[part 1 of 2: package /ECUCompositionTypes]
AUTOSAR XML (schema 4-0-3)
package /ECUCompositionTypes
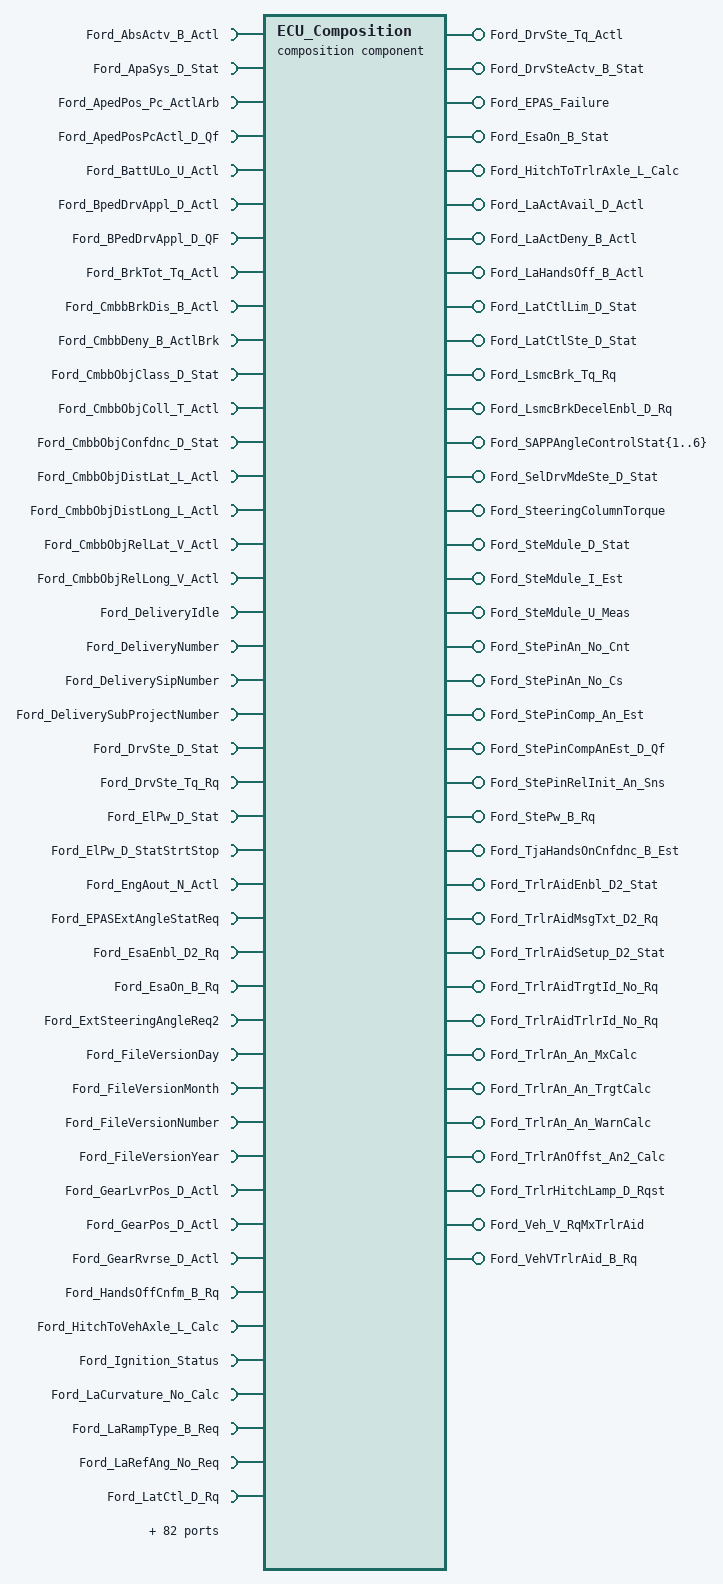
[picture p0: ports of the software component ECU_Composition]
  composition sw component type ECU_Composition
    42 x provide port:
      Ford_DrvSte_Tq_Actl: nonqueued-sender-com-spec{data-element=Ford_DrvSte_Tq_Actl, init-value=128}, provided-interface=Ford_DrvSte_Tq_Actl
      Ford_DrvSteActv_B_Stat: nonqueued-sender-com-spec{data-element=Ford_DrvSteActv_B_Stat, init-value=0}, provided-interface=Ford_DrvSteActv_B_Stat
      Ford_EPAS_Failure: nonqueued-sender-com-spec{data-element=Ford_EPAS_Failure, init-value=0}, provided-interface=Ford_EPAS_Failure
      Ford_EsaOn_B_Stat: provided-interface=Ford_EsaOn_B_Stat
      Ford_HitchToTrlrAxle_L_Calc: nonqueued-sender-com-spec{data-element=Ford_HitchToTrlrAxle_L_Calc, init-value=0}, provided-interface=Ford_HitchToTrlrAxle_L_Calc
      Ford_LaActAvail_D_Actl: nonqueued-sender-com-spec{data-element=Ford_LaActAvail_D_Actl, init-value=0}, provided-interface=Ford_LaActAvail_D_Actl
      Ford_LaActDeny_B_Actl: nonqueued-sender-com-spec{data-element=Ford_LaActDeny_B_Actl, init-value=0}, provided-interface=Ford_LaActDeny_B_Actl
      Ford_LaHandsOff_B_Actl: nonqueued-sender-com-spec{data-element=Ford_LaHandsOff_B_Actl, init-value=1}, provided-interface=Ford_LaHandsOff_B_Actl
      Ford_LatCtlLim_D_Stat: nonqueued-sender-com-spec{data-element=Ford_LatCtlLim_D_Stat, init-value=0}, provided-interface=Ford_LatCtlLim_D_Stat
      Ford_LatCtlSte_D_Stat: nonqueued-sender-com-spec{data-element=Ford_LatCtlSte_D_Stat, init-value=0}, provided-interface=Ford_LatCtlSte_D_Stat
      Ford_LsmcBrk_Tq_Rq: nonqueued-sender-com-spec{data-element=Ford_LsmcBrk_Tq_Rq, init-value=0}, provided-interface=Ford_LsmcBrk_Tq_Rq
      Ford_LsmcBrkDecelEnbl_D_Rq: nonqueued-sender-com-spec{data-element=Ford_LsmcBrkDecelEnbl_D_Rq, init-value=0}, provided-interface=Ford_LsmcBrkDecelEnbl_D_Rq
      Ford_SAPPAngleControlStat{1..6}: nonqueued-sender-com-spec{data-element=Ford_SAPPAngleControlStat{1..6}, init-value=0}, provided-interface=Ford_SAPPAngleControlStat{1..6}
      Ford_SelDrvMdeSte_D_Stat: nonqueued-sender-com-spec{data-element=Ford_SelDrvMdeSte_D_Stat, init-value=0}, provided-interface=Ford_SelDrvMdeSte_D_Stat
      Ford_SteeringColumnTorque: nonqueued-sender-com-spec{data-element=Ford_SteeringColumnTorque, init-value=254}, provided-interface=Ford_SteeringColumnTorque
      Ford_SteMdule_D_Stat: nonqueued-sender-com-spec{data-element=Ford_SteMdule_D_Stat, init-value=0}, provided-interface=Ford_SteMdule_D_Stat
      Ford_SteMdule_I_Est: nonqueued-sender-com-spec{data-element=Ford_SteMdule_I_Est, init-value=4095}, provided-interface=Ford_SteMdule_I_Est
      Ford_SteMdule_U_Meas: nonqueued-sender-com-spec{data-element=Ford_SteMdule_U_Meas, init-value=255}, provided-interface=Ford_SteMdule_U_Meas
      Ford_StePinAn_No_Cnt: nonqueued-sender-com-spec{data-element=Ford_StePinAn_No_Cnt, init-value=0}, provided-interface=Ford_StePinAn_No_Cnt
      Ford_StePinAn_No_Cs: nonqueued-sender-com-spec{data-element=Ford_StePinAn_No_Cs, init-value=0}, provided-interface=Ford_StePinAn_No_Cs
      Ford_StePinComp_An_Est: nonqueued-sender-com-spec{data-element=Ford_StePinComp_An_Est, init-value=16000}, provided-interface=Ford_StePinComp_An_Est
      Ford_StePinCompAnEst_D_Qf: nonqueued-sender-com-spec{data-element=Ford_StePinCompAnEst_D_Qf, init-value=1}, provided-interface=Ford_StePinCompAnEst_D_Qf
      Ford_StePinRelInit_An_Sns: nonqueued-sender-com-spec{data-element=Ford_StePinRelInit_An_Sns, init-value=65535}, provided-interface=Ford_StePinRelInit_An_Sns
      Ford_StePw_B_Rq: nonqueued-sender-com-spec{data-element=Ford_StePw_B_Rq, init-value=0}, provided-interface=Ford_StePw_B_Rq
      Ford_TjaHandsOnCnfdnc_B_Est: nonqueued-sender-com-spec{data-element=Ford_TjaHandsOnCnfdnc_B_Est, init-value=1}, provided-interface=Ford_TjaHandsOnCnfdnc_B_Est
      Ford_TrlrAidEnbl_D2_Stat: nonqueued-sender-com-spec{data-element=Ford_TrlrAidEnbl_D2_Stat, init-value=0}, provided-interface=Ford_TrlrAidEnbl_D2_Stat
      Ford_TrlrAidMsgTxt_D2_Rq: nonqueued-sender-com-spec{data-element=Ford_TrlrAidMsgTxt_D2_Rq, init-value=0}, provided-interface=Ford_TrlrAidMsgTxt_D2_Rq
      Ford_TrlrAidSetup_D2_Stat: nonqueued-sender-com-spec{data-element=Ford_TrlrAidSetup_D2_Stat, init-value=0}, provided-interface=Ford_TrlrAidSetup_D2_Stat
      Ford_TrlrAidTrgtId_No_Rq: nonqueued-sender-com-spec{data-element=Ford_TrlrAidTrgtId_No_Rq, init-value=0}, provided-interface=Ford_TrlrAidTrgtId_No_Rq
      Ford_TrlrAidTrlrId_No_Rq: nonqueued-sender-com-spec{data-element=Ford_TrlrAidTrlrId_No_Rq, init-value=0}, provided-interface=Ford_TrlrAidTrlrId_No_Rq
      Ford_TrlrAn_An_MxCalc: nonqueued-sender-com-spec{data-element=Ford_TrlrAn_An_MxCalc, init-value=0}, provided-interface=Ford_TrlrAn_An_MxCalc
      Ford_TrlrAn_An_TrgtCalc: nonqueued-sender-com-spec{data-element=Ford_TrlrAn_An_TrgtCalc, init-value=128}, provided-interface=Ford_TrlrAn_An_TrgtCalc
      Ford_TrlrAn_An_WarnCalc: nonqueued-sender-com-spec{data-element=Ford_TrlrAn_An_WarnCalc, init-value=0}, provided-interface=Ford_TrlrAn_An_WarnCalc
      Ford_TrlrAnOffst_An2_Calc: nonqueued-sender-com-spec{data-element=Ford_TrlrAnOffst_An2_Calc, init-value=128}, provided-interface=Ford_TrlrAnOffst_An2_Calc
      Ford_TrlrHitchLamp_D_Rqst: nonqueued-sender-com-spec{data-element=Ford_TrlrHitchLamp_D_Rqst, init-value=0}, provided-interface=Ford_TrlrHitchLamp_D_Rqst
      Ford_Veh_V_RqMxTrlrAid: nonqueued-sender-com-spec{data-element=Ford_Veh_V_RqMxTrlrAid, init-value=255}, provided-interface=Ford_Veh_V_RqMxTrlrAid
      Ford_VehVTrlrAid_B_Rq: nonqueued-sender-com-spec{data-element=Ford_VehVTrlrAid_B_Rq, init-value=0}, provided-interface=Ford_VehVTrlrAid_B_Rq
    126 x require port:
      Ford_AbsActv_B_Actl: nonqueued-receiver-com-spec{data-element=Ford_AbsActv_B_Actl, filter=data-filter-type=ALWAYS, init-value=0}, required-interface=Ford_AbsActv_B_Actl
      Ford_ApaSys_D_Stat: nonqueued-receiver-com-spec{data-element=Ford_ApaSys_D_Stat, filter=data-filter-type=ALWAYS, init-value=0}, required-interface=Ford_ApaSys_D_Stat
      Ford_ApedPos_Pc_ActlArb: nonqueued-receiver-com-spec{data-element=Ford_ApedPos_Pc_ActlArb, filter=data-filter-type=ALWAYS, init-value=0}, required-interface=Ford_ApedPos_Pc_ActlArb
      Ford_ApedPosPcActl_D_Qf: nonqueued-receiver-com-spec{data-element=Ford_ApedPosPcActl_D_Qf, filter=data-filter-type=ALWAYS, init-value=1}, required-interface=Ford_ApedPosPcActl_D_Qf
      Ford_BattULo_U_Actl: nonqueued-receiver-com-spec{data-element=Ford_BattULo_U_Actl, filter=data-filter-type=ALWAYS, init-value=255}, required-interface=Ford_BattULo_U_Actl
      Ford_BpedDrvAppl_D_Actl: nonqueued-receiver-com-spec{data-element=Ford_BpedDrvAppl_D_Actl, filter=data-filter-type=ALWAYS, init-value=1}, required-interface=Ford_BpedDrvAppl_D_Actl
      Ford_BPedDrvAppl_D_QF: nonqueued-receiver-com-spec{data-element=Ford_BPedDrvAppl_D_QF, filter=data-filter-type=ALWAYS, init-value=1}, required-interface=Ford_BPedDrvAppl_D_QF
      Ford_BrkTot_Tq_Actl: nonqueued-receiver-com-spec{data-element=Ford_BrkTot_Tq_Actl, filter=data-filter-type=ALWAYS, init-value=0}, required-interface=Ford_BrkTot_Tq_Actl
      Ford_CmbbBrkDis_B_Actl: nonqueued-receiver-com-spec{data-element=Ford_CmbbBrkDis_B_Actl, filter=data-filter-type=ALWAYS, init-value=0}, required-interface=Ford_CmbbBrkDis_B_Actl
      Ford_CmbbDeny_B_ActlBrk: nonqueued-receiver-com-spec{data-element=Ford_CmbbDeny_B_ActlBrk, filter=data-filter-type=ALWAYS, init-value=0}, required-interface=Ford_CmbbDeny_B_ActlBrk
      Ford_CmbbObjClass_D_Stat: nonqueued-receiver-com-spec{data-element=Ford_CmbbObjClass_D_Stat, filter=data-filter-type=ALWAYS, init-value=0}, required-interface=Ford_CmbbObjClass_D_Stat
      Ford_CmbbObjColl_T_Actl: nonqueued-receiver-com-spec{data-element=Ford_CmbbObjColl_T_Actl, filter=data-filter-type=ALWAYS, init-value=126}, required-interface=Ford_CmbbObjColl_T_Actl
      Ford_CmbbObjConfdnc_D_Stat: nonqueued-receiver-com-spec{data-element=Ford_CmbbObjConfdnc_D_Stat, filter=data-filter-type=ALWAYS, init-value=0}, required-interface=Ford_CmbbObjConfdnc_D_Stat
      Ford_CmbbObjDistLat_L_Actl: nonqueued-receiver-com-spec{data-element=Ford_CmbbObjDistLat_L_Actl, filter=data-filter-type=ALWAYS, init-value=510}, required-interface=Ford_CmbbObjDistLat_L_Actl
      Ford_CmbbObjDistLong_L_Actl: nonqueued-receiver-com-spec{data-element=Ford_CmbbObjDistLong_L_Actl, filter=data-filter-type=ALWAYS, init-value=1022}, required-interface=Ford_CmbbObjDistLong_L_Actl
      Ford_CmbbObjRelLat_V_Actl: nonqueued-receiver-com-spec{data-element=Ford_CmbbObjRelLat_V_Actl, filter=data-filter-type=ALWAYS, init-value=510}, required-interface=Ford_CmbbObjRelLat_V_Actl
      Ford_CmbbObjRelLong_V_Actl: nonqueued-receiver-com-spec{data-element=Ford_CmbbObjRelLong_V_Actl, filter=data-filter-type=ALWAYS, init-value=1022}, required-interface=Ford_CmbbObjRelLong_V_Actl
      Ford_DeliveryIdle: nonqueued-receiver-com-spec{data-element=Ford_DeliveryIdle, filter=data-filter-type=ALWAYS, init-value=0}, required-interface=Ford_DeliveryIdle
      Ford_DeliveryNumber: nonqueued-receiver-com-spec{data-element=Ford_DeliveryNumber, filter=data-filter-type=ALWAYS, init-value=0}, required-interface=Ford_DeliveryNumber
      Ford_DeliverySipNumber: nonqueued-receiver-com-spec{data-element=Ford_DeliverySipNumber, filter=data-filter-type=ALWAYS, init-value=1507332}, required-interface=Ford_DeliverySipNumber
      Ford_DeliverySubProjectNumber: nonqueued-receiver-com-spec{data-element=Ford_DeliverySubProjectNumber, filter=data-filter-type=ALWAYS, init-value=23072854}, required-interface=Ford_DeliverySubProjectNumber
      Ford_DrvSte_D_Stat: nonqueued-receiver-com-spec{data-element=Ford_DrvSte_D_Stat, filter=data-filter-type=ALWAYS, init-value=0}, required-interface=Ford_DrvSte_D_Stat
      Ford_DrvSte_Tq_Rq: nonqueued-receiver-com-spec{data-element=Ford_DrvSte_Tq_Rq, filter=data-filter-type=ALWAYS, init-value=128}, required-interface=Ford_DrvSte_Tq_Rq
      Ford_ElPw_D_Stat: nonqueued-receiver-com-spec{data-element=Ford_ElPw_D_Stat, filter=data-filter-type=ALWAYS, init-value=0}, required-interface=Ford_ElPw_D_Stat
      Ford_ElPw_D_StatStrtStop: nonqueued-receiver-com-spec{data-element=Ford_ElPw_D_StatStrtStop, filter=data-filter-type=ALWAYS, init-value=0}, required-interface=Ford_ElPw_D_StatStrtStop
      Ford_EngAout_N_Actl: nonqueued-receiver-com-spec{data-element=Ford_EngAout_N_Actl, filter=data-filter-type=ALWAYS, init-value=0}, required-interface=Ford_EngAout_N_Actl
      Ford_EPASExtAngleStatReq: nonqueued-receiver-com-spec{data-element=Ford_EPASExtAngleStatReq, filter=data-filter-type=ALWAYS, init-value=0}, required-interface=Ford_EPASExtAngleStatReq
      Ford_EsaEnbl_D2_Rq: nonqueued-receiver-com-spec{data-element=Ford_EsaEnbl_D2_Rq, filter=data-filter-type=ALWAYS, init-value=0}, required-interface=Ford_EsaEnbl_D2_Rq
      Ford_EsaOn_B_Rq: nonqueued-receiver-com-spec{data-element=Ford_EsaOn_B_Rq, filter=data-filter-type=ALWAYS, init-value=1}, required-interface=Ford_EsaOn_B_Rq
      Ford_ExtSteeringAngleReq2: nonqueued-receiver-com-spec{data-element=Ford_ExtSteeringAngleReq2, filter=data-filter-type=ALWAYS, init-value=0}, required-interface=Ford_ExtSteeringAngleReq2
      Ford_FileVersionDay: nonqueued-receiver-com-spec{data-element=Ford_FileVersionDay, filter=data-filter-type=ALWAYS, init-value=48}, required-interface=Ford_FileVersionDay
      Ford_FileVersionMonth: nonqueued-receiver-com-spec{data-element=Ford_FileVersionMonth, filter=data-filter-type=ALWAYS, init-value=17}, required-interface=Ford_FileVersionMonth
      Ford_FileVersionNumber: nonqueued-receiver-com-spec{data-element=Ford_FileVersionNumber, filter=data-filter-type=ALWAYS, init-value=5}, required-interface=Ford_FileVersionNumber
      Ford_FileVersionYear: nonqueued-receiver-com-spec{data-element=Ford_FileVersionYear, filter=data-filter-type=ALWAYS, init-value=23}, required-interface=Ford_FileVersionYear
      Ford_GearLvrPos_D_Actl: nonqueued-receiver-com-spec{data-element=Ford_GearLvrPos_D_Actl, filter=data-filter-type=ALWAYS, init-value=14}, required-interface=Ford_GearLvrPos_D_Actl
      Ford_GearPos_D_Actl: nonqueued-receiver-com-spec{data-element=Ford_GearPos_D_Actl, filter=data-filter-type=ALWAYS, init-value=15}, required-interface=Ford_GearPos_D_Actl
      Ford_GearRvrse_D_Actl: nonqueued-receiver-com-spec{data-element=Ford_GearRvrse_D_Actl, filter=data-filter-type=ALWAYS, init-value=7}, required-interface=Ford_GearRvrse_D_Actl
      Ford_HandsOffCnfm_B_Rq: nonqueued-receiver-com-spec{data-element=Ford_HandsOffCnfm_B_Rq, filter=data-filter-type=ALWAYS, init-value=0}, required-interface=Ford_HandsOffCnfm_B_Rq
      Ford_HitchToVehAxle_L_Calc: nonqueued-receiver-com-spec{data-element=Ford_HitchToVehAxle_L_Calc, filter=data-filter-type=ALWAYS, init-value=255}, required-interface=Ford_HitchToVehAxle_L_Calc
      Ford_Ignition_Status: nonqueued-receiver-com-spec{data-element=Ford_Ignition_Status, filter=data-filter-type=ALWAYS, init-value=0}, required-interface=Ford_Ignition_Status
      Ford_LaCurvature_No_Calc: nonqueued-receiver-com-spec{data-element=Ford_LaCurvature_No_Calc, filter=data-filter-type=ALWAYS, init-value=2048}, required-interface=Ford_LaCurvature_No_Calc
      Ford_LaRampType_B_Req: nonqueued-receiver-com-spec{data-element=Ford_LaRampType_B_Req, filter=data-filter-type=ALWAYS, init-value=0}, required-interface=Ford_LaRampType_B_Req
      Ford_LaRefAng_No_Req: nonqueued-receiver-com-spec{data-element=Ford_LaRefAng_No_Req, filter=data-filter-type=ALWAYS, init-value=2048}, required-interface=Ford_LaRefAng_No_Req
      Ford_LatCtl_D_Rq: nonqueued-receiver-com-spec{data-element=Ford_LatCtl_D_Rq, filter=data-filter-type=ALWAYS, init-value=0}, required-interface=Ford_LatCtl_D_Rq
      Ford_LatCtlCurv_No_Actl: nonqueued-receiver-com-spec{data-element=Ford_LatCtlCurv_No_Actl, filter=data-filter-type=ALWAYS, init-value=1000}, required-interface=Ford_LatCtlCurv_No_Actl
      Ford_LatCtlCurv_NoRate_Actl: nonqueued-receiver-com-spec{data-element=Ford_LatCtlCurv_NoRate_Actl, filter=data-filter-type=ALWAYS, init-value=4096}, required-interface=Ford_LatCtlCurv_NoRate_Actl
      Ford_LatCtlPath_An_Actl: nonqueued-receiver-com-spec{data-element=Ford_LatCtlPath_An_Actl, filter=data-filter-type=ALWAYS, init-value=1000}, required-interface=Ford_LatCtlPath_An_Actl
      Ford_LatCtlPathOffst_L_Actl: nonqueued-receiver-com-spec{data-element=Ford_LatCtlPathOffst_L_Actl, filter=data-filter-type=ALWAYS, init-value=512}, required-interface=Ford_LatCtlPathOffst_L_Actl
      Ford_LatCtlPrecision_D_Rq: nonqueued-receiver-com-spec{data-element=Ford_LatCtlPrecision_D_Rq, filter=data-filter-type=ALWAYS, init-value=0}, required-interface=Ford_LatCtlPrecision_D_Rq
      Ford_LatCtlRampType_D_Rq: nonqueued-receiver-com-spec{data-element=Ford_LatCtlRampType_D_Rq, filter=data-filter-type=ALWAYS, init-value=0}, required-interface=Ford_LatCtlRampType_D_Rq
      Ford_LatCtlRng_L_Max: nonqueued-receiver-com-spec{data-element=Ford_LatCtlRng_L_Max, filter=data-filter-type=ALWAYS, init-value=0}, required-interface=Ford_LatCtlRng_L_Max
      Ford_LdwActvIntns_D_Req: nonqueued-receiver-com-spec{data-element=Ford_LdwActvIntns_D_Req, filter=data-filter-type=ALWAYS, init-value=0}, required-interface=Ford_LdwActvIntns_D_Req
      Ford_LdwActvStats_D_Req: nonqueued-receiver-com-spec{data-element=Ford_LdwActvStats_D_Req, filter=data-filter-type=ALWAYS, init-value=0}, required-interface=Ford_LdwActvStats_D_Req
      Ford_LifeCycMde_D_Actl: nonqueued-receiver-com-spec{data-element=Ford_LifeCycMde_D_Actl, filter=data-filter-type=ALWAYS, init-value=0}, required-interface=Ford_LifeCycMde_D_Actl
      Ford_LkaActvStats_D2_Req: nonqueued-receiver-com-spec{data-element=Ford_LkaActvStats_D2_Req, filter=data-filter-type=ALWAYS, init-value=0}, required-interface=Ford_LkaActvStats_D2_Req
      Ford_LkaDrvOvrrd_D_Rq: nonqueued-receiver-com-spec{data-element=Ford_LkaDrvOvrrd_D_Rq, filter=data-filter-type=ALWAYS, init-value=0}, required-interface=Ford_LkaDrvOvrrd_D_Rq
      Ford_LsmcBrkDecel_D_Stat: nonqueued-receiver-com-spec{data-element=Ford_LsmcBrkDecel_D_Stat, filter=data-filter-type=ALWAYS, init-value=0}, required-interface=Ford_LsmcBrkDecel_D_Stat
      Ford_OdometerMasterValue: nonqueued-receiver-com-spec{data-element=Ford_OdometerMasterValue, filter=data-filter-type=ALWAYS, init-value=0}, required-interface=Ford_OdometerMasterValue
      Ford_Outside_Air_Temp_Stat: nonqueued-receiver-com-spec{data-element=Ford_Outside_Air_Temp_Stat, filter=data-filter-type=ALWAYS, init-value=254}, required-interface=Ford_Outside_Air_Temp_Stat
      Ford_PrplWhlTot2_Tq_Actl: nonqueued-receiver-com-spec{data-element=Ford_PrplWhlTot2_Tq_Actl, filter=data-filter-type=ALWAYS, init-value=0}, required-interface=Ford_PrplWhlTot2_Tq_Actl
      Ford_PwPckTq_D_Stat: nonqueued-receiver-com-spec{data-element=Ford_PwPckTq_D_Stat, filter=data-filter-type=ALWAYS, init-value=0}, required-interface=Ford_PwPckTq_D_Stat
      Ford_SelDrvMdeChassis2_D_Rq: nonqueued-receiver-com-spec{data-element=Ford_SelDrvMdeChassis2_D_Rq, filter=data-filter-type=ALWAYS, init-value=0}, required-interface=Ford_SelDrvMdeChassis2_D_Rq
      Ford_StabCtlBrkActv_B_Actl: nonqueued-receiver-com-spec{data-element=Ford_StabCtlBrkActv_B_Actl, filter=data-filter-type=ALWAYS, init-value=0}, required-interface=Ford_StabCtlBrkActv_B_Actl
      Ford_StePinOffst_An_Est: nonqueued-receiver-com-spec{data-element=Ford_StePinOffst_An_Est, filter=data-filter-type=ALWAYS, init-value=65534}, required-interface=Ford_StePinOffst_An_Est
      Ford_StePinOffst_D_Stat: nonqueued-receiver-com-spec{data-element=Ford_StePinOffst_D_Stat, filter=data-filter-type=ALWAYS, init-value=0}, required-interface=Ford_StePinOffst_D_Stat
      Ford_StePinOffst_No_Cnt: nonqueued-receiver-com-spec{data-element=Ford_StePinOffst_No_Cnt, filter=data-filter-type=ALWAYS, init-value=0}, required-interface=Ford_StePinOffst_No_Cnt
      Ford_StePinOffst_No_Cs: nonqueued-receiver-com-spec{data-element=Ford_StePinOffst_No_Cs, filter=data-filter-type=ALWAYS, init-value=0}, required-interface=Ford_StePinOffst_No_Cs
      Ford_SteWhlRelCalib_An_Sns: nonqueued-receiver-com-spec{data-element=Ford_SteWhlRelCalib_An_Sns, filter=data-filter-type=ALWAYS, init-value=0}, required-interface=Ford_SteWhlRelCalib_An_Sns
      Ford_TrlrAid_An3_Actl: nonqueued-receiver-com-spec{data-element=Ford_TrlrAid_An3_Actl, filter=data-filter-type=ALWAYS, init-value=720}, required-interface=Ford_TrlrAid_An3_Actl
      Ford_TrlrAid_AnRate2_Actl: nonqueued-receiver-com-spec{data-element=Ford_TrlrAid_AnRate2_Actl, filter=data-filter-type=ALWAYS, init-value=400}, required-interface=Ford_TrlrAid_AnRate2_Actl
      Ford_TrlrAid_D2_Stat: nonqueued-receiver-com-spec{data-element=Ford_TrlrAid_D2_Stat, filter=data-filter-type=ALWAYS, init-value=0}, required-interface=Ford_TrlrAid_D2_Stat
      Ford_TrlrAidCancl_B_Rq: nonqueued-receiver-com-spec{data-element=Ford_TrlrAidCancl_B_Rq, filter=data-filter-type=ALWAYS, init-value=0}, required-interface=Ford_TrlrAidCancl_B_Rq
      Ford_TrlrAidCtl_U_RqDrv: nonqueued-receiver-com-spec{data-element=Ford_TrlrAidCtl_U_RqDrv, filter=data-filter-type=ALWAYS, init-value=4094}, required-interface=Ford_TrlrAidCtl_U_RqDrv
      Ford_TrlrAidEnbl_D2_Rq: nonqueued-receiver-com-spec{data-element=Ford_TrlrAidEnbl_D2_Rq, filter=data-filter-type=ALWAYS, init-value=0}, required-interface=Ford_TrlrAidEnbl_D2_Rq
      Ford_TrlrAidMde_D_Rq: nonqueued-receiver-com-spec{data-element=Ford_TrlrAidMde_D_Rq, filter=data-filter-type=ALWAYS, init-value=0}, required-interface=Ford_TrlrAidMde_D_Rq
      Ford_TrlrAidSetup_D2_Rq: nonqueued-receiver-com-spec{data-element=Ford_TrlrAidSetup_D2_Rq, filter=data-filter-type=ALWAYS, init-value=0}, required-interface=Ford_TrlrAidSetup_D2_Rq
      Ford_TrlrAidSwtch_D_RqDrv: nonqueued-receiver-com-spec{data-element=Ford_TrlrAidSwtch_D_RqDrv, filter=data-filter-type=ALWAYS, init-value=0}, required-interface=Ford_TrlrAidSwtch_D_RqDrv
      Ford_TrlrAidTrgtId_No_Actl: nonqueued-receiver-com-spec{data-element=Ford_TrlrAidTrgtId_No_Actl, filter=data-filter-type=ALWAYS, init-value=0}, required-interface=Ford_TrlrAidTrgtId_No_Actl
      Ford_TrlrAnOffstDir_D_Mem: nonqueued-receiver-com-spec{data-element=Ford_TrlrAnOffstDir_D_Mem, filter=data-filter-type=ALWAYS, init-value=0}, required-interface=Ford_TrlrAnOffstDir_D_Mem
      Ford_TrlrAxleToBmpr_L_Actl: nonqueued-receiver-com-spec{data-element=Ford_TrlrAxleToBmpr_L_Actl, filter=data-filter-type=ALWAYS, init-value=0}, required-interface=Ford_TrlrAxleToBmpr_L_Actl
      Ford_TrlrBrkActCnnct_B_Actl: nonqueued-receiver-com-spec{data-element=Ford_TrlrBrkActCnnct_B_Actl, filter=data-filter-type=ALWAYS, init-value=0}, required-interface=Ford_TrlrBrkActCnnct_B_Actl
      Ford_TrlrHitchYaw_An_Actl: nonqueued-receiver-com-spec{data-element=Ford_TrlrHitchYaw_An_Actl, filter=data-filter-type=ALWAYS, init-value=4094}, required-interface=Ford_TrlrHitchYaw_An_Actl
      Ford_TrlrHitchYaw_D_Stat: nonqueued-receiver-com-spec{data-element=Ford_TrlrHitchYaw_D_Stat, filter=data-filter-type=ALWAYS, init-value=0}, required-interface=Ford_TrlrHitchYaw_D_Stat
      Ford_TrlrHitYaw_AnRate_Actl: nonqueued-receiver-com-spec{data-element=Ford_TrlrHitYaw_AnRate_Actl, filter=data-filter-type=ALWAYS, init-value=4094}, required-interface=Ford_TrlrHitYaw_AnRate_Actl
      Ford_TrlrId_No_Actl: nonqueued-receiver-com-spec{data-element=Ford_TrlrId_No_Actl, filter=data-filter-type=ALWAYS, init-value=0}, required-interface=Ford_TrlrId_No_Actl
      Ford_TrlrIdType_D_Stat: nonqueued-receiver-com-spec{data-element=Ford_TrlrIdType_D_Stat, filter=data-filter-type=ALWAYS, init-value=0}, required-interface=Ford_TrlrIdType_D_Stat
      Ford_TrlrLampCnnct_B_Actl: nonqueued-receiver-com-spec{data-element=Ford_TrlrLampCnnct_B_Actl, filter=data-filter-type=ALWAYS, init-value=0}, required-interface=Ford_TrlrLampCnnct_B_Actl
      Ford_TrlrRvrse_D_Stat: nonqueued-receiver-com-spec{data-element=Ford_TrlrRvrse_D_Stat, filter=data-filter-type=ALWAYS, init-value=0}, required-interface=Ford_TrlrRvrse_D_Stat
      Ford_TrlrRvrseCancl_B_Rq: nonqueued-receiver-com-spec{data-element=Ford_TrlrRvrseCancl_B_Rq, filter=data-filter-type=ALWAYS, init-value=0}, required-interface=Ford_TrlrRvrseCancl_B_Rq
      Ford_TrlrRvrseEnbl_D2_Stat: nonqueued-receiver-com-spec{data-element=Ford_TrlrRvrseEnbl_D2_Stat, filter=data-filter-type=ALWAYS, init-value=0}, required-interface=Ford_TrlrRvrseEnbl_D2_Stat
      Ford_TrlrRvrseMsgTxt_D2_Rq: nonqueued-receiver-com-spec{data-element=Ford_TrlrRvrseMsgTxt_D2_Rq, filter=data-filter-type=ALWAYS, init-value=0}, required-interface=Ford_TrlrRvrseMsgTxt_D2_Rq
      Ford_TrlrSnsId_No_Actl: nonqueued-receiver-com-spec{data-element=Ford_TrlrSnsId_No_Actl, filter=data-filter-type=ALWAYS}, required-interface=Ford_TrlrSnsId_No_Actl
      Ford_TrlrTrgtAcquire_D_Stat: nonqueued-receiver-com-spec{data-element=Ford_TrlrTrgtAcquire_D_Stat, filter=data-filter-type=ALWAYS, init-value=0}, required-interface=Ford_TrlrTrgtAcquire_D_Stat
      Ford_TrlrYaw_W_Actl: nonqueued-receiver-com-spec{data-element=Ford_TrlrYaw_W_Actl, filter=data-filter-type=ALWAYS, init-value=65534}, required-interface=Ford_TrlrYaw_W_Actl
      Ford_TrlrYawWActl_D_Qf: nonqueued-receiver-com-spec{data-element=Ford_TrlrYawWActl_D_Qf, filter=data-filter-type=ALWAYS, init-value=1}, required-interface=Ford_TrlrYawWActl_D_Qf
      Ford_TrnRng_D_Rq: nonqueued-receiver-com-spec{data-element=Ford_TrnRng_D_Rq, filter=data-filter-type=ALWAYS, init-value=14}, required-interface=Ford_TrnRng_D_Rq
      Ford_TurnLghtSwtch_D_Stat: nonqueued-receiver-com-spec{data-element=Ford_TurnLghtSwtch_D_Stat, filter=data-filter-type=ALWAYS, init-value=0}, required-interface=Ford_TurnLghtSwtch_D_Stat
      Ford_Veh_V_ActlBrk: nonqueued-receiver-com-spec{data-element=Ford_Veh_V_ActlBrk, filter=data-filter-type=ALWAYS, init-value=0}, required-interface=Ford_Veh_V_ActlBrk
      Ford_Veh_V_ActlEng: nonqueued-receiver-com-spec{data-element=Ford_Veh_V_ActlEng, filter=data-filter-type=ALWAYS, init-value=0}, required-interface=Ford_Veh_V_ActlEng
      Ford_VehicleGGCCData: nonqueued-receiver-com-spec{data-element=Ford_VehicleGGCCData, filter=data-filter-type=ALWAYS}, required-interface=Ford_VehicleGGCCData
      Ford_VehLatComp_A_Actl: nonqueued-receiver-com-spec{data-element=Ford_VehLatComp_A_Actl, filter=data-filter-type=ALWAYS, init-value=1022}, required-interface=Ford_VehLatComp_A_Actl
      Ford_VehLongComp_A_Actl: nonqueued-receiver-com-spec{data-element=Ford_VehLongComp_A_Actl, filter=data-filter-type=ALWAYS, init-value=1022}, required-interface=Ford_VehLongComp_A_Actl
      Ford_VehOverGnd_V_Est: nonqueued-receiver-com-spec{data-element=Ford_VehOverGnd_V_Est, filter=data-filter-type=ALWAYS, init-value=0}, required-interface=Ford_VehOverGnd_V_Est
      Ford_VehVActlBrk_D_Qf: nonqueued-receiver-com-spec{data-element=Ford_VehVActlBrk_D_Qf, filter=data-filter-type=ALWAYS, init-value=0}, required-interface=Ford_VehVActlBrk_D_Qf
      Ford_VehVActlBrk_No_Cnt: nonqueued-receiver-com-spec{data-element=Ford_VehVActlBrk_No_Cnt, filter=data-filter-type=ALWAYS, init-value=0}, required-interface=Ford_VehVActlBrk_No_Cnt
      Ford_VehVActlBrk_No_Cs: nonqueued-receiver-com-spec{data-element=Ford_VehVActlBrk_No_Cs, filter=data-filter-type=ALWAYS, init-value=0}, required-interface=Ford_VehVActlBrk_No_Cs
      Ford_VehVActlEng_D_Qf: nonqueued-receiver-com-spec{data-element=Ford_VehVActlEng_D_Qf, filter=data-filter-type=ALWAYS, init-value=0}, required-interface=Ford_VehVActlEng_D_Qf
      Ford_VehVActlEng_No_Cnt: nonqueued-receiver-com-spec{data-element=Ford_VehVActlEng_No_Cnt, filter=data-filter-type=ALWAYS, init-value=0}, required-interface=Ford_VehVActlEng_No_Cnt
      Ford_VehVActlEng_No_Cs: nonqueued-receiver-com-spec{data-element=Ford_VehVActlEng_No_Cs, filter=data-filter-type=ALWAYS, init-value=0}, required-interface=Ford_VehVActlEng_No_Cs
      Ford_VehVertComp_A_Actl: nonqueued-receiver-com-spec{data-element=Ford_VehVertComp_A_Actl, filter=data-filter-type=ALWAYS, init-value=1022}, required-interface=Ford_VehVertComp_A_Actl
      Ford_VehVTrlrAid_B_Avail: nonqueued-receiver-com-spec{data-element=Ford_VehVTrlrAid_B_Avail, filter=data-filter-type=ALWAYS, init-value=0}, required-interface=Ford_VehVTrlrAid_B_Avail
      Ford_VehYaw_W_Actl: required-interface=Ford_VehYaw_W_Actl
      Ford_VehYawComp_W_Actl: nonqueued-receiver-com-spec{data-element=Ford_VehYawComp_W_Actl, filter=data-filter-type=ALWAYS, init-value=4094}, required-interface=Ford_VehYawComp_W_Actl
      Ford_WhlDirFl_D_Actl: nonqueued-receiver-com-spec{data-element=Ford_WhlDirFl_D_Actl, filter=data-filter-type=ALWAYS, init-value=0}, required-interface=Ford_WhlDirFl_D_Actl
      Ford_WhlDirFr_D_Actl: nonqueued-receiver-com-spec{data-element=Ford_WhlDirFr_D_Actl, filter=data-filter-type=ALWAYS, init-value=0}, required-interface=Ford_WhlDirFr_D_Actl
      Ford_WhlDirRl_D_Actl: nonqueued-receiver-com-spec{data-element=Ford_WhlDirRl_D_Actl, filter=data-filter-type=ALWAYS, init-value=0}, required-interface=Ford_WhlDirRl_D_Actl
      Ford_WhlDirRr_D_Actl: nonqueued-receiver-com-spec{data-element=Ford_WhlDirRr_D_Actl, filter=data-filter-type=ALWAYS, init-value=0}, required-interface=Ford_WhlDirRr_D_Actl
      Ford_WhlFl_W_Meas: nonqueued-receiver-com-spec{data-element=Ford_WhlFl_W_Meas, filter=data-filter-type=ALWAYS, init-value=0}, required-interface=Ford_WhlFl_W_Meas
      Ford_WhlFr_W_Meas: nonqueued-receiver-com-spec{data-element=Ford_WhlFr_W_Meas, filter=data-filter-type=ALWAYS, init-value=0}, required-interface=Ford_WhlFr_W_Meas
      Ford_WhlRl_W_Meas: nonqueued-receiver-com-spec{data-element=Ford_WhlRl_W_Meas, filter=data-filter-type=ALWAYS, init-value=0}, required-interface=Ford_WhlRl_W_Meas
      Ford_WhlRotatFl_No_Cnt: nonqueued-receiver-com-spec{data-element=Ford_WhlRotatFl_No_Cnt, filter=data-filter-type=ALWAYS, init-value=0}, required-interface=Ford_WhlRotatFl_No_Cnt
      Ford_WhlRotatFr_No_Cnt: nonqueued-receiver-com-spec{data-element=Ford_WhlRotatFr_No_Cnt, filter=data-filter-type=ALWAYS, init-value=0}, required-interface=Ford_WhlRotatFr_No_Cnt
      Ford_WhlRotatRl_No_Cnt: nonqueued-receiver-com-spec{data-element=Ford_WhlRotatRl_No_Cnt, filter=data-filter-type=ALWAYS, init-value=0}, required-interface=Ford_WhlRotatRl_No_Cnt
      Ford_WhlRotatRr_No_Cnt: nonqueued-receiver-com-spec{data-element=Ford_WhlRotatRr_No_Cnt, filter=data-filter-type=ALWAYS, init-value=0}, required-interface=Ford_WhlRotatRr_No_Cnt
      Ford_WhlRr_W_Meas: nonqueued-receiver-com-spec{data-element=Ford_WhlRr_W_Meas, filter=data-filter-type=ALWAYS, init-value=0}, required-interface=Ford_WhlRr_W_Meas
      Ford_YawStabilityIndex: nonqueued-receiver-com-spec{data-element=Ford_YawStabilityIndex, filter=data-filter-type=ALWAYS, init-value=256}, required-interface=Ford_YawStabilityIndex
    209 x component:
      AAACalRegn01Rt{00..05}_Dummy: type=AAACalRegn01Rt01_Dummy
      AAACalRegn02Rt00GroupA_Dummy: type=AAACalRegn02Rt01GroupA_Dummy
      AAACalRegn02Rt00GroupB_Dummy: type=AAACalRegn02Rt01GroupB_Dummy
      AAACalRegn02Rt01GroupA_Dummy: type=AAACalRegn02Rt01GroupA_Dummy
      AAACalRegn02Rt01GroupB_Dummy: type=AAACalRegn02Rt01GroupB_Dummy
      AAACalRegn02Rt02GroupA_Dummy: type=AAACalRegn02Rt01GroupA_Dummy
      AAACalRegn02Rt02GroupB_Dummy: type=AAACalRegn02Rt01GroupB_Dummy
      AAACalRegn02Rt03GroupA_Dummy: type=AAACalRegn02Rt01GroupA_Dummy
      AAACalRegn02Rt03GroupB_Dummy: type=AAACalRegn02Rt01GroupB_Dummy
      AAACalRegn02Rt04GroupA_Dummy: type=AAACalRegn02Rt01GroupA_Dummy
      AAACalRegn02Rt04GroupB_Dummy: type=AAACalRegn02Rt01GroupB_Dummy
      AAACalRegn02Rt05GroupA_Dummy: type=AAACalRegn02Rt01GroupA_Dummy
      AAACalRegn02Rt05GroupB_Dummy: type=AAACalRegn02Rt01GroupB_Dummy
      Adcf1CfgAndUse: type=Adcf1CfgAndUse
      Assi: type=Assi
      AssiHiFrq: type=AssiHiFrq
      AssiPahSum: type=AssiPahSum
      AssiSumLim: type=AssiSumLim
      BattVltg: type=BattVltg
      BattVltgCorrln: type=BattVltgCorrln
      CalRegn01Cmn: type=CalRegn01Cmn
      CalRegn01CmnGroupA: type=CalRegn01CmnGroupA
      CalRegn01Inin00: type=CalRegn01Inin00
      CalRegn01Inin00GroupA: type=CalRegn01Inin00GroupA
      CalRegn01Inin00GroupB: type=CalRegn01Inin00GroupB
      CalRegn01Inin00GroupD: type=CalRegn01Inin00GroupD
      CalRegn01Rt{00..05}: type=CalRegn01Rt{00..05}
      CalRegn02Cmn: type=CalRegn02Cmn
      CalRegn02CmnGroupA: type=CalRegn02CmnGroupA
      CalRegn02CmnGroupB: type=CalRegn02CmnGroupB
      CalRegn02Inin00: type=CalRegn02Inin00
      CalRegn02Inin00GroupA: type=CalRegn02Inin00GroupA
      CalRegn02Inin00GroupB: type=CalRegn02Inin00GroupB
      CalRegn02Rt00GroupA: type=CalRegn02Rt00GroupA
      CalRegn02Rt00GroupB: type=CalRegn02Rt00GroupB
      CalRegn02Rt01GroupA: type=CalRegn02Rt01GroupA
      CalRegn02Rt01GroupB: type=CalRegn02Rt01GroupB
      CalRegn02Rt02GroupA: type=CalRegn02Rt02GroupA
      CalRegn02Rt02GroupB: type=CalRegn02Rt02GroupB
      CalRegn02Rt03GroupA: type=CalRegn02Rt03GroupA
      CalRegn02Rt03GroupB: type=CalRegn02Rt03GroupB
      CalRegn02Rt04GroupA: type=CalRegn02Rt04GroupA
      CalRegn02Rt04GroupB: type=CalRegn02Rt04GroupB
      CalRegn02Rt05GroupA: type=CalRegn02Rt05GroupA
      CalRegn02Rt05GroupB: type=CalRegn02Rt05GroupB
      CDD_Adcf0CfgAndUse: type=CDD_Adcf0CfgAndUse
      CDD_ChkPtAppl10: type=CDD_ChkPtAppl10
      CDD_ClkCfgAndMon: type=CDD_ClkCfgAndMon
      CDD_CoreVltgMonr: type=CDD_CoreVltgMonr
      CDD_CurrMeas: type=CDD_CurrMeas
      CDD_CurrMeasArbn: type=CDD_CurrMeasArbn
      CDD_DmaCfgAndUse: type=CDD_DmaCfgAndUse
      CDD_EcmOutpAndDiagc: type=CDD_EcmOutpAndDiagc
      CDD_ExcpnHndlg: type=CDD_ExcpnHndlg
      CDD_FlsMem: type=CDD_FlsMem
      CDD_FordBlaBoxIfCmn: type=CDD_FordBlaBoxIfCmn
      CDD_FordBlaBoxIfCmp1: type=CDD_FordBlaBoxIfCmp1
      CDD_FordBlaBoxIfCmp2: type=CDD_FordBlaBoxIfCmp2
      CDD_FordT3T6McuCfg: type=CDD_FordT3T6McuCfg
      CDD_GtmCfgAndUse: type=CDD_GtmCfgAndUse
      CDD_GuardCfgAndDiagc: type=CDD_GuardCfgAndDiagc
      CDD_HwTq1Meas: type=CDD_HwTq1Meas
      CDD_HwTq8Meas: type=CDD_HwTq8Meas
      CDD_McuCoreCfgAndDiagc: type=CDD_McuCoreCfgAndDiagc
      CDD_McuDiagc: type=CDD_McuDiagc
      CDD_MotAg5Meas: type=CDD_MotAg5Meas
      CDD_MotAg6Meas: type=CDD_MotAg6Meas
      CDD_MotAgArbn: type=CDD_MotAgArbn
      CDD_MotAgCmp: type=CDD_MotAgCmp
      CDD_MotAgSwCal: type=CDD_MotAgSwCal
      CDD_MotCtrlMgr: type=CDD_MotCtrlMgr
      CDD_MotCurrRegVltgLimr: type=CDD_MotCurrRegVltgLimr
      CDD_MotRplCoggCmd: type=CDD_MotRplCoggCmd
      CDD_MotVel: type=CDD_MotVel
      CDD_NvMProxy: type=CDD_NvMProxy
      CDD_NxtrTi: type=CDD_NxtrTi
      CDD_RamMem: type=CDD_RamMem
      CDD_SinVltgGenn: type=CDD_SinVltgGenn
      CDD_SyncCrc: type=CDD_SyncCrc
      CDD_Uart0CfgAndUse: type=CDD_Uart0CfgAndUse
      CDD_Uart1CfgAndUse: type=CDD_Uart1CfgAndUse
      CDD_VrfyCritReg: type=CDD_VrfyCritReg
      CDD_XcpIf: type=CDD_XcpIf
      CmnMfgSrv: type=CmnMfgSrv
      CmplncErr: type=CmplncErr
      CurrMeasCorrln: type=CurrMeasCorrln
      CustDiag: type=CustDiag
      Dampg: type=Dampg
      DampgPahSum: type=DampgPahSum
      DiagcMgr: type=DiagcMgr
      DiagcMgrProxyAppl10: type=DiagcMgrProxyAppl10
      DiagcMgrStub: type=DiagcMgrStub
      DiagSrv: type=DiagSrv
      DrvrTqEstimn: type=DrvrTqEstimn
      DualCtrlrOutpMgr: type=DualCtrlrOutpMgr
      DualEcuIdn: type=DualEcuIdn
      DutyCycThermProtn: type=DutyCycThermProtn
      EcuTMeas: type=EcuTMeas
      ElecPwrCns: type=ElecPwrCns
      EotLrng: type=EotLrng
      EotProtn: type=EotProtn
      EotProtnFwl: type=EotProtnFwl
      FltInj: type=FltInj
      FordCanDtcInhb: type=FordCanDtcInhb
      FordCmdArbn: type=FordCmdArbn
      FordDualEcuFltDiagcCom: type=FordDualEcuFltDiagcCom
      FordHwAgArbn: type=FordHwAgArbn
      FordHwTqCdng: type=FordHwTqCdng
      FordHwTqCmdOvrlLimr: type=FordHwTqCmdOvrlLimr
      FordMotTqCmdOvrlLimr: type=FordMotTqCmdOvrlLimr
      FordMsg077BusHiSpd: type=FordMsg077BusHiSpd
      FordMsg07DBusHiSpd: type=FordMsg07DBusHiSpd
      FordMsg07EBusHiSpd: type=FordMsg07EBusHiSpd
      FordMsg082BusHiSpd: type=FordMsg082BusHiSpd
      FordMsg083BusHiSpd: type=FordMsg083BusHiSpd
      FordMsg091BusHiSpd: type=FordMsg091BusHiSpd
      FordMsg167BusHiSpd: type=FordMsg167BusHiSpd
      FordMsg202BusHiSpd: type=FordMsg202BusHiSpd
      FordMsg213BusHiSpd: type=FordMsg213BusHiSpd
      FordMsg{215..217}BusHiSpd: type=FordMsg{215..217}BusHiSpd
      FordMsg230BusHiSpd: type=FordMsg230BusHiSpd
      FordMsg2FDBusHiSpd: type=FordMsg2FDBusHiSpd
      FordMsg3B3BusHiSpd: type=FordMsg3B3BusHiSpd
      FordMsg3CABusHiSpd: type=FordMsg3CABusHiSpd
      FordMsg3CCBusHiSpd: type=FordMsg3CCBusHiSpd
      FordMsg3D3BusHiSpd: type=FordMsg3D3BusHiSpd
      FordMsg3D7BusHiSpd: type=FordMsg3D7BusHiSpd
      FordMsg40ABusHiSpd: type=FordMsg40ABusHiSpd
      FordMsg414BusHiSpd: type=FordMsg414BusHiSpd
      FordMsg415BusHiSpd: type=FordMsg415BusHiSpd
      FordMsg417BusHiSpd: type=FordMsg417BusHiSpd
      FordMsg41ABusHiSpd: type=FordMsg41ABusHiSpd
      FordMsg41EBusHiSpd: type=FordMsg41EBusHiSpd
      FordMsg430BusHiSpd: type=FordMsg430BusHiSpd
      FordMsg443BusHiSpd: type=FordMsg443BusHiSpd
      FordMsg459BusHiSpd: type=FordMsg459BusHiSpd
      FordMsg47ABusHiSpd: type=FordMsg47ABusHiSpd
      FordMsg4B0BusHiSpd: type=FordMsg4B0BusHiSpd
      FordMsg5B5BusHiSpd: type=FordMsg5B5BusHiSpd
      FordSysSt: type=FordSysSt
      FordVehSpdArbn: type=FordVehSpdArbn
      FordVltgIf: type=FordVltgIf
      GateDrv0Ctrl: type=GateDrv0Ctrl
      HiLoadStallLimr: type=HiLoadStallLimr
      HwAg1Meas: type=HwAg1Meas
      HwAgArbn: type=HwAgArbn
      HwAgCorrln: type=HwAgCorrln
      HwAgSnsrls: type=HwAgSnsrls
      HwAgSysArbn: type=HwAgSysArbn
      HwTq10Meas: type=HwTq10Meas
      HwTq9Meas: type=HwTq9Meas
      HwTqArbn: type=HwTqArbn
      HwTqCorrln: type=HwTqCorrln
      HysCmp: type=HysCmp
      ImcArbn: type=ImcArbn
      ImcSigArbn: type=ImcSigArbn
      InertiaCmpVel: type=InertiaCmpVel
      IoHwAb: type=IoHwAb
      LimrCdng: type=LimrCdng
      LoaMgr: type=LoaMgr
      MotAg2Meas: type=MotAg2Meas
      MotAgCorrln: type=MotAgCorrln
      MotCtrlPrmEstimn: type=MotCtrlPrmEstimn
      MotCurrPeakEstimn: type=MotCurrPeakEstimn
      MotCurrRegCfg: type=MotCurrRegCfg
      MotQuadDetn: type=MotQuadDetn
      MotRefMdl: type=MotRefMdl
      MotRplCoggCfg: type=MotRplCoggCfg
      MotTqCmdSca: type=MotTqCmdSca
      MotTqTranlDampg: type=MotTqTranlDampg
      MotVelCtrl: type=MotVelCtrl
      NxtrCalIds: type=NxtrCalIds
      NxtrMath: type=NxtrMath
      NxtrSwIds: type=NxtrSwIds
      PolarityCfg: type=PolarityCfg
      PosnTrakgServo: type=PosnTrakgServo
      PwrDiscnct: type=PwrDiscnct
      PwrLimr: type=PwrLimr
      PwrSply: type=PwrSply
      PwrUpSeq: type=PwrUpSeq
      Rtn: type=Rtn
      RtnPahFwl: type=RtnPahFwl
      ShtdwnMech: type=ShtdwnMech
      StabyCmp: type=StabyCmp
      StackMeas: type=StackMeas
      StOutpCtrl: type=StOutpCtrl
      Swp: type=Swp
      SysFricLrng: type=SysFricLrng
      SysPrfmncSts: type=SysPrfmncSts
      SysStMod: type=SysStMod
      TEstimn: type=TEstimn
      TmplMonr: type=TmplMonr
      TqLoa: type=TqLoa
      TunSelnAuthy: type=TunSelnAuthy
      TunSelnMngt: type=TunSelnMngt
      VehSigCdng: type=VehSigCdng
      VehSpdLimr: type=VehSpdLimr
    connect Adcf1CfgAndUse.Adcf1EnaCnvn -> CDD_DmaCfgAndUse.Adc1CfgAndUseAdc1EnaCnvn
    connect Assi.AssiCmdBas -> AssiPahSum.AssiCmdBas
    connect Assi.AssiCmdBas -> Dampg.AssiCmdBas
    connect Assi.AssiCmdBas -> FordHwTqCdng.AssiCmdBas
    connect Assi.AssiCmdBas -> HysCmp.AssiCmdBas
    connect Assi.AssiCmdBas -> InertiaCmpVel.AssiCmdBas
    connect AssiHiFrq.AssiHiFrqCmd -> AssiPahSum.AssiHiFrqCmd
    connect AssiPahSum.AssiCmdSum -> StabyCmp.AssiCmdSum
    connect AssiSumLim.SetManTqCmd -> CmnMfgSrv.SetManTqCmd
    connect AssiSumLim.MotTqCmdLimdPreStall -> HiLoadStallLimr.MotTqCmdLimdPreStall
    connect AssiSumLim.SetManTqCmd -> MotVelCtrl.SetManTqCmd
    connect AssiSumLim.MotTqCmd -> Swp.MotTqCmd
    connect BattVltg.BrdgVltg -> CDD_CurrMeas.BrdgVltg
    connect BattVltg.BrdgVltg -> CDD_MotCtrlMgr.BrdgVltg
    connect BattVltg.BrdgVltg -> CmnMfgSrv.BrdgVltg
    connect BattVltg.BrdgVltg -> DiagcMgr.BrdgVltg
    connect BattVltg.BrdgVltg -> ElecPwrCns.BrdgVltg
    connect BattVltg.BrdgVltg -> FordCanDtcInhb.FordBattVltgEstimn
    connect BattVltg.BrdgVltg -> FordVltgIf.BattVltg
    connect BattVltg.BrdgVltg -> ImcArbn.BattVltg
    connect BattVltg.BrdgVltg -> MotRefMdl.BrdgVltg
    connect BattVltg.BrdgVltg -> PwrLimr.BrdgVltg
    connect BattVltgCorrln.BattSwdVltgCorrlnSts -> BattVltg.BattSwdVltgCorrlnSts
    connect CalRegn01Cmn.AssiSumLimCmdSumFilActv -> AssiSumLim.AssiSumLimCmdSumFilActv
    connect CalRegn01Cmn.AssiSumLimNtc0x0C4FailStep -> AssiSumLim.AssiSumLimNtc0x0C4FailStep
    connect CalRegn01Cmn.AssiSumLimNtc0x0C4PassStep -> AssiSumLim.AssiSumLimNtc0x0C4PassStep
    connect CalRegn01Cmn.AssiSumLimPullCmpLim -> AssiSumLim.AssiSumLimPullCmpLim
    connect CalRegn01Cmn.BattVltgSwdMax -> BattVltg.BattVltgSwdMax
    connect CalRegn01Cmn.BattVltgCorrlnAllwdVltgDif -> BattVltgCorrln.BattVltgCorrlnAllwdVltgDif
    connect CalRegn01Cmn.BattVltgCorrlnBattLoVltg -> BattVltgCorrln.BattVltgCorrlnBattLoVltg
    connect CalRegn01Cmn.BattVltgCorrlnBattOverVltg -> BattVltgCorrln.BattVltgCorrlnBattOverVltg
    connect CalRegn01Cmn.BattVltgCorrlnBattUnderVltg -> BattVltgCorrln.BattVltgCorrlnBattUnderVltg
    connect CalRegn01Cmn.BattVltgCorrlnNtc0x03C0x044FailStep -> BattVltgCorrln.BattVltgCorrlnNtc0x03C0x044FailStep
    connect CalRegn01Cmn.BattVltgCorrlnNtc0x03C0x044PassStep -> BattVltgCorrln.BattVltgCorrlnNtc0x03C0x044PassStep
    connect CalRegn01Cmn.BattVltgCorrlnNtc0x0B0FailStep -> BattVltgCorrln.BattVltgCorrlnNtc0x0B0FailStep
    connect CalRegn01Cmn.BattVltgCorrlnNtc0x0B0PassStep -> BattVltgCorrln.BattVltgCorrlnNtc0x0B0PassStep
    connect CalRegn01Cmn.BattVltgCorrlnNtc0x0B1FailStep -> BattVltgCorrln.BattVltgCorrlnNtc0x0B1FailStep
    connect CalRegn01Cmn.BattVltgCorrlnNtc0x0B1PassStep -> BattVltgCorrln.BattVltgCorrlnNtc0x0B1PassStep
    connect CalRegn01Cmn.BattVltgCorrlnNtc0x0B5FailStep -> BattVltgCorrln.BattVltgCorrlnNtc0x0B5FailStep
    connect CalRegn01Cmn.BattVltgCorrlnNtc0x0B5PassStep -> BattVltgCorrln.BattVltgCorrlnNtc0x0B5PassStep
    connect CalRegn01Cmn.BattVltgCorrlnRcvrlBattLoVltg -> BattVltgCorrln.BattVltgCorrlnRcvrlBattLoVltg
    connect CalRegn01Cmn.BattVltgCorrlnRcvrlBattOverVltg -> BattVltgCorrln.BattVltgCorrlnRcvrlBattOverVltg
    connect CalRegn01Cmn.BattVltgCorrlnRcvrlBattUnderVltg -> BattVltgCorrln.BattVltgCorrlnRcvrlBattUnderVltg
    connect CalRegn01Cmn.BattVltgCorrlnSwdMax -> BattVltgCorrln.BattVltgCorrlnSwdMax
    connect CalRegn01Cmn.BattVltgCorrlnSysMinVltg -> BattVltgCorrln.BattVltgCorrlnSysMinVltg
    connect CalRegn01Cmn.CurrMeasEolFixdPwmPerd -> CDD_CurrMeas.CurrMeasEolFixdPwmPerd
    connect CalRegn01Cmn.CurrMeasEolGainMax -> CDD_CurrMeas.CurrMeasEolGainMax
    connect CalRegn01Cmn.CurrMeasEolGainMin -> CDD_CurrMeas.CurrMeasEolGainMin
    connect CalRegn01Cmn.CurrMeasEolGainNom -> CDD_CurrMeas.CurrMeasEolGainNom
    connect CalRegn01Cmn.CurrMeasEolGainNrOfSample -> CDD_CurrMeas.CurrMeasEolGainNrOfSample
    connect CalRegn01Cmn.CurrMeasEolGainNumer -> CDD_CurrMeas.CurrMeasEolGainNumer
    connect CalRegn01Cmn.CurrMeasEolMaxMotVel -> CDD_CurrMeas.CurrMeasEolMaxMotVel
    connect CalRegn01Cmn.CurrMeasEolOffsHiBrdgVltgMin -> CDD_CurrMeas.CurrMeasEolOffsHiBrdgVltgMin
    connect CalRegn01Cmn.CurrMeasEolOffsHiCmuOffs -> CDD_CurrMeas.CurrMeasEolOffsHiCmuOffs
    connect CalRegn01Cmn.CurrMeasEolOffsLoCmuOffs -> CDD_CurrMeas.CurrMeasEolOffsLoCmuOffs
    connect CalRegn01Cmn.CurrMeasEolOffsMax -> CDD_CurrMeas.CurrMeasEolOffsMax
    connect CalRegn01Cmn.CurrMeasEolOffsMin -> CDD_CurrMeas.CurrMeasEolOffsMin
    connect CalRegn01Cmn.CurrMeasEolOffsNom -> CDD_CurrMeas.CurrMeasEolOffsNom
    connect CalRegn01Cmn.CurrMeasEolOffsNrOfSample -> CDD_CurrMeas.CurrMeasEolOffsNrOfSample
    connect CalRegn01Cmn.CurrMeasEolTranCntrThd -> CDD_CurrMeas.CurrMeasEolTranCntrThd
    connect CalRegn01Cmn.CurrMeasMinRqrdPhaOnTi -> CDD_CurrMeas.CurrMeasMinRqrdPhaOnTi
    connect CalRegn01Cmn.CurrMeasMotAgCompuDly -> CDD_CurrMeas.CurrMeasMotAgCompuDly
    connect CalRegn01Cmn.CurrMeasMotCurrAdcVlyWrmIninMax -> CDD_CurrMeas.CurrMeasMotCurrAdcVlyWrmIninMax
    connect CalRegn01Cmn.CurrMeasMotCurrAdcVlyWrmIninMin -> CDD_CurrMeas.CurrMeasMotCurrAdcVlyWrmIninMin
    connect CalRegn01Cmn.CurrMeasNtc0x05DFailStep -> CDD_CurrMeas.CurrMeasNtc0x05DFailStep
    connect CalRegn01Cmn.CurrMeasNtc0x05DPassStep -> CDD_CurrMeas.CurrMeasNtc0x05DPassStep
    connect CalRegn01Cmn.CurrMeasArbnMaxStallCntr -> CDD_CurrMeasArbn.CurrMeasArbnMaxStallCntr
    connect CalRegn01Cmn.CurrMeasEolFixdPwmPerd -> CDD_GtmCfgAndUse.CurrMeasEolFixdPwmPerd
    connect CalRegn01Cmn.CurrMeasEolOffsHiCmuOffs -> CDD_GtmCfgAndUse.CurrMeasEolOffsHiCmuOffs
    connect CalRegn01Cmn.CurrMeasEolOffsLoCmuOffs -> CDD_GtmCfgAndUse.CurrMeasEolOffsLoCmuOffs
    connect CalRegn01Cmn.GtmCfgAndUseAdcStrtOfCnvn2Offs -> CDD_GtmCfgAndUse.GtmCfgAndUseAdcStrtOfCnvn2Offs
    connect CalRegn01Cmn.GtmCfgAndUseAdcStrtOfCnvnPeakOffs -> CDD_GtmCfgAndUse.GtmCfgAndUseAdcStrtOfCnvnPeakOffs
    connect CalRegn01Cmn.GtmCfgAndUseDma2MilliSecToMotCtrlTrig -> CDD_GtmCfgAndUse.GtmCfgAndUseDma2MilliSecToMotCtrlTrig
    connect CalRegn01Cmn.GtmCfgAndUseDmaMotAgATrig -> CDD_GtmCfgAndUse.GtmCfgAndUseDmaMotAgATrig
    connect CalRegn01Cmn.GtmCfgAndUseDmaMotCtrlTo2MilliSecTrig -> CDD_GtmCfgAndUse.GtmCfgAndUseDmaMotCtrlTo2MilliSecTrig
    connect CalRegn01Cmn.GtmCfgAndUsePwmDbnd -> CDD_GtmCfgAndUse.GtmCfgAndUsePwmDbnd
    connect CalRegn01Cmn.MotAg5MeasAmpSqdMaxThd -> CDD_MotAg5Meas.MotAg5MeasAmpSqdMaxThd
    connect CalRegn01Cmn.MotAg5MeasAmpSqdMinThd -> CDD_MotAg5Meas.MotAg5MeasAmpSqdMinThd
    connect CalRegn01Cmn.MotAg5MeasLpFilFrq -> CDD_MotAg5Meas.MotAg5MeasLpFilFrq
    connect CalRegn01Cmn.MotAg5MeasOffs -> CDD_MotAg5Meas.MotAg5MeasOffs
    connect CalRegn01Cmn.MotAg5MeasRtAmpRecprLim -> CDD_MotAg5Meas.MotAg5MeasRtAmpRecprLim
    connect CalRegn01Cmn.MotAg5MeasRtFilEnaThd -> CDD_MotAg5Meas.MotAg5MeasRtFilEnaThd
    connect CalRegn01Cmn.MotAg5MeasRtMotVelFilEnaThd -> CDD_MotAg5Meas.MotAg5MeasRtMotVelFilEnaThd
    connect CalRegn01Cmn.MotAg5MeasRtOffsLim -> CDD_MotAg5Meas.MotAg5MeasRtOffsLim
    connect CalRegn01Cmn.MotAg5MeasRtToNomRatLim -> CDD_MotAg5Meas.MotAg5MeasRtToNomRatLim
    connect CalRegn01Cmn.MotAg6MeasAmpSqdMaxThd -> CDD_MotAg6Meas.MotAg6MeasAmpSqdMaxThd
    connect CalRegn01Cmn.MotAg6MeasAmpSqdMinThd -> CDD_MotAg6Meas.MotAg6MeasAmpSqdMinThd
    connect CalRegn01Cmn.MotAg6MeasLpFilFrq -> CDD_MotAg6Meas.MotAg6MeasLpFilFrq
    connect CalRegn01Cmn.MotAg6MeasOffs -> CDD_MotAg6Meas.MotAg6MeasOffs
    connect CalRegn01Cmn.MotAg6MeasRtAmpRecprLim -> CDD_MotAg6Meas.MotAg6MeasRtAmpRecprLim
    connect CalRegn01Cmn.MotAg6MeasRtFilEnaThd -> CDD_MotAg6Meas.MotAg6MeasRtFilEnaThd
    connect CalRegn01Cmn.MotAg6MeasRtMotVelFilEnaThd -> CDD_MotAg6Meas.MotAg6MeasRtMotVelFilEnaThd
    connect CalRegn01Cmn.MotAg6MeasRtOffsLim -> CDD_MotAg6Meas.MotAg6MeasRtOffsLim
    connect CalRegn01Cmn.MotAg6MeasRtToNomRatLim -> CDD_MotAg6Meas.MotAg6MeasRtToNomRatLim
    connect CalRegn01Cmn.MotAgSwCalVehSpdThd -> CDD_MotAgSwCal.MotAgSwCalVehSpdThd
    connect CalRegn01Cmn.MotCurrRegCfgCurrLoopSecOrderTrfFctEna -> CDD_MotCurrRegVltgLimr.MotCurrRegCfgCurrLoopSecOrderTrfFctEna
    connect CalRegn01Cmn.MotCurrRegCfgMotRVirtDax -> CDD_MotCurrRegVltgLimr.MotCurrRegCfgMotRVirtDax
    connect CalRegn01Cmn.MotCurrRegCfgMotRVirtQax -> CDD_MotCurrRegVltgLimr.MotCurrRegCfgMotRVirtQax
    connect CalRegn01Cmn.MotCurrRegVltgLimrCurrLoaScarSlewRate -> CDD_MotCurrRegVltgLimr.MotCurrRegVltgLimrCurrLoaScarSlewRate
    connect CalRegn01Cmn.MotCurrRegVltgLimrDaxAntiWdupCoeff -> CDD_MotCurrRegVltgLimr.MotCurrRegVltgLimrDaxAntiWdupCoeff
    connect CalRegn01Cmn.MotCurrRegVltgLimrDualEcuLoaScarSlewRate -> CDD_MotCurrRegVltgLimr.MotCurrRegVltgLimrDualEcuLoaScarSlewRate
    connect CalRegn01Cmn.MotCurrRegVltgLimrFETLoaScarSlewRate -> CDD_MotCurrRegVltgLimr.MotCurrRegVltgLimrFETLoaScarSlewRate
    connect CalRegn01Cmn.MotCurrRegVltgLimrIvtrLoaScarSlewRate -> CDD_MotCurrRegVltgLimr.MotCurrRegVltgLimrIvtrLoaScarSlewRate
    connect CalRegn01Cmn.MotCurrRegVltgLimrMotCurrPredEna -> CDD_MotCurrRegVltgLimr.MotCurrRegVltgLimrMotCurrPredEna
    connect CalRegn01Cmn.MotCurrRegVltgLimrMotCurrPredTi -> CDD_MotCurrRegVltgLimr.MotCurrRegVltgLimrMotCurrPredTi
    connect CalRegn01Cmn.MotCurrRegVltgLimrMotCurrQaxRefMdfnRplEna -> CDD_MotCurrRegVltgLimr.MotCurrRegVltgLimrMotCurrQaxRefMdfnRplEna
    connect CalRegn01Cmn.MotCurrRegVltgLimrMotVltgBrdgFilEna -> CDD_MotCurrRegVltgLimr.MotCurrRegVltgLimrMotVltgBrdgFilEna
    connect CalRegn01Cmn.MotCurrRegVltgLimrMotVltgBrdgLpFilFrq -> CDD_MotCurrRegVltgLimr.MotCurrRegVltgLimrMotVltgBrdgLpFilFrq
    connect CalRegn01Cmn.MotCurrRegVltgLimrMotVltgDaxIntglHiLim -> CDD_MotCurrRegVltgLimr.MotCurrRegVltgLimrMotVltgDaxIntglHiLim
    connect CalRegn01Cmn.MotCurrRegVltgLimrMotVltgDaxIntglLoLim -> CDD_MotCurrRegVltgLimr.MotCurrRegVltgLimrMotVltgDaxIntglLoLim
    connect CalRegn01Cmn.MotCurrRegVltgLimrMotVltgQaxFfFilEna -> CDD_MotCurrRegVltgLimr.MotCurrRegVltgLimrMotVltgQaxFfFilEna
    connect CalRegn01Cmn.MotCurrRegVltgLimrMotVltgQaxFfLpFilFrq -> CDD_MotCurrRegVltgLimr.MotCurrRegVltgLimrMotVltgQaxFfLpFilFrq
    connect CalRegn01Cmn.MotCurrRegVltgLimrMotVltgQaxIntglHiLim -> CDD_MotCurrRegVltgLimr.MotCurrRegVltgLimrMotVltgQaxIntglHiLim
    connect CalRegn01Cmn.MotCurrRegVltgLimrMotVltgQaxIntglLoLim -> CDD_MotCurrRegVltgLimr.MotCurrRegVltgLimrMotVltgQaxIntglLoLim
    connect CalRegn01Cmn.MotCurrRegVltgLimrQaxAntiWdupCoeff -> CDD_MotCurrRegVltgLimr.MotCurrRegVltgLimrQaxAntiWdupCoeff
    connect CalRegn01Cmn.MotCurrRegVltgLimrQaxAntiWdupScagDi -> CDD_MotCurrRegVltgLimr.MotCurrRegVltgLimrQaxAntiWdupScagDi
    connect CalRegn01Cmn.MotRefMdlFbCtrlDi -> CDD_MotCurrRegVltgLimr.MotRefMdlFbCtrlDi
    connect CalRegn01Cmn.MotRefMdlIvtrDeadTiBrdgVltgSca -> CDD_MotCurrRegVltgLimr.MotRefMdlIvtrDeadTiBrdgVltgSca
    connect CalRegn01Cmn.MotAgSwCalVehSpdThd -> CDD_SinVltgGenn.MotAgSwCalVehSpdThd
    connect CalRegn01Cmn.SinVltgGennDthrEna -> CDD_SinVltgGenn.SinVltgGennDthrEna
    connect CalRegn01Cmn.SinVltgGennDthrLpFilCoeff -> CDD_SinVltgGenn.SinVltgGennDthrLpFilCoeff
    connect CalRegn01Cmn.CmnMfgSrvSecuAcsAtmptTiOut -> CmnMfgSrv.CmnMfgSrvSecuAcsAtmptTiOut
    connect CalRegn01Cmn.CmnMfgSrvSecuAcsMaxNrAtmpt -> CmnMfgSrv.CmnMfgSrvSecuAcsMaxNrAtmpt
    connect CalRegn01Cmn.CurrMeasCorrlnMaxErrCurr -> CurrMeasCorrln.CurrMeasCorrlnMaxErrCurr
    connect CalRegn01Cmn.CurrMeasCorrlnMaxStallCntr -> CurrMeasCorrln.CurrMeasCorrlnMaxStallCntr
    connect CalRegn01Cmn.CurrMeasCorrlnNtc0x04DFailStep -> CurrMeasCorrln.CurrMeasCorrlnNtc0x04DFailStep
    connect CalRegn01Cmn.CurrMeasCorrlnNtc0x04DPassStep -> CurrMeasCorrln.CurrMeasCorrlnNtc0x04DPassStep
    connect CalRegn01Cmn.NxtrCalIdsCal0DevlpDesc -> CustDiag.NxtrCalIdsCal0DevlpDesc
    connect CalRegn01Cmn.DiagcMgrFltResp -> DiagcMgr.DiagcMgrFltResp
    connect CalRegn01Cmn.DiagcMgrFltResp -> DiagcMgrProxyAppl10.DiagcMgrFltResp
    connect CalRegn01Cmn.DrvrTqEstimnMtrxA -> DrvrTqEstimn.DrvrTqEstimnMtrxA
    connect CalRegn01Cmn.DrvrTqEstimnMtrxB -> DrvrTqEstimn.DrvrTqEstimnMtrxB
    connect CalRegn01Cmn.DrvrTqEstimnMtrxC -> DrvrTqEstimn.DrvrTqEstimnMtrxC
    connect CalRegn01Cmn.DrvrTqEstimnMtrxD -> DrvrTqEstimn.DrvrTqEstimnMtrxD
    connect CalRegn01Cmn.DutyCycThermProtnAbsltCtrlTFetMtgtnTblX -> DutyCycThermProtn.DutyCycThermProtnAbsltCtrlTFetMtgtnTblX
    connect CalRegn01Cmn.DutyCycThermProtnAbsltCtrlTTblX -> DutyCycThermProtn.DutyCycThermProtnAbsltCtrlTTblX
    connect CalRegn01Cmn.DutyCycThermProtnAbsltCtrlTTqFetMtgtnTblY -> DutyCycThermProtn.DutyCycThermProtnAbsltCtrlTTqFetMtgtnTblY
    connect CalRegn01Cmn.DutyCycThermProtnAbsltCtrlTTqTblY -> DutyCycThermProtn.DutyCycThermProtnAbsltCtrlTTqTblY
    connect CalRegn01Cmn.DutyCycThermProtnAbsltCuTFetMtgtnTblX -> DutyCycThermProtn.DutyCycThermProtnAbsltCuTFetMtgtnTblX
    connect CalRegn01Cmn.DutyCycThermProtnAbsltCuTTblX -> DutyCycThermProtn.DutyCycThermProtnAbsltCuTTblX
    connect CalRegn01Cmn.DutyCycThermProtnAbsltCuTTqFetMtgtnTblY -> DutyCycThermProtn.DutyCycThermProtnAbsltCuTTqFetMtgtnTblY
    connect CalRegn01Cmn.DutyCycThermProtnAbsltCuTTqTblY -> DutyCycThermProtn.DutyCycThermProtnAbsltCuTTqTblY
    connect CalRegn01Cmn.DutyCycThermProtnAbsltMotVelBreakPt -> DutyCycThermProtn.DutyCycThermProtnAbsltMotVelBreakPt
    connect CalRegn01Cmn.DutyCycThermProtnAbsltTTqSlewHiLim -> DutyCycThermProtn.DutyCycThermProtnAbsltTTqSlewHiLim
    connect CalRegn01Cmn.DutyCycThermProtnAbsltTTqSlewLoLim -> DutyCycThermProtn.DutyCycThermProtnAbsltTTqSlewLoLim
    connect CalRegn01Cmn.DutyCycThermProtnCtrlT -> DutyCycThermProtn.DutyCycThermProtnCtrlT
    connect CalRegn01Cmn.DutyCycThermProtnCtrlTSeln -> DutyCycThermProtn.DutyCycThermProtnCtrlTSeln
    connect CalRegn01Cmn.DutyCycThermProtnDutyCycFildThd -> DutyCycThermProtn.DutyCycThermProtnDutyCycFildThd
    connect CalRegn01Cmn.DutyCycThermProtnIgnOffCtrlEna -> DutyCycThermProtn.DutyCycThermProtnIgnOffCtrlEna
    connect CalRegn01Cmn.DutyCycThermProtnIgnOffMsgWaitTi -> DutyCycThermProtn.DutyCycThermProtnIgnOffMsgWaitTi
    connect CalRegn01Cmn.DutyCycThermProtnLstTblValNonStall -> DutyCycThermProtn.DutyCycThermProtnLstTblValNonStall
    connect CalRegn01Cmn.DutyCycThermProtnLstTblValStall -> DutyCycThermProtn.DutyCycThermProtnLstTblValStall
    connect CalRegn01Cmn.DutyCycThermProtnMotPrTSeln -> DutyCycThermProtn.DutyCycThermProtnMotPrTSeln
    connect CalRegn01Cmn.DutyCycThermProtnMplr1FetMtgtnNonStallTblY -> DutyCycThermProtn.DutyCycThermProtnMplr1FetMtgtnNonStallTblY
    connect CalRegn01Cmn.DutyCycThermProtnMplr1FetMtgtnStallTblY -> DutyCycThermProtn.DutyCycThermProtnMplr1FetMtgtnStallTblY
    connect CalRegn01Cmn.DutyCycThermProtnMplr1NonStallTblY -> DutyCycThermProtn.DutyCycThermProtnMplr1NonStallTblY
    connect CalRegn01Cmn.DutyCycThermProtnMplr1StallTblY -> DutyCycThermProtn.DutyCycThermProtnMplr1StallTblY
    connect CalRegn01Cmn.DutyCycThermProtnMplr2FetMtgtnNonStallTblY -> DutyCycThermProtn.DutyCycThermProtnMplr2FetMtgtnNonStallTblY
    connect CalRegn01Cmn.DutyCycThermProtnMplr2FetMtgtnStallTblY -> DutyCycThermProtn.DutyCycThermProtnMplr2FetMtgtnStallTblY
    connect CalRegn01Cmn.DutyCycThermProtnMplr2NonStallTblY -> DutyCycThermProtn.DutyCycThermProtnMplr2NonStallTblY
    connect CalRegn01Cmn.DutyCycThermProtnMplr2StallTblY -> DutyCycThermProtn.DutyCycThermProtnMplr2StallTblY
    connect CalRegn01Cmn.DutyCycThermProtnMplr3FetMtgtnNonStallTblY -> DutyCycThermProtn.DutyCycThermProtnMplr3FetMtgtnNonStallTblY
    connect CalRegn01Cmn.DutyCycThermProtnMplr3FetMtgtnStallTblY -> DutyCycThermProtn.DutyCycThermProtnMplr3FetMtgtnStallTblY
    connect CalRegn01Cmn.DutyCycThermProtnMplr3NonStallTblY -> DutyCycThermProtn.DutyCycThermProtnMplr3NonStallTblY
    connect CalRegn01Cmn.DutyCycThermProtnMplr3StallTblY -> DutyCycThermProtn.DutyCycThermProtnMplr3StallTblY
    connect CalRegn01Cmn.DutyCycThermProtnMplr4FetMtgtnNonStallTblY -> DutyCycThermProtn.DutyCycThermProtnMplr4FetMtgtnNonStallTblY
    connect CalRegn01Cmn.DutyCycThermProtnMplr4FetMtgtnStallTblY -> DutyCycThermProtn.DutyCycThermProtnMplr4FetMtgtnStallTblY
    connect CalRegn01Cmn.DutyCycThermProtnMplr4NonStallTblY -> DutyCycThermProtn.DutyCycThermProtnMplr4NonStallTblY
    connect CalRegn01Cmn.DutyCycThermProtnMplr4StallTblY -> DutyCycThermProtn.DutyCycThermProtnMplr4StallTblY
    connect CalRegn01Cmn.DutyCycThermProtnMplr5FetMtgtnNonStallTblY -> DutyCycThermProtn.DutyCycThermProtnMplr5FetMtgtnNonStallTblY
    connect CalRegn01Cmn.DutyCycThermProtnMplr5FetMtgtnStallTblY -> DutyCycThermProtn.DutyCycThermProtnMplr5FetMtgtnStallTblY
    connect CalRegn01Cmn.DutyCycThermProtnMplr5NonStallTblY -> DutyCycThermProtn.DutyCycThermProtnMplr5NonStallTblY
    connect CalRegn01Cmn.DutyCycThermProtnMplr5StallTblY -> DutyCycThermProtn.DutyCycThermProtnMplr5StallTblY
    connect CalRegn01Cmn.DutyCycThermProtnMplr6FetMtgtnNonStallTblY -> DutyCycThermProtn.DutyCycThermProtnMplr6FetMtgtnNonStallTblY
    connect CalRegn01Cmn.DutyCycThermProtnMplr6FetMtgtnStallTblY -> DutyCycThermProtn.DutyCycThermProtnMplr6FetMtgtnStallTblY
    connect CalRegn01Cmn.DutyCycThermProtnMplr6NonStallTblY -> DutyCycThermProtn.DutyCycThermProtnMplr6NonStallTblY
    connect CalRegn01Cmn.DutyCycThermProtnMplr6StallTblY -> DutyCycThermProtn.DutyCycThermProtnMplr6StallTblY
    connect CalRegn01Cmn.DutyCycThermProtnMplrFetMtgtnTblX -> DutyCycThermProtn.DutyCycThermProtnMplrFetMtgtnTblX
    connect CalRegn01Cmn.DutyCycThermProtnMplrTblX -> DutyCycThermProtn.DutyCycThermProtnMplrTblX
    connect CalRegn01Cmn.DutyCycThermProtnMplrTSeln -> DutyCycThermProtn.DutyCycThermProtnMplrTSeln
    connect CalRegn01Cmn.DutyCycThermProtnSlowFilTSeln -> DutyCycThermProtn.DutyCycThermProtnSlowFilTSeln
    connect CalRegn01Cmn.DutyCycThermProtnThermLimScaFac -> DutyCycThermProtn.DutyCycThermProtnThermLimScaFac
    connect CalRegn01Cmn.DutyCycThermProtnThermLoadLimTblX -> DutyCycThermProtn.DutyCycThermProtnThermLoadLimTblX
    connect CalRegn01Cmn.DutyCycThermProtnThermLoadLimTblY -> DutyCycThermProtn.DutyCycThermProtnThermLoadLimTblY
    connect CalRegn01Cmn.DutyCycThermProtnTqCmdSlewDwn -> DutyCycThermProtn.DutyCycThermProtnTqCmdSlewDwn
    connect CalRegn01Cmn.DutyCycThermProtnTqCmdSlewUp -> DutyCycThermProtn.DutyCycThermProtnTqCmdSlewUp
    connect CalRegn01Cmn.ElecPwrCnsCtrlrInpR -> ElecPwrCns.ElecPwrCnsCtrlrInpR
    connect CalRegn01Cmn.PwrLimrStdOperMotEnvlpY -> FordHwTqCdng.PwrLimrStdOperMotEnvlpY
    connect CalRegn01Cmn.FordMsg077BusHiSpdCanDtcInhbThd -> FordMsg077BusHiSpd.FordMsg077BusHiSpdCanDtcInhbThd
    connect CalRegn01Cmn.FordMsg077BusHiSpdLatACmpdInvldSigFaildThd -> FordMsg077BusHiSpd.FordMsg077BusHiSpdLatACmpdInvldSigFaildThd
    connect CalRegn01Cmn.FordMsg077BusHiSpdLatACmpdInvldSigPassdThd -> FordMsg077BusHiSpd.FordMsg077BusHiSpdLatACmpdInvldSigPassdThd
    connect CalRegn01Cmn.FordMsg077BusHiSpdLatACmpdVldMissThd -> FordMsg077BusHiSpd.FordMsg077BusHiSpdLatACmpdVldMissThd
    connect CalRegn01Cmn.FordMsg077BusHiSpdLgtACmpdInvldSigFaildThd -> FordMsg077BusHiSpd.FordMsg077BusHiSpdLgtACmpdInvldSigFaildThd
    connect CalRegn01Cmn.FordMsg077BusHiSpdLgtACmpdInvldSigPassdThd -> FordMsg077BusHiSpd.FordMsg077BusHiSpdLgtACmpdInvldSigPassdThd
    connect CalRegn01Cmn.FordMsg077BusHiSpdLgtACmpdVldMissThd -> FordMsg077BusHiSpd.FordMsg077BusHiSpdLgtACmpdVldMissThd
    connect CalRegn01Cmn.FordMsg077BusHiSpdMissMsgFaildThd -> FordMsg077BusHiSpd.FordMsg077BusHiSpdMissMsgFaildThd
    connect CalRegn01Cmn.FordMsg077BusHiSpdMissMsgPassdThd -> FordMsg077BusHiSpd.FordMsg077BusHiSpdMissMsgPassdThd
    connect CalRegn01Cmn.FordMsg077BusHiSpdOverGndInvldSigFaildThd -> FordMsg077BusHiSpd.FordMsg077BusHiSpdOverGndInvldSigFaildThd
    connect CalRegn01Cmn.FordMsg077BusHiSpdOverGndInvldSigPassdThd -> FordMsg077BusHiSpd.FordMsg077BusHiSpdOverGndInvldSigPassdThd
    connect CalRegn01Cmn.FordMsg077BusHiSpdVehLatACmpdVldFaildThd -> FordMsg077BusHiSpd.FordMsg077BusHiSpdVehLatACmpdVldFaildThd
    connect CalRegn01Cmn.FordMsg077BusHiSpdVehLatACmpdVldPassdThd -> FordMsg077BusHiSpd.FordMsg077BusHiSpdVehLatACmpdVldPassdThd
    connect CalRegn01Cmn.FordMsg077BusHiSpdVehLgtACmpdVldFaildThd -> FordMsg077BusHiSpd.FordMsg077BusHiSpdVehLgtACmpdVldFaildThd
    connect CalRegn01Cmn.FordMsg077BusHiSpdVehLgtACmpdVldPassdThd -> FordMsg077BusHiSpd.FordMsg077BusHiSpdVehLgtACmpdVldPassdThd
    connect CalRegn01Cmn.FordMsg077BusHiSpdVehSpdOverGndVldFaildThd -> FordMsg077BusHiSpd.FordMsg077BusHiSpdVehSpdOverGndVldFaildThd
    connect CalRegn01Cmn.FordMsg077BusHiSpdVehSpdOverGndVldMissThd -> FordMsg077BusHiSpd.FordMsg077BusHiSpdVehSpdOverGndVldMissThd
    connect CalRegn01Cmn.FordMsg077BusHiSpdVehSpdOverGndVldPassdThd -> FordMsg077BusHiSpd.FordMsg077BusHiSpdVehSpdOverGndVldPassdThd
    connect CalRegn01Cmn.FordMsg077BusHiSpdVehYawRateCmpdVldFaildThd -> FordMsg077BusHiSpd.FordMsg077BusHiSpdVehYawRateCmpdVldFaildThd
    connect CalRegn01Cmn.FordMsg077BusHiSpdVehYawRateCmpdVldPassdThd -> FordMsg077BusHiSpd.FordMsg077BusHiSpdVehYawRateCmpdVldPassdThd
    connect CalRegn01Cmn.FordMsg077BusHiSpdYawRateCmpdInvldSigFaildThd -> FordMsg077BusHiSpd.FordMsg077BusHiSpdYawRateCmpdInvldSigFaildThd
    connect CalRegn01Cmn.FordMsg077BusHiSpdYawRateCmpdInvldSigPassdThd -> FordMsg077BusHiSpd.FordMsg077BusHiSpdYawRateCmpdInvldSigPassdThd
    connect CalRegn01Cmn.FordMsg077BusHiSpdYawRateCmpdVldMissThd -> FordMsg077BusHiSpd.FordMsg077BusHiSpdYawRateCmpdVldMissThd
    connect CalRegn01Cmn.FordMsg07DBusHiSpdActBrkTqSigInvldPassdThd -> FordMsg07DBusHiSpd.FordMsg07DBusHiSpdActBrkTqSigInvldPassdThd
    connect CalRegn01Cmn.FordMsg07DBusHiSpdFordVehActBrkTqInvldThd -> FordMsg07DBusHiSpd.FordMsg07DBusHiSpdFordVehActBrkTqInvldThd
    connect CalRegn01Cmn.FordMsg07DBusHiSpdFordVehActBrkTqVldThd -> FordMsg07DBusHiSpd.FordMsg07DBusHiSpdFordVehActBrkTqVldThd
    connect CalRegn01Cmn.FordMsg07DBusHiSpdFordVehBrkTqVldMissMsgThd -> FordMsg07DBusHiSpd.FordMsg07DBusHiSpdFordVehBrkTqVldMissMsgThd
    connect CalRegn01Cmn.FordMsg07DBusHiSpdFordVehVertACmpdSigInvldThd -> FordMsg07DBusHiSpd.FordMsg07DBusHiSpdFordVehVertACmpdSigInvldThd
    connect CalRegn01Cmn.FordMsg07DBusHiSpdFordVehVertACmpdSigVldThd -> FordMsg07DBusHiSpd.FordMsg07DBusHiSpdFordVehVertACmpdSigVldThd
    connect CalRegn01Cmn.FordMsg07DBusHiSpdFordVehVertAVldMissMsgThd -> FordMsg07DBusHiSpd.FordMsg07DBusHiSpdFordVehVertAVldMissMsgThd
    connect CalRegn01Cmn.FordMsg07DBusHiSpdMissMsgFaildThd -> FordMsg07DBusHiSpd.FordMsg07DBusHiSpdMissMsgFaildThd
    connect CalRegn01Cmn.FordMsg07DBusHiSpdMissMsgPassdThd -> FordMsg07DBusHiSpd.FordMsg07DBusHiSpdMissMsgPassdThd
    connect CalRegn01Cmn.FordMsg07DBusHiSpdVehActTqBrkInvldFaildThd -> FordMsg07DBusHiSpd.FordMsg07DBusHiSpdVehActTqBrkInvldFaildThd
    connect CalRegn01Cmn.FordMsg07DBusHiSpdVertACmpdSigInvldFaildThd -> FordMsg07DBusHiSpd.FordMsg07DBusHiSpdVertACmpdSigInvldFaildThd
    connect CalRegn01Cmn.FordMsg07DBusHiSpdVertACmpdSigInvldPassdThd -> FordMsg07DBusHiSpd.FordMsg07DBusHiSpdVertACmpdSigInvldPassdThd
    connect CalRegn01Cmn.FordMsg083BusHiSpdFordVehTurnSigVldThd -> FordMsg083BusHiSpd.FordMsg083BusHiSpdFordVehTurnSigVldThd
    connect CalRegn01Cmn.FordMsg083BusHiSpdMissMsgFaildThd -> FordMsg083BusHiSpd.FordMsg083BusHiSpdMissMsgFaildThd
    connect CalRegn01Cmn.FordMsg083BusHiSpdMissMsgPassdThd -> FordMsg083BusHiSpd.FordMsg083BusHiSpdMissMsgPassdThd
    connect CalRegn01Cmn.FordMsg083BusHiSpdVehTurnSigVldMissMsgThd -> FordMsg083BusHiSpd.FordMsg083BusHiSpdVehTurnSigVldMissMsgThd
    connect CalRegn01Cmn.FordMsg091BusHiSpdInvldMsgFaildThd -> FordMsg091BusHiSpd.FordMsg091BusHiSpdInvldMsgFaildThd
    connect CalRegn01Cmn.FordMsg091BusHiSpdInvldMsgPassdThd -> FordMsg091BusHiSpd.FordMsg091BusHiSpdInvldMsgPassdThd
    connect CalRegn01Cmn.FordMsg091BusHiSpdMissMsgFaildThd -> FordMsg091BusHiSpd.FordMsg091BusHiSpdMissMsgFaildThd
    connect CalRegn01Cmn.FordMsg091BusHiSpdMissMsgPassdThd -> FordMsg091BusHiSpd.FordMsg091BusHiSpdMissMsgPassdThd
    connect CalRegn01Cmn.FordMsg091BusHiSpdYawRateRawVldMissFaildThd -> FordMsg091BusHiSpd.FordMsg091BusHiSpdYawRateRawVldMissFaildThd
    connect CalRegn01Cmn.FordMsg091BusHiSpdYawRateRawVldSigFaildThd -> FordMsg091BusHiSpd.FordMsg091BusHiSpdYawRateRawVldSigFaildThd
    connect CalRegn01Cmn.FordMsg091BusHiSpdYawRateRawVldSigPassdThd -> FordMsg091BusHiSpd.FordMsg091BusHiSpdYawRateRawVldSigPassdThd
    connect CalRegn01Cmn.FordMsg167BusHiSpdMissMsgFaildTiThd -> FordMsg167BusHiSpd.FordMsg167BusHiSpdMissMsgFaildTiThd
    connect CalRegn01Cmn.FordMsg167BusHiSpdMissMsgPassdTiThd -> FordMsg167BusHiSpd.FordMsg167BusHiSpdMissMsgPassdTiThd
    connect CalRegn01Cmn.FordMsg167BusHiSpdPrpnWhlTqFaildTiThd -> FordMsg167BusHiSpd.FordMsg167BusHiSpdPrpnWhlTqFaildTiThd
    connect CalRegn01Cmn.FordMsg167BusHiSpdPrpnWhlTqMissTiThd -> FordMsg167BusHiSpd.FordMsg167BusHiSpdPrpnWhlTqMissTiThd
    connect CalRegn01Cmn.FordMsg167BusHiSpdPrpnWhlTqPassdTiThd -> FordMsg167BusHiSpd.FordMsg167BusHiSpdPrpnWhlTqPassdTiThd
    connect CalRegn01Cmn.FordMsg167BusHiSpdPrpnWhlTqSigInvldFaildTiThd -> FordMsg167BusHiSpd.FordMsg167BusHiSpdPrpnWhlTqSigInvldFaildTiThd
    connect CalRegn01Cmn.FordMsg167BusHiSpdPrpnWhlTqSigInvldPassdTiThd -> FordMsg167BusHiSpd.FordMsg167BusHiSpdPrpnWhlTqSigInvldPassdTiThd
    connect CalRegn01Cmn.FordMsg202BusHiSpdEngModLoQlyVldFaildThd -> FordMsg202BusHiSpd.FordMsg202BusHiSpdEngModLoQlyVldFaildThd
    connect CalRegn01Cmn.FordMsg202BusHiSpdEngModLoQlyVldMissThd -> FordMsg202BusHiSpd.FordMsg202BusHiSpdEngModLoQlyVldMissThd
    connect CalRegn01Cmn.FordMsg202BusHiSpdEngModLoQlyVldPassdThd -> FordMsg202BusHiSpd.FordMsg202BusHiSpdEngModLoQlyVldPassdThd
    connect CalRegn01Cmn.FordMsg202BusHiSpdEngModlVldFaildThd -> FordMsg202BusHiSpd.FordMsg202BusHiSpdEngModlVldFaildThd
    connect CalRegn01Cmn.FordMsg202BusHiSpdEngModlVldMissThd -> FordMsg202BusHiSpd.FordMsg202BusHiSpdEngModlVldMissThd
    connect CalRegn01Cmn.FordMsg202BusHiSpdGearRvsStsInvldFaildThd -> FordMsg202BusHiSpd.FordMsg202BusHiSpdGearRvsStsInvldFaildThd
    connect CalRegn01Cmn.FordMsg202BusHiSpdGearRvsStsInvldPassdThd -> FordMsg202BusHiSpd.FordMsg202BusHiSpdGearRvsStsInvldPassdThd
    connect CalRegn01Cmn.FordMsg202BusHiSpdGearRvsStsVldFaildThd -> FordMsg202BusHiSpd.FordMsg202BusHiSpdGearRvsStsVldFaildThd
    connect CalRegn01Cmn.FordMsg202BusHiSpdGearRvsStsVldMissThd -> FordMsg202BusHiSpd.FordMsg202BusHiSpdGearRvsStsVldMissThd
    connect CalRegn01Cmn.FordMsg202BusHiSpdGearRvsStsVldPassdThd -> FordMsg202BusHiSpd.FordMsg202BusHiSpdGearRvsStsVldPassdThd
    connect CalRegn01Cmn.FordMsg202BusHiSpdMissMsgFaildAbsPrsntDisadThd -> FordMsg202BusHiSpd.FordMsg202BusHiSpdMissMsgFaildAbsPrsntDisadThd
    connect CalRegn01Cmn.FordMsg202BusHiSpdMissMsgFaildAbsPrsntEnadThd -> FordMsg202BusHiSpd.FordMsg202BusHiSpdMissMsgFaildAbsPrsntEnadThd
    connect CalRegn01Cmn.FordMsg202BusHiSpdMissMsgPassdThd -> FordMsg202BusHiSpd.FordMsg202BusHiSpdMissMsgPassdThd
    connect CalRegn01Cmn.FordMsg202BusHiSpdQlyFacEngModInvldFaildThd -> FordMsg202BusHiSpd.FordMsg202BusHiSpdQlyFacEngModInvldFaildThd
    connect CalRegn01Cmn.FordMsg202BusHiSpdQlyFacEngModInvldPassdThd -> FordMsg202BusHiSpd.FordMsg202BusHiSpdQlyFacEngModInvldPassdThd
    connect CalRegn01Cmn.FordMsg202BusHiSpdTrlrBackupAssiAvlVldMissThd -> FordMsg202BusHiSpd.FordMsg202BusHiSpdTrlrBackupAssiAvlVldMissThd
    connect CalRegn01Cmn.FordMsg202BusHiSpdTrlrBackupAssiAvlVldPassdThd -> FordMsg202BusHiSpd.FordMsg202BusHiSpdTrlrBackupAssiAvlVldPassdThd
    connect CalRegn01Cmn.FordMsg213BusHiSpdAbsActvVldFaildThd -> FordMsg213BusHiSpd.FordMsg213BusHiSpdAbsActvVldFaildThd
    connect CalRegn01Cmn.FordMsg213BusHiSpdAbsActvVldPassdThd -> FordMsg213BusHiSpd.FordMsg213BusHiSpdAbsActvVldPassdThd
    connect CalRegn01Cmn.FordMsg213BusHiSpdEvasSteerAssiEnadThd -> FordMsg213BusHiSpd.FordMsg213BusHiSpdEvasSteerAssiEnadThd
    connect CalRegn01Cmn.FordMsg213BusHiSpdMissMsgFaildThd -> FordMsg213BusHiSpd.FordMsg213BusHiSpdMissMsgFaildThd
    connect CalRegn01Cmn.FordMsg213BusHiSpdMissMsgPassdThd -> FordMsg213BusHiSpd.FordMsg213BusHiSpdMissMsgPassdThd
    connect CalRegn01Cmn.FordMsg215BusHiSpdFordVehTrlrAidModReqVldNotRxdTiThd -> FordMsg215BusHiSpd.FordMsg215BusHiSpdFordVehTrlrAidModReqVldNotRxdTiThd
    connect CalRegn01Cmn.FordMsg215BusHiSpdFordVehTrlrAidModReqVldRxdTiThd -> FordMsg215BusHiSpd.FordMsg215BusHiSpdFordVehTrlrAidModReqVldRxdTiThd
    connect CalRegn01Cmn.FordMsg215BusHiSpdMissMsgFaildTiThd -> FordMsg215BusHiSpd.FordMsg215BusHiSpdMissMsgFaildTiThd
    connect CalRegn01Cmn.FordMsg215BusHiSpdMissMsgPassdTiThd -> FordMsg215BusHiSpd.FordMsg215BusHiSpdMissMsgPassdTiThd
    connect CalRegn01Cmn.FordMsg216BusHiSpdFrntLeWhlCntrDirFaildTiThd -> FordMsg216BusHiSpd.FordMsg216BusHiSpdFrntLeWhlCntrDirFaildTiThd
    connect CalRegn01Cmn.FordMsg216BusHiSpdFrntLeWhlCntrDirPassdTiThd -> FordMsg216BusHiSpd.FordMsg216BusHiSpdFrntLeWhlCntrDirPassdTiThd
    connect CalRegn01Cmn.FordMsg216BusHiSpdFrntLeWhlVldMissMsgThd -> FordMsg216BusHiSpd.FordMsg216BusHiSpdFrntLeWhlVldMissMsgThd
    connect CalRegn01Cmn.FordMsg216BusHiSpdFrntRiWhlCntrDirFaildTiThd -> FordMsg216BusHiSpd.FordMsg216BusHiSpdFrntRiWhlCntrDirFaildTiThd
    connect CalRegn01Cmn.FordMsg216BusHiSpdFrntRiWhlCntrDirPassdTiThd -> FordMsg216BusHiSpd.FordMsg216BusHiSpdFrntRiWhlCntrDirPassdTiThd
    connect CalRegn01Cmn.FordMsg216BusHiSpdFrntRiWhlVldMissMsgThd -> FordMsg216BusHiSpd.FordMsg216BusHiSpdFrntRiWhlVldMissMsgThd
    connect CalRegn01Cmn.FordMsg216BusHiSpdMissMsgFaildTiThd -> FordMsg216BusHiSpd.FordMsg216BusHiSpdMissMsgFaildTiThd
    connect CalRegn01Cmn.FordMsg216BusHiSpdMissMsgPassdTiThd -> FordMsg216BusHiSpd.FordMsg216BusHiSpdMissMsgPassdTiThd
    connect CalRegn01Cmn.FordMsg216BusHiSpdReLeWhlCntrDirFaildTiThd -> FordMsg216BusHiSpd.FordMsg216BusHiSpdReLeWhlCntrDirFaildTiThd
    connect CalRegn01Cmn.FordMsg216BusHiSpdReLeWhlCntrDirPassdTiThd -> FordMsg216BusHiSpd.FordMsg216BusHiSpdReLeWhlCntrDirPassdTiThd
    connect CalRegn01Cmn.FordMsg216BusHiSpdReLeWhlVldMissMsgThd -> FordMsg216BusHiSpd.FordMsg216BusHiSpdReLeWhlVldMissMsgThd
    connect CalRegn01Cmn.FordMsg216BusHiSpdReRiWhlCntrDirFaildTiThd -> FordMsg216BusHiSpd.FordMsg216BusHiSpdReRiWhlCntrDirFaildTiThd
    connect CalRegn01Cmn.FordMsg216BusHiSpdReRiWhlCntrDirPassdTiThd -> FordMsg216BusHiSpd.FordMsg216BusHiSpdReRiWhlCntrDirPassdTiThd
    connect CalRegn01Cmn.FordMsg216BusHiSpdReRiWhlVldMissMsgThd -> FordMsg216BusHiSpd.FordMsg216BusHiSpdReRiWhlVldMissMsgThd
    connect CalRegn01Cmn.FordMsg217BusHiSpdFrntLeWhlSpdInvldFaildThd -> FordMsg217BusHiSpd.FordMsg217BusHiSpdFrntLeWhlSpdInvldFaildThd
    connect CalRegn01Cmn.FordMsg217BusHiSpdFrntLeWhlSpdInvldPassdThd -> FordMsg217BusHiSpd.FordMsg217BusHiSpdFrntLeWhlSpdInvldPassdThd
    connect CalRegn01Cmn.FordMsg217BusHiSpdFrntLeWhlVldFaildThd -> FordMsg217BusHiSpd.FordMsg217BusHiSpdFrntLeWhlVldFaildThd
    connect CalRegn01Cmn.FordMsg217BusHiSpdFrntLeWhlVldMissThd -> FordMsg217BusHiSpd.FordMsg217BusHiSpdFrntLeWhlVldMissThd
    connect CalRegn01Cmn.FordMsg217BusHiSpdFrntLeWhlVldPassdThd -> FordMsg217BusHiSpd.FordMsg217BusHiSpdFrntLeWhlVldPassdThd
    connect CalRegn01Cmn.FordMsg217BusHiSpdFrntRiWhlSpdInvldFaildThd -> FordMsg217BusHiSpd.FordMsg217BusHiSpdFrntRiWhlSpdInvldFaildThd
    connect CalRegn01Cmn.FordMsg217BusHiSpdFrntRiWhlSpdInvldPassdThd -> FordMsg217BusHiSpd.FordMsg217BusHiSpdFrntRiWhlSpdInvldPassdThd
    connect CalRegn01Cmn.FordMsg217BusHiSpdFrntRiWhlVldFaildThd -> FordMsg217BusHiSpd.FordMsg217BusHiSpdFrntRiWhlVldFaildThd
    connect CalRegn01Cmn.FordMsg217BusHiSpdFrntRiWhlVldMissThd -> FordMsg217BusHiSpd.FordMsg217BusHiSpdFrntRiWhlVldMissThd
    connect CalRegn01Cmn.FordMsg217BusHiSpdFrntRiWhlVldPassdThd -> FordMsg217BusHiSpd.FordMsg217BusHiSpdFrntRiWhlVldPassdThd
    connect CalRegn01Cmn.FordMsg217BusHiSpdMissMsgFaildThd -> FordMsg217BusHiSpd.FordMsg217BusHiSpdMissMsgFaildThd
    connect CalRegn01Cmn.FordMsg217BusHiSpdMissMsgPassdThd -> FordMsg217BusHiSpd.FordMsg217BusHiSpdMissMsgPassdThd
    connect CalRegn01Cmn.FordMsg217BusHiSpdReLeWhlSpdInvldFaildThd -> FordMsg217BusHiSpd.FordMsg217BusHiSpdReLeWhlSpdInvldFaildThd
    connect CalRegn01Cmn.FordMsg217BusHiSpdReLeWhlSpdInvldPassdThd -> FordMsg217BusHiSpd.FordMsg217BusHiSpdReLeWhlSpdInvldPassdThd
    connect CalRegn01Cmn.FordMsg217BusHiSpdReLeWhlVldFaildThd -> FordMsg217BusHiSpd.FordMsg217BusHiSpdReLeWhlVldFaildThd
    connect CalRegn01Cmn.FordMsg217BusHiSpdReLeWhlVldMissThd -> FordMsg217BusHiSpd.FordMsg217BusHiSpdReLeWhlVldMissThd
    connect CalRegn01Cmn.FordMsg217BusHiSpdReLeWhlVldPassdThd -> FordMsg217BusHiSpd.FordMsg217BusHiSpdReLeWhlVldPassdThd
    connect CalRegn01Cmn.FordMsg217BusHiSpdReRiWhlSpdInvldFaildThd -> FordMsg217BusHiSpd.FordMsg217BusHiSpdReRiWhlSpdInvldFaildThd
    connect CalRegn01Cmn.FordMsg217BusHiSpdReRiWhlSpdInvldPassdThd -> FordMsg217BusHiSpd.FordMsg217BusHiSpdReRiWhlSpdInvldPassdThd
    connect CalRegn01Cmn.FordMsg217BusHiSpdReRiWhlVldFaildThd -> FordMsg217BusHiSpd.FordMsg217BusHiSpdReRiWhlVldFaildThd
    connect CalRegn01Cmn.FordMsg217BusHiSpdReRiWhlVldMissThd -> FordMsg217BusHiSpd.FordMsg217BusHiSpdReRiWhlVldMissThd
    connect CalRegn01Cmn.FordMsg217BusHiSpdReRiWhlVldPassdThd -> FordMsg217BusHiSpd.FordMsg217BusHiSpdReRiWhlVldPassdThd
    connect CalRegn01Cmn.FordMsg230BusHiSpdFordVehGearLvrPosnFaildTiThd -> FordMsg230BusHiSpd.FordMsg230BusHiSpdFordVehGearLvrPosnFaildTiThd
    connect CalRegn01Cmn.FordMsg230BusHiSpdFordVehGearLvrPosnPassdTiThd -> FordMsg230BusHiSpd.FordMsg230BusHiSpdFordVehGearLvrPosnPassdTiThd
    connect CalRegn01Cmn.FordMsg230BusHiSpdGearLvrPosnMissTiThd -> FordMsg230BusHiSpd.FordMsg230BusHiSpdGearLvrPosnMissTiThd
    connect CalRegn01Cmn.FordMsg230BusHiSpdInvldSigFaildThd -> FordMsg230BusHiSpd.FordMsg230BusHiSpdInvldSigFaildThd
    connect CalRegn01Cmn.FordMsg230BusHiSpdInvldSigPassdThd -> FordMsg230BusHiSpd.FordMsg230BusHiSpdInvldSigPassdThd
    connect CalRegn01Cmn.FordMsg230BusHiSpdMissMsgFaildThd -> FordMsg230BusHiSpd.FordMsg230BusHiSpdMissMsgFaildThd
    connect CalRegn01Cmn.FordMsg230BusHiSpdMissMsgPassdThd -> FordMsg230BusHiSpd.FordMsg230BusHiSpdMissMsgPassdThd
    connect CalRegn01Cmn.FordMsg2FDBusHiSpdFordVehEvasSteerAssiReqVldNotRxdTiThd -> FordMsg2FDBusHiSpd.FordMsg2FDBusHiSpdFordVehEvasSteerAssiReqVldNotRxdTiThd
    connect CalRegn01Cmn.FordMsg2FDBusHiSpdFordVehEvasSteerAssiReqVldRxdTiThd -> FordMsg2FDBusHiSpd.FordMsg2FDBusHiSpdFordVehEvasSteerAssiReqVldRxdTiThd
    connect CalRegn01Cmn.FordMsg2FDBusHiSpdMissMsgFaildTiThd -> FordMsg2FDBusHiSpd.FordMsg2FDBusHiSpdMissMsgFaildTiThd
    connect CalRegn01Cmn.FordMsg2FDBusHiSpdMissMsgPassdTiThd -> FordMsg2FDBusHiSpd.FordMsg2FDBusHiSpdMissMsgPassdTiThd
    connect CalRegn01Cmn.FordMsg3B3BusHiSpdIgnStsVldFaildThd -> FordMsg3B3BusHiSpd.FordMsg3B3BusHiSpdIgnStsVldFaildThd
    connect CalRegn01Cmn.FordMsg3B3BusHiSpdIgnStsVldMissThd -> FordMsg3B3BusHiSpd.FordMsg3B3BusHiSpdIgnStsVldMissThd
    connect CalRegn01Cmn.FordMsg3B3BusHiSpdIgnStsVldPassdThd -> FordMsg3B3BusHiSpd.FordMsg3B3BusHiSpdIgnStsVldPassdThd
    connect CalRegn01Cmn.FordMsg3B3BusHiSpdInvldSigFaildThd -> FordMsg3B3BusHiSpd.FordMsg3B3BusHiSpdInvldSigFaildThd
    connect CalRegn01Cmn.FordMsg3B3BusHiSpdInvldSigPassdThd -> FordMsg3B3BusHiSpd.FordMsg3B3BusHiSpdInvldSigPassdThd
    connect CalRegn01Cmn.FordMsg3B3BusHiSpdMissMsgFaildThd -> FordMsg3B3BusHiSpd.FordMsg3B3BusHiSpdMissMsgFaildThd
    connect CalRegn01Cmn.FordMsg3B3BusHiSpdMissMsgPassdThd -> FordMsg3B3BusHiSpd.FordMsg3B3BusHiSpdMissMsgPassdThd
    connect CalRegn01Cmn.FordMsg3CABusHiSpdLaneAssiImgProcgModlAFaildCrvtTiThd -> FordMsg3CABusHiSpd.FordMsg3CABusHiSpdLaneAssiImgProcgModlAFaildCrvtTiThd
    connect CalRegn01Cmn.FordMsg3CABusHiSpdLaneAssiImgProcgModlAFaildReqdAgTiThd -> FordMsg3CABusHiSpd.FordMsg3CABusHiSpdLaneAssiImgProcgModlAFaildReqdAgTiThd
    connect CalRegn01Cmn.FordMsg3CABusHiSpdLaneAssiImgProcgModlAPassdTiThd -> FordMsg3CABusHiSpd.FordMsg3CABusHiSpdLaneAssiImgProcgModlAPassdTiThd
    connect CalRegn01Cmn.FordMsg3CABusHiSpdLaneAssiImgProcgModlAVldMissTiThd -> FordMsg3CABusHiSpd.FordMsg3CABusHiSpdLaneAssiImgProcgModlAVldMissTiThd
    connect CalRegn01Cmn.FordMsg3CABusHiSpdLaneKeepSysCrvtInvldFaildTiThd -> FordMsg3CABusHiSpd.FordMsg3CABusHiSpdLaneKeepSysCrvtInvldFaildTiThd
    connect CalRegn01Cmn.FordMsg3CABusHiSpdLaneKeepSysCrvtInvldPassdTiThd -> FordMsg3CABusHiSpd.FordMsg3CABusHiSpdLaneKeepSysCrvtInvldPassdTiThd
    connect CalRegn01Cmn.FordMsg3CABusHiSpdLaneKeepSysReqdAgInvldFaildTiThd -> FordMsg3CABusHiSpd.FordMsg3CABusHiSpdLaneKeepSysReqdAgInvldFaildTiThd
    connect CalRegn01Cmn.FordMsg3CABusHiSpdLaneKeepSysReqdAgInvldPassdTiThd -> FordMsg3CABusHiSpd.FordMsg3CABusHiSpdLaneKeepSysReqdAgInvldPassdTiThd
    connect CalRegn01Cmn.FordMsg3CABusHiSpdMissMsgFaildTiThd -> FordMsg3CABusHiSpd.FordMsg3CABusHiSpdMissMsgFaildTiThd
    connect CalRegn01Cmn.FordMsg3CABusHiSpdMissMsgPassdTiThd -> FordMsg3CABusHiSpd.FordMsg3CABusHiSpdMissMsgPassdTiThd
    connect CalRegn01Cmn.FordMsg3D3BusHiSpdImgProcrModlAVldFaildThd -> FordMsg3D3BusHiSpd.FordMsg3D3BusHiSpdImgProcrModlAVldFaildThd
    connect CalRegn01Cmn.FordMsg3D3BusHiSpdImgProcrModlAVldPassdThd -> FordMsg3D3BusHiSpd.FordMsg3D3BusHiSpdImgProcrModlAVldPassdThd
    connect CalRegn01Cmn.FordMsg3D3BusHiSpdMissMsgFaildThd -> FordMsg3D3BusHiSpd.FordMsg3D3BusHiSpdMissMsgFaildThd
    connect CalRegn01Cmn.FordMsg3D3BusHiSpdMissMsgPassdThd -> FordMsg3D3BusHiSpd.FordMsg3D3BusHiSpdMissMsgPassdThd
    connect CalRegn01Cmn.FordMsg3D7BusHiSpdImgProcrModlAVldMissThd -> FordMsg3D7BusHiSpd.FordMsg3D7BusHiSpdImgProcrModlAVldMissThd
    connect CalRegn01Cmn.FordMsg3D7BusHiSpdImgProcrModlAVldPassdThd -> FordMsg3D7BusHiSpd.FordMsg3D7BusHiSpdImgProcrModlAVldPassdThd
    connect CalRegn01Cmn.FordMsg3D7BusHiSpdLatDstInvldFaildThd -> FordMsg3D7BusHiSpd.FordMsg3D7BusHiSpdLatDstInvldFaildThd
    connect CalRegn01Cmn.FordMsg3D7BusHiSpdLatDstInvldPassdThd -> FordMsg3D7BusHiSpd.FordMsg3D7BusHiSpdLatDstInvldPassdThd
    connect CalRegn01Cmn.FordMsg3D7BusHiSpdLatDstRawVldFaildThd -> FordMsg3D7BusHiSpd.FordMsg3D7BusHiSpdLatDstRawVldFaildThd
    connect CalRegn01Cmn.FordMsg3D7BusHiSpdLgtDstInvldFaildThd -> FordMsg3D7BusHiSpd.FordMsg3D7BusHiSpdLgtDstInvldFaildThd
    connect CalRegn01Cmn.FordMsg3D7BusHiSpdLgtDstInvldPassdThd -> FordMsg3D7BusHiSpd.FordMsg3D7BusHiSpdLgtDstInvldPassdThd
    connect CalRegn01Cmn.FordMsg3D7BusHiSpdLgtDstRawVldFaildThd -> FordMsg3D7BusHiSpd.FordMsg3D7BusHiSpdLgtDstRawVldFaildThd
    connect CalRegn01Cmn.FordMsg3D7BusHiSpdMissMsgFaildThd -> FordMsg3D7BusHiSpd.FordMsg3D7BusHiSpdMissMsgFaildThd
    connect CalRegn01Cmn.FordMsg3D7BusHiSpdMissMsgPassdThd -> FordMsg3D7BusHiSpd.FordMsg3D7BusHiSpdMissMsgPassdThd
    connect CalRegn01Cmn.FordMsg3D7BusHiSpdRelLatVelInvldFaildThd -> FordMsg3D7BusHiSpd.FordMsg3D7BusHiSpdRelLatVelInvldFaildThd
    connect CalRegn01Cmn.FordMsg3D7BusHiSpdRelLatVelInvldPassdThd -> FordMsg3D7BusHiSpd.FordMsg3D7BusHiSpdRelLatVelInvldPassdThd
    connect CalRegn01Cmn.FordMsg3D7BusHiSpdRelLatVelRawVldFaildThd -> FordMsg3D7BusHiSpd.FordMsg3D7BusHiSpdRelLatVelRawVldFaildThd
    connect CalRegn01Cmn.FordMsg3D7BusHiSpdRelLgtVelInvldFaildThd -> FordMsg3D7BusHiSpd.FordMsg3D7BusHiSpdRelLgtVelInvldFaildThd
    connect CalRegn01Cmn.FordMsg3D7BusHiSpdRelLgtVelInvldPassdThd -> FordMsg3D7BusHiSpd.FordMsg3D7BusHiSpdRelLgtVelInvldPassdThd
    connect CalRegn01Cmn.FordMsg3D7BusHiSpdRelLgtVelRawVldFaildThd -> FordMsg3D7BusHiSpd.FordMsg3D7BusHiSpdRelLgtVelRawVldFaildThd
    connect CalRegn01Cmn.FordMsg3D7BusHiSpdTiToCllsnInvldFaildThd -> FordMsg3D7BusHiSpd.FordMsg3D7BusHiSpdTiToCllsnInvldFaildThd
    connect CalRegn01Cmn.FordMsg3D7BusHiSpdTiToCllsnInvldPassdThd -> FordMsg3D7BusHiSpd.FordMsg3D7BusHiSpdTiToCllsnInvldPassdThd
    connect CalRegn01Cmn.FordMsg3D7BusHiSpdTiToCllsnRawVldFaildThd -> FordMsg3D7BusHiSpd.FordMsg3D7BusHiSpdTiToCllsnRawVldFaildThd
    connect CalRegn01Cmn.FordMsg40ABusHiSpdMissMsgFaildThd -> FordMsg40ABusHiSpd.FordMsg40ABusHiSpdMissMsgFaildThd
    connect CalRegn01Cmn.FordMsg40ABusHiSpdMissMsgPassdThd -> FordMsg40ABusHiSpd.FordMsg40ABusHiSpdMissMsgPassdThd
    connect CalRegn01Cmn.FordMsg414BusHiSpdAgOffsVldFaildThd -> FordMsg414BusHiSpd.FordMsg414BusHiSpdAgOffsVldFaildThd
    connect CalRegn01Cmn.FordMsg414BusHiSpdAgOffsVldMissThd -> FordMsg414BusHiSpd.FordMsg414BusHiSpdAgOffsVldMissThd
    connect CalRegn01Cmn.FordMsg414BusHiSpdAgOffsVldPassdThd -> FordMsg414BusHiSpd.FordMsg414BusHiSpdAgOffsVldPassdThd
    connect CalRegn01Cmn.FordMsg414BusHiSpdChksVldFaildThd -> FordMsg414BusHiSpd.FordMsg414BusHiSpdChksVldFaildThd
    connect CalRegn01Cmn.FordMsg414BusHiSpdChksVldMissThd -> FordMsg414BusHiSpd.FordMsg414BusHiSpdChksVldMissThd
    connect CalRegn01Cmn.FordMsg414BusHiSpdCntrVldMissThd -> FordMsg414BusHiSpd.FordMsg414BusHiSpdCntrVldMissThd
    connect CalRegn01Cmn.FordMsg415BusHiSpdBrkModlLoQlyVldFaildThd -> FordMsg415BusHiSpd.FordMsg415BusHiSpdBrkModlLoQlyVldFaildThd
    connect CalRegn01Cmn.FordMsg415BusHiSpdBrkModlLoQlyVldMissThd -> FordMsg415BusHiSpd.FordMsg415BusHiSpdBrkModlLoQlyVldMissThd
    connect CalRegn01Cmn.FordMsg415BusHiSpdBrkModlLoQlyVldPassdThd -> FordMsg415BusHiSpd.FordMsg415BusHiSpdBrkModlLoQlyVldPassdThd
    connect CalRegn01Cmn.FordMsg415BusHiSpdBrkModlVldFaildThd -> FordMsg415BusHiSpd.FordMsg415BusHiSpdBrkModlVldFaildThd
    connect CalRegn01Cmn.FordMsg415BusHiSpdBrkModlVldMissThd -> FordMsg415BusHiSpd.FordMsg415BusHiSpdBrkModlVldMissThd
    connect CalRegn01Cmn.FordMsg415BusHiSpdBrkModlVldPassdThd -> FordMsg415BusHiSpd.FordMsg415BusHiSpdBrkModlVldPassdThd
    connect CalRegn01Cmn.FordMsg415BusHiSpdBrkSprtVldMissThd -> FordMsg415BusHiSpd.FordMsg415BusHiSpdBrkSprtVldMissThd
    connect CalRegn01Cmn.FordMsg415BusHiSpdBrkSprtVldPassdThd -> FordMsg415BusHiSpd.FordMsg415BusHiSpdBrkSprtVldPassdThd
    connect CalRegn01Cmn.FordMsg415BusHiSpdChksBrkModlInvldFaildThd -> FordMsg415BusHiSpd.FordMsg415BusHiSpdChksBrkModlInvldFaildThd
    connect CalRegn01Cmn.FordMsg415BusHiSpdChksBrkModlInvldPassdThd -> FordMsg415BusHiSpd.FordMsg415BusHiSpdChksBrkModlInvldPassdThd
    connect CalRegn01Cmn.FordMsg415BusHiSpdCntrBrkModlInvldFaildThd -> FordMsg415BusHiSpd.FordMsg415BusHiSpdCntrBrkModlInvldFaildThd
    connect CalRegn01Cmn.FordMsg415BusHiSpdCntrBrkModlInvldPassdThd -> FordMsg415BusHiSpd.FordMsg415BusHiSpdCntrBrkModlInvldPassdThd
    connect CalRegn01Cmn.FordMsg415BusHiSpdMissMsgFaildThd -> FordMsg415BusHiSpd.FordMsg415BusHiSpdMissMsgFaildThd
    connect CalRegn01Cmn.FordMsg415BusHiSpdMissMsgPassdThd -> FordMsg415BusHiSpd.FordMsg415BusHiSpdMissMsgPassdThd
    connect CalRegn01Cmn.FordMsg415BusHiSpdQlyFacBrkModlInvldFaildThd -> FordMsg415BusHiSpd.FordMsg415BusHiSpdQlyFacBrkModlInvldFaildThd
    connect CalRegn01Cmn.FordMsg415BusHiSpdQlyFacBrkModlInvldSigPassdThd -> FordMsg415BusHiSpd.FordMsg415BusHiSpdQlyFacBrkModlInvldSigPassdThd
    connect CalRegn01Cmn.FordMsg41ABusHiSpdMissMsgFaildThd -> FordMsg41ABusHiSpd.FordMsg41ABusHiSpdMissMsgFaildThd
    connect CalRegn01Cmn.FordMsg41ABusHiSpdMissMsgPassdThd -> FordMsg41ABusHiSpd.FordMsg41ABusHiSpdMissMsgPassdThd
    connect CalRegn01Cmn.FordMsg41EBusHiSpdChassisVldMissFaildThd -> FordMsg41EBusHiSpd.FordMsg41EBusHiSpdChassisVldMissFaildThd
    connect CalRegn01Cmn.FordMsg41EBusHiSpdChassisVldSigFaildThd -> FordMsg41EBusHiSpd.FordMsg41EBusHiSpdChassisVldSigFaildThd
    connect CalRegn01Cmn.FordMsg41EBusHiSpdChassisVldSigPassdThd -> FordMsg41EBusHiSpd.FordMsg41EBusHiSpdChassisVldSigPassdThd
    connect CalRegn01Cmn.FordMsg41EBusHiSpdInvldMsgFaildThd -> FordMsg41EBusHiSpd.FordMsg41EBusHiSpdInvldMsgFaildThd
    connect CalRegn01Cmn.FordMsg41EBusHiSpdInvldMsgPassdThd -> FordMsg41EBusHiSpd.FordMsg41EBusHiSpdInvldMsgPassdThd
    connect CalRegn01Cmn.FordMsg41EBusHiSpdMissMsgFaildThd -> FordMsg41EBusHiSpd.FordMsg41EBusHiSpdMissMsgFaildThd
    connect CalRegn01Cmn.FordMsg41EBusHiSpdMissMsgPassdThd -> FordMsg41EBusHiSpd.FordMsg41EBusHiSpdMissMsgPassdThd
    connect CalRegn01Cmn.FordMsg430BusHiSpdMissMsgFaildThd -> FordMsg430BusHiSpd.FordMsg430BusHiSpdMissMsgFaildThd
    connect CalRegn01Cmn.FordMsg430BusHiSpdMissMsgPassdThd -> FordMsg430BusHiSpd.FordMsg430BusHiSpdMissMsgPassdThd
    connect CalRegn01Cmn.FordMsg443BusHiSpdMissMsgFaildThd -> FordMsg443BusHiSpd.FordMsg443BusHiSpdMissMsgFaildThd
    connect CalRegn01Cmn.FordMsg443BusHiSpdMissMsgPassdThd -> FordMsg443BusHiSpd.FordMsg443BusHiSpdMissMsgPassdThd
    connect CalRegn01Cmn.FordMsg459BusHiSpdDiagMsgMissTmrThd -> FordMsg459BusHiSpd.FordMsg459BusHiSpdDiagMsgMissTmrThd
    connect CalRegn01Cmn.FordMsg459BusHiSpdHitchAgInvldFaildThd -> FordMsg459BusHiSpd.FordMsg459BusHiSpdHitchAgInvldFaildThd
    connect CalRegn01Cmn.FordMsg459BusHiSpdHitchAgInvldPassdThd -> FordMsg459BusHiSpd.FordMsg459BusHiSpdHitchAgInvldPassdThd
    connect CalRegn01Cmn.FordMsg459BusHiSpdHitchAgRateInvldFaildThd -> FordMsg459BusHiSpd.FordMsg459BusHiSpdHitchAgRateInvldFaildThd
    connect CalRegn01Cmn.FordMsg459BusHiSpdHitchAgRateInvldPassdThd -> FordMsg459BusHiSpd.FordMsg459BusHiSpdHitchAgRateInvldPassdThd
    connect CalRegn01Cmn.FordMsg459BusHiSpdPrsntFlgMsgMissTmrThd -> FordMsg459BusHiSpd.FordMsg459BusHiSpdPrsntFlgMsgMissTmrThd
    connect CalRegn01Cmn.FordMsg459BusHiSpdRcvrDiagMsgMissTmrThd -> FordMsg459BusHiSpd.FordMsg459BusHiSpdRcvrDiagMsgMissTmrThd
    connect CalRegn01Cmn.FordMsg459BusHiSpdRcvrPrsntFlgTmrThd -> FordMsg459BusHiSpd.FordMsg459BusHiSpdRcvrPrsntFlgTmrThd
    connect CalRegn01Cmn.FordMsg459BusHiSpdTrackStInvldFaildThd -> FordMsg459BusHiSpd.FordMsg459BusHiSpdTrackStInvldFaildThd
    connect CalRegn01Cmn.FordMsg459BusHiSpdTrackStInvldPassdThd -> FordMsg459BusHiSpd.FordMsg459BusHiSpdTrackStInvldPassdThd
    connect CalRegn01Cmn.FordMsg459BusHiSpdTrlrHitchAgVldInvldMsgThd -> FordMsg459BusHiSpd.FordMsg459BusHiSpdTrlrHitchAgVldInvldMsgThd
    connect CalRegn01Cmn.FordMsg459BusHiSpdTrlrHitchAgVldMissMsgThd -> FordMsg459BusHiSpd.FordMsg459BusHiSpdTrlrHitchAgVldMissMsgThd
    connect CalRegn01Cmn.FordMsg459BusHiSpdTrlrHitchRateVldInvldMsgThd -> FordMsg459BusHiSpd.FordMsg459BusHiSpdTrlrHitchRateVldInvldMsgThd
    connect CalRegn01Cmn.FordMsg459BusHiSpdTrlrHitchRateVldMissMsgThd -> FordMsg459BusHiSpd.FordMsg459BusHiSpdTrlrHitchRateVldMissMsgThd
    connect CalRegn01Cmn.FordMsg459BusHiSpdTrlrRcvrHitchAgVldThd -> FordMsg459BusHiSpd.FordMsg459BusHiSpdTrlrRcvrHitchAgVldThd
    connect CalRegn01Cmn.FordMsg459BusHiSpdTrlrRcvrHitchRateVldThd -> FordMsg459BusHiSpd.FordMsg459BusHiSpdTrlrRcvrHitchRateVldThd
    connect CalRegn01Cmn.FordMsg459BusHiSpdTrlrRcvrTarVldThd -> FordMsg459BusHiSpd.FordMsg459BusHiSpdTrlrRcvrTarVldThd
    connect CalRegn01Cmn.FordMsg459BusHiSpdTrlrRcvrTrackStVldThd -> FordMsg459BusHiSpd.FordMsg459BusHiSpdTrlrRcvrTrackStVldThd
    connect CalRegn01Cmn.FordMsg459BusHiSpdTrlrTarVldMissMsgThd -> FordMsg459BusHiSpd.FordMsg459BusHiSpdTrlrTarVldMissMsgThd
    connect CalRegn01Cmn.FordMsg459BusHiSpdTrlrTrackStVldInvldMsgThd -> FordMsg459BusHiSpd.FordMsg459BusHiSpdTrlrTrackStVldInvldMsgThd
    connect CalRegn01Cmn.FordMsg459BusHiSpdTrlrTrackStVldMissMsgThd -> FordMsg459BusHiSpd.FordMsg459BusHiSpdTrlrTrackStVldMissMsgThd
    connect CalRegn01Cmn.FordMsg47ABusHiSpdMissMsgFaildTiThd -> FordMsg47ABusHiSpd.FordMsg47ABusHiSpdMissMsgFaildTiThd
    connect CalRegn01Cmn.FordMsg47ABusHiSpdMissMsgPassdTiThd -> FordMsg47ABusHiSpd.FordMsg47ABusHiSpdMissMsgPassdTiThd
    connect CalRegn01Cmn.FordMsg47ABusHiSpdTrlrAidKnobBtnFaildTiThd -> FordMsg47ABusHiSpd.FordMsg47ABusHiSpdTrlrAidKnobBtnFaildTiThd
    connect CalRegn01Cmn.FordMsg47ABusHiSpdTrlrAidKnobBtnInvldPassdTiThd -> FordMsg47ABusHiSpd.FordMsg47ABusHiSpdTrlrAidKnobBtnInvldPassdTiThd
    connect CalRegn01Cmn.FordMsg47ABusHiSpdTrlrAidKnobBtnMissTiThd -> FordMsg47ABusHiSpd.FordMsg47ABusHiSpdTrlrAidKnobBtnMissTiThd
    connect CalRegn01Cmn.FordMsg47ABusHiSpdTrlrAidKnobBtnPassdTiThd -> FordMsg47ABusHiSpd.FordMsg47ABusHiSpdTrlrAidKnobBtnPassdTiThd
    connect CalRegn01Cmn.FordMsg47ABusHiSpdTrlrAidKnobPosFaildTiThd -> FordMsg47ABusHiSpd.FordMsg47ABusHiSpdTrlrAidKnobPosFaildTiThd
    connect CalRegn01Cmn.FordMsg47ABusHiSpdTrlrAidKnobPosInvldPassdTiThd -> FordMsg47ABusHiSpd.FordMsg47ABusHiSpdTrlrAidKnobPosInvldPassdTiThd
    connect CalRegn01Cmn.FordMsg47ABusHiSpdTrlrAidKnobPosMissTiThd -> FordMsg47ABusHiSpd.FordMsg47ABusHiSpdTrlrAidKnobPosMissTiThd
    connect CalRegn01Cmn.FordMsg47ABusHiSpdTrlrAidKnobPosPassdTiThd -> FordMsg47ABusHiSpd.FordMsg47ABusHiSpdTrlrAidKnobPosPassdTiThd
    connect CalRegn01Cmn.FordMsg4B0BusHiSpdCanDtcInhbTiThd -> FordMsg4B0BusHiSpd.FordMsg4B0BusHiSpdCanDtcInhbTiThd
    connect CalRegn01Cmn.FordMsg4B0BusHiSpdMsgFltNtcDiagcTiThd -> FordMsg4B0BusHiSpd.FordMsg4B0BusHiSpdMsgFltNtcDiagcTiThd
    connect CalRegn01Cmn.FordMsg4B0BusHiSpdMsgFltTiThd -> FordMsg4B0BusHiSpd.FordMsg4B0BusHiSpdMsgFltTiThd
    connect CalRegn01Cmn.FordMsg4B0BusHiSpdMsgMissNtcDiagcTiThd -> FordMsg4B0BusHiSpd.FordMsg4B0BusHiSpdMsgMissNtcDiagcTiThd
    connect CalRegn01Cmn.FordMsg4B0BusHiSpdMsgMissTiThd -> FordMsg4B0BusHiSpd.FordMsg4B0BusHiSpdMsgMissTiThd
    connect CalRegn01Cmn.FordMsg4B0BusHiSpdMsgRxdNtcDiagcTiThd -> FordMsg4B0BusHiSpd.FordMsg4B0BusHiSpdMsgRxdNtcDiagcTiThd
    connect CalRegn01Cmn.FordMsg4B0BusHiSpdMsgVldNtcDiagcTiThd -> FordMsg4B0BusHiSpd.FordMsg4B0BusHiSpdMsgVldNtcDiagcTiThd
    connect CalRegn01Cmn.FordMsg4B0BusHiSpdMsgVldTiThd -> FordMsg4B0BusHiSpd.FordMsg4B0BusHiSpdMsgVldTiThd
    connect CalRegn01Cmn.GateDrv0CtrlErrFilFrq -> GateDrv0Ctrl.GateDrv0CtrlErrFilFrq
    connect CalRegn01Cmn.GateDrv0CtrlErrOffs -> GateDrv0Ctrl.GateDrv0CtrlErrOffs
    connect CalRegn01Cmn.GateDrv0CtrlErrThd -> GateDrv0Ctrl.GateDrv0CtrlErrThd
    connect CalRegn01Cmn.GateDrv0CtrlNtcNr0x050FailStep -> GateDrv0Ctrl.GateDrv0CtrlNtcNr0x050FailStep
    connect CalRegn01Cmn.GateDrv0CtrlNtcNr0x050PassStep -> GateDrv0Ctrl.GateDrv0CtrlNtcNr0x050PassStep
    connect CalRegn01Cmn.GateDrv0CtrlNtcNr0x051FailStep -> GateDrv0Ctrl.GateDrv0CtrlNtcNr0x051FailStep
    connect CalRegn01Cmn.GateDrv0CtrlNtcNr0x051PassStep -> GateDrv0Ctrl.GateDrv0CtrlNtcNr0x051PassStep
    connect CalRegn01Cmn.GateDrv0CtrlNtcNr0x055FailStep -> GateDrv0Ctrl.GateDrv0CtrlNtcNr0x055FailStep
    connect CalRegn01Cmn.GateDrv0CtrlNtcNr0x055PassStep -> GateDrv0Ctrl.GateDrv0CtrlNtcNr0x055PassStep
    connect CalRegn01Cmn.GateDrv0CtrlUnit0Cfg{2..4}WrVal -> GateDrv0Ctrl.GateDrv0CtrlUnit0Cfg{2..4}WrVal
    connect CalRegn01Cmn.GateDrv0CtrlUnit0Cfg7WrVal -> GateDrv0Ctrl.GateDrv0CtrlUnit0Cfg7WrVal
    connect CalRegn01Cmn.HwAgSnsrlsCorrdPinionAgConfThd -> HwAgSnsrls.HwAgSnsrlsCorrdPinionAgConfThd
    connect CalRegn01Cmn.HwAgSnsrlsCorrdPinionAgHwConf -> HwAgSnsrls.HwAgSnsrlsCorrdPinionAgHwConf
    connect CalRegn01Cmn.HwAgSnsrlsFCentrHwConf -> HwAgSnsrls.HwAgSnsrlsFCentrHwConf
    connect CalRegn01Cmn.HwAgSnsrlsMotAgIdptSigThd -> HwAgSnsrls.HwAgSnsrlsMotAgIdptSigThd
    connect CalRegn01Cmn.HwAgSnsrlsPinionTqFilFrq -> HwAgSnsrls.HwAgSnsrlsPinionTqFilFrq
    connect CalRegn01Cmn.HwAgSnsrlsRelHwAgFil1Frq -> HwAgSnsrls.HwAgSnsrlsRelHwAgFil1Frq
    connect CalRegn01Cmn.HwAgSnsrlsRelHwAgFil2Frq -> HwAgSnsrls.HwAgSnsrlsRelHwAgFil2Frq
    connect CalRegn01Cmn.HwAgSnsrlsSmotngCoeff -> HwAgSnsrls.HwAgSnsrlsSmotngCoeff
    connect CalRegn01Cmn.HwAgSnsrlsSmotngStepThd -> HwAgSnsrls.HwAgSnsrlsSmotngStepThd
    connect CalRegn01Cmn.HwAgSnsrlsStordPinionConf -> HwAgSnsrls.HwAgSnsrlsStordPinionConf
    connect CalRegn01Cmn.HwAgSnsrlsStordPinionConfThd -> HwAgSnsrls.HwAgSnsrlsStordPinionConfThd
    connect CalRegn01Cmn.HwAgSnsrlsVehDynDifThd -> HwAgSnsrls.HwAgSnsrlsVehDynDifThd
    connect CalRegn01Cmn.HwAgSnsrlsVehDynHwConf -> HwAgSnsrls.HwAgSnsrlsVehDynHwConf
    connect CalRegn01Cmn.HwAgSnsrlsVehDynMotVelThd -> HwAgSnsrls.HwAgSnsrlsVehDynMotVelThd
    connect CalRegn01Cmn.HwAgSnsrlsVehDynPinionTqThd -> HwAgSnsrls.HwAgSnsrlsVehDynPinionTqThd
    connect CalRegn01Cmn.HwAgSnsrlsVehDynTmr1Thd -> HwAgSnsrls.HwAgSnsrlsVehDynTmr1Thd
    connect CalRegn01Cmn.HwAgSnsrlsVehDynTmr2Thd -> HwAgSnsrls.HwAgSnsrlsVehDynTmr2Thd
    connect CalRegn01Cmn.HwAgSnsrlsWhlFrqThd -> HwAgSnsrls.HwAgSnsrlsWhlFrqThd
    connect CalRegn01Cmn.HwAgSnsrlsWhlSpdHwAgCoeff1 -> HwAgSnsrls.HwAgSnsrlsWhlSpdHwAgCoeff1
    connect CalRegn01Cmn.HwAgSnsrlsWhlSpdHwAgCoeff2 -> HwAgSnsrls.HwAgSnsrlsWhlSpdHwAgCoeff2
    connect CalRegn01Cmn.HwAgSnsrlsWhlSpdHwAgThd -> HwAgSnsrls.HwAgSnsrlsWhlSpdHwAgThd
    connect CalRegn01Cmn.HwAgSnsrlsWhlSpdHwConf -> HwAgSnsrls.HwAgSnsrlsWhlSpdHwConf
    connect CalRegn01Cmn.HwAgSnsrlsWhlSpdRatThd -> HwAgSnsrls.HwAgSnsrlsWhlSpdRatThd
    connect CalRegn01Cmn.HwAgSnsrlsWhlSpdTmrThd -> HwAgSnsrls.HwAgSnsrlsWhlSpdTmrThd
    connect CalRegn01Cmn.HwAgSnsrlsWhlSpdVehSpdThd -> HwAgSnsrls.HwAgSnsrlsWhlSpdVehSpdThd
    connect CalRegn01Cmn.HwAgSysArbnHwAgConf1Snsr -> HwAgSysArbn.HwAgSysArbnHwAgConf1Snsr
    connect CalRegn01Cmn.HwAgSysArbnHwAgConf1SnsrHwAgTrimNotPrfmd -> HwAgSysArbn.HwAgSysArbnHwAgConf1SnsrHwAgTrimNotPrfmd
    connect CalRegn01Cmn.HwAgSysArbnHwAgConf2Snsr -> HwAgSysArbn.HwAgSysArbnHwAgConf2Snsr
    connect CalRegn01Cmn.HwAgSysArbnHwAgConf2SnsrHwAgTrimNotPrfmd -> HwAgSysArbn.HwAgSysArbnHwAgConf2SnsrHwAgTrimNotPrfmd
    connect CalRegn01Cmn.HwAgSysArbnHwAgConfNoSnsr -> HwAgSysArbn.HwAgSysArbnHwAgConfNoSnsr
    connect CalRegn01Cmn.HwAgSysArbnHwAgConfTiThd -> HwAgSysArbn.HwAgSysArbnHwAgConfTiThd
    connect CalRegn01Cmn.HwAgSysArbnHwAgCorrdCorrlnThd -> HwAgSysArbn.HwAgSysArbnHwAgCorrdCorrlnThd
    connect CalRegn01Cmn.HwAgSysArbnHwAgCorrlnFailDebStep -> HwAgSysArbn.HwAgSysArbnHwAgCorrlnFailDebStep
    connect CalRegn01Cmn.HwAgSysArbnHwAgCorrlnPassDebStep -> HwAgSysArbn.HwAgSysArbnHwAgCorrlnPassDebStep
    connect CalRegn01Cmn.HwAgSysArbnHwAgCorrlnRng -> HwAgSysArbn.HwAgSysArbnHwAgCorrlnRng
    connect CalRegn01Cmn.HwAgSysArbnHwAgIdptSigLim -> HwAgSysArbn.HwAgSysArbnHwAgIdptSigLim
    connect CalRegn01Cmn.HwAgSysArbnHwAgSlewRate -> HwAgSysArbn.HwAgSysArbnHwAgSlewRate
    connect CalRegn01Cmn.HwAgSysArbnHwAgSnsrlsCorrlnThd -> HwAgSysArbn.HwAgSysArbnHwAgSnsrlsCorrlnThd
    connect CalRegn01Cmn.HwAgSysArbnHwAgSnsrlsKineThd -> HwAgSysArbn.HwAgSysArbnHwAgSnsrlsKineThd
    connect CalRegn01Cmn.HwAgSysArbnImcHwAgCorrlnRng -> HwAgSysArbn.HwAgSysArbnImcHwAgCorrlnRng
    connect CalRegn01Cmn.HwAgSysArbnPinionAgConfThd -> HwAgSysArbn.HwAgSysArbnPinionAgConfThd
    connect CalRegn01Cmn.HwAgSysArbnSerlComHwAgCorrdConf -> HwAgSysArbn.HwAgSysArbnSerlComHwAgCorrdConf
    connect CalRegn01Cmn.HwAgSysArbnSerlComHwAgSnsrlsConf -> HwAgSysArbn.HwAgSysArbnSerlComHwAgSnsrlsConf
    connect CalRegn01Cmn.HwAgSysArbnSlewRateTmr -> HwAgSysArbn.HwAgSysArbnSlewRateTmr
    connect CalRegn01Cmn.HwTqArbnHwTqMaxStallCnt -> HwTqArbn.HwTqArbnHwTqMaxStallCnt
    connect CalRegn01Cmn.HwTqArbnHwTqMaxStallCnt -> HwTqCorrln.HwTqArbnHwTqMaxStallCnt
    connect CalRegn01Cmn.HwTqCorrlnImdtCorrlnChkFailThd -> HwTqCorrln.HwTqCorrlnImdtCorrlnChkFailThd
    connect CalRegn01Cmn.HwTqCorrlnNtcFailStep -> HwTqCorrln.HwTqCorrlnNtcFailStep
    connect CalRegn01Cmn.HwTqCorrlnNtcPassStep -> HwTqCorrln.HwTqCorrlnNtcPassStep
    connect CalRegn01Cmn.ImcArbnEcuIninTiOutThd -> ImcArbn.ImcArbnEcuIninTiOutThd
    connect CalRegn01Cmn.ImcArbnFrmFltThd -> ImcArbn.ImcArbnFrmFltThd
    connect CalRegn01Cmn.LoaMgrCurrIvtrMtgtnScaZeroEna -> LoaMgr.LoaMgrCurrIvtrMtgtnScaZeroEna
    connect CalRegn01Cmn.LoaMgrCurrMeasIdptSig{0..2}Resp -> LoaMgr.LoaMgrCurrMeasIdptSig{0..2}Resp
    connect CalRegn01Cmn.LoaMgrCurrMeasIdptSigFltThd -> LoaMgr.LoaMgrCurrMeasIdptSigFltThd
    connect CalRegn01Cmn.LoaMgrCurrMeasMtgtnScaZeroEna -> LoaMgr.LoaMgrCurrMeasMtgtnScaZeroEna
    connect CalRegn01Cmn.LoaMgrFadeOutStRate -> LoaMgr.LoaMgrFadeOutStRate
    connect CalRegn01Cmn.LoaMgrHwTqIdptSig0NoTqLoaResp -> LoaMgr.LoaMgrHwTqIdptSig0NoTqLoaResp
    connect CalRegn01Cmn.LoaMgrHwTqIdptSig1NoTqLoaResp -> LoaMgr.LoaMgrHwTqIdptSig1NoTqLoaResp
    connect CalRegn01Cmn.LoaMgrHwTqIdptSig{2..4}Resp -> LoaMgr.LoaMgrHwTqIdptSig{2..4}Resp
    connect CalRegn01Cmn.LoaMgrHwTqIdptSigFltThd -> LoaMgr.LoaMgrHwTqIdptSigFltThd
    connect CalRegn01Cmn.LoaMgrHwTqLoaAvlResp -> LoaMgr.LoaMgrHwTqLoaAvlResp
    connect CalRegn01Cmn.LoaMgrIvtrIdptSig{0..2}Resp -> LoaMgr.LoaMgrIvtrIdptSig{0..2}Resp
    connect CalRegn01Cmn.LoaMgrIvtrIdptSigFltThd -> LoaMgr.LoaMgrIvtrIdptSigFltThd
    connect CalRegn01Cmn.LoaMgrIvtrMtgtnScaZeroEna -> LoaMgr.LoaMgrIvtrMtgtnScaZeroEna
    connect CalRegn01Cmn.LoaMgrMotAgAvlSnsrlsResp -> LoaMgr.LoaMgrMotAgAvlSnsrlsResp
    connect CalRegn01Cmn.LoaMgrMotAgIdptSig0NoSnsrlsResp -> LoaMgr.LoaMgrMotAgIdptSig0NoSnsrlsResp
    connect CalRegn01Cmn.LoaMgrMotAgIdptSig1NoSnsrlsResp -> LoaMgr.LoaMgrMotAgIdptSig1NoSnsrlsResp
    connect CalRegn01Cmn.LoaMgrMotAgIdptSig2Resp -> LoaMgr.LoaMgrMotAgIdptSig2Resp
    connect CalRegn01Cmn.LoaMgrMotAgIdptSig3Resp -> LoaMgr.LoaMgrMotAgIdptSig3Resp
    connect CalRegn01Cmn.LoaMgrMotAgIdptSigFltThd -> LoaMgr.LoaMgrMotAgIdptSigFltThd
    connect CalRegn01Cmn.LoaMgrMotAgMtgtnScaZeroEna -> LoaMgr.LoaMgrMotAgMtgtnScaZeroEna
    connect CalRegn01Cmn.MotAg2MeasOffs -> MotAg2Meas.MotAg2MeasOffs
    connect CalRegn01Cmn.MotCtrlPrmEstimnFetRNom -> MotCtrlPrmEstimn.MotCtrlPrmEstimnFetRNom
    connect CalRegn01Cmn.MotCtrlPrmEstimnFetThermCoeff -> MotCtrlPrmEstimn.MotCtrlPrmEstimnFetThermCoeff
    connect CalRegn01Cmn.MotCtrlPrmEstimnMagThermCoeff -> MotCtrlPrmEstimn.MotCtrlPrmEstimnMagThermCoeff
    connect CalRegn01Cmn.MotCtrlPrmEstimnMotBackEmfConHiLim -> MotCtrlPrmEstimn.MotCtrlPrmEstimnMotBackEmfConHiLim
    connect CalRegn01Cmn.MotCtrlPrmEstimnMotBackEmfConLoLim -> MotCtrlPrmEstimn.MotCtrlPrmEstimnMotBackEmfConLoLim
    connect CalRegn01Cmn.MotCtrlPrmEstimnMotBackEmfConNom -> MotCtrlPrmEstimn.MotCtrlPrmEstimnMotBackEmfConNom
    connect CalRegn01Cmn.MotCtrlPrmEstimnMotBackEmfConSatnScaIvtrLoaMtgtn -> MotCtrlPrmEstimn.MotCtrlPrmEstimnMotBackEmfConSatnScaIvtrLoaMtgtn
    connect CalRegn01Cmn.MotCtrlPrmEstimnMotBackEmfConSatnX -> MotCtrlPrmEstimn.MotCtrlPrmEstimnMotBackEmfConSatnX
    connect CalRegn01Cmn.MotCtrlPrmEstimnMotBackEmfConSatnY -> MotCtrlPrmEstimn.MotCtrlPrmEstimnMotBackEmfConSatnY
    connect CalRegn01Cmn.MotCtrlPrmEstimnMotCurrDaxInduSatnBilnrSeln -> MotCtrlPrmEstimn.MotCtrlPrmEstimnMotCurrDaxInduSatnBilnrSeln
    connect CalRegn01Cmn.MotCtrlPrmEstimnMotCurrQaxInduSatnX -> MotCtrlPrmEstimn.MotCtrlPrmEstimnMotCurrQaxInduSatnX
    connect CalRegn01Cmn.MotCtrlPrmEstimnMotInduDaxHiLim -> MotCtrlPrmEstimn.MotCtrlPrmEstimnMotInduDaxHiLim
    connect CalRegn01Cmn.MotCtrlPrmEstimnMotInduDaxIvtrLoaMtgtn -> MotCtrlPrmEstimn.MotCtrlPrmEstimnMotInduDaxIvtrLoaMtgtn
    connect CalRegn01Cmn.MotCtrlPrmEstimnMotInduDaxLoLim -> MotCtrlPrmEstimn.MotCtrlPrmEstimnMotInduDaxLoLim
    connect CalRegn01Cmn.MotCtrlPrmEstimnMotInduDaxNom -> MotCtrlPrmEstimn.MotCtrlPrmEstimnMotInduDaxNom
    connect CalRegn01Cmn.MotCtrlPrmEstimnMotInduDaxSatnScaY -> MotCtrlPrmEstimn.MotCtrlPrmEstimnMotInduDaxSatnScaY
    connect CalRegn01Cmn.MotCtrlPrmEstimnMotInduQaxHiLim -> MotCtrlPrmEstimn.MotCtrlPrmEstimnMotInduQaxHiLim
    connect CalRegn01Cmn.MotCtrlPrmEstimnMotInduQaxIvtrLoaMtgtn -> MotCtrlPrmEstimn.MotCtrlPrmEstimnMotInduQaxIvtrLoaMtgtn
    connect CalRegn01Cmn.MotCtrlPrmEstimnMotInduQaxLoLim -> MotCtrlPrmEstimn.MotCtrlPrmEstimnMotInduQaxLoLim
    connect CalRegn01Cmn.MotCtrlPrmEstimnMotInduQaxNom -> MotCtrlPrmEstimn.MotCtrlPrmEstimnMotInduQaxNom
    connect CalRegn01Cmn.MotCtrlPrmEstimnMotInduQaxSatnScaY -> MotCtrlPrmEstimn.MotCtrlPrmEstimnMotInduQaxSatnScaY
    connect CalRegn01Cmn.MotCtrlPrmEstimnMotRHiLim -> MotCtrlPrmEstimn.MotCtrlPrmEstimnMotRHiLim
    connect CalRegn01Cmn.MotCtrlPrmEstimnMotRLoLim -> MotCtrlPrmEstimn.MotCtrlPrmEstimnMotRLoLim
    connect CalRegn01Cmn.MotCtrlPrmEstimnMotRNom -> MotCtrlPrmEstimn.MotCtrlPrmEstimnMotRNom
    connect CalRegn01Cmn.MotCtrlPrmEstimnMotWidgThermCoeff -> MotCtrlPrmEstimn.MotCtrlPrmEstimnMotWidgThermCoeff
    connect CalRegn01Cmn.MotCtrlPrmEstimnTNom -> MotCtrlPrmEstimn.MotCtrlPrmEstimnTNom
    connect CalRegn01Cmn.MotCurrPeakEstimnCurrFilFrq -> MotCurrPeakEstimn.MotCurrPeakEstimnCurrFilFrq
    connect CalRegn01Cmn.MotCurrPeakEstimnCurrPeakEstimdFilFrq -> MotCurrPeakEstimn.MotCurrPeakEstimnCurrPeakEstimdFilFrq
    connect CalRegn01Cmn.MotCurrRegCfgCtrlrDynGainVehSpdCutOff -> MotCurrRegCfg.MotCurrRegCfgCtrlrDynGainVehSpdCutOff
    connect CalRegn01Cmn.MotCurrRegCfgCurrLoopSecOrderTrfFctEna -> MotCurrRegCfg.MotCurrRegCfgCurrLoopSecOrderTrfFctEna
    connect CalRegn01Cmn.MotCurrRegCfgIntglGainSampleTi -> MotCurrRegCfg.MotCurrRegCfgIntglGainSampleTi
    connect CalRegn01Cmn.MotCurrRegCfgMotAgCompuDly -> MotCurrRegCfg.MotCurrRegCfgMotAgCompuDly
    connect CalRegn01Cmn.MotCurrRegCfgMotClsdLoopBwDaxY -> MotCurrRegCfg.MotCurrRegCfgMotClsdLoopBwDaxY
    connect CalRegn01Cmn.MotCurrRegCfgMotClsdLoopBwQaxY -> MotCurrRegCfg.MotCurrRegCfgMotClsdLoopBwQaxY
    connect CalRegn01Cmn.MotCurrRegCfgMotCtrlPrmSelnX -> MotCurrRegCfg.MotCurrRegCfgMotCtrlPrmSelnX
    connect CalRegn01Cmn.MotCurrRegCfgMotDampgRatDax -> MotCurrRegCfg.MotCurrRegCfgMotDampgRatDax
    connect CalRegn01Cmn.MotCurrRegCfgMotDampgRatQax -> MotCurrRegCfg.MotCurrRegCfgMotDampgRatQax
    connect CalRegn01Cmn.MotCurrRegCfgMotNatFrqDaxY -> MotCurrRegCfg.MotCurrRegCfgMotNatFrqDaxY
    connect CalRegn01Cmn.MotCurrRegCfgMotNatFrqQaxY -> MotCurrRegCfg.MotCurrRegCfgMotNatFrqQaxY
    connect CalRegn01Cmn.MotCurrRegCfgMotRVirtDax -> MotCurrRegCfg.MotCurrRegCfgMotRVirtDax
    connect CalRegn01Cmn.MotCurrRegCfgMotRVirtQax -> MotCurrRegCfg.MotCurrRegCfgMotRVirtQax
    connect CalRegn01Cmn.MotCurrRegCfgMotVelFilFrq -> MotCurrRegCfg.MotCurrRegCfgMotVelFilFrq
    connect CalRegn01Cmn.MotRefMdlFbCtrlDi -> MotCurrRegCfg.MotRefMdlFbCtrlDi
    connect CalRegn01Cmn.MotQuadDetnMotDirHysInsts -> MotQuadDetn.MotQuadDetnMotDirHysInsts
    connect CalRegn01Cmn.MotRefMdlCurrDaxBoostGain -> MotRefMdl.MotRefMdlCurrDaxBoostGain
    connect CalRegn01Cmn.MotRefMdlCurrDaxBoostTqScaX -> MotRefMdl.MotRefMdlCurrDaxBoostTqScaX
    connect CalRegn01Cmn.MotRefMdlCurrDaxBoostTqScaY -> MotRefMdl.MotRefMdlCurrDaxBoostTqScaY
    connect CalRegn01Cmn.MotRefMdlCurrDaxQaxRefDelta -> MotRefMdl.MotRefMdlCurrDaxQaxRefDelta
    connect CalRegn01Cmn.MotRefMdlCurrItrnTolr -> MotRefMdl.MotRefMdlCurrItrnTolr
    connect CalRegn01Cmn.MotRefMdlFbCtrlDi -> MotRefMdl.MotRefMdlFbCtrlDi
    connect CalRegn01Cmn.MotRefMdlIvtrDeadTiBrdgVltgSca -> MotRefMdl.MotRefMdlIvtrDeadTiBrdgVltgSca
    connect CalRegn01Cmn.MotRefMdlMinCurrItrnLim -> MotRefMdl.MotRefMdlMinCurrItrnLim
    connect CalRegn01Cmn.MotRefMdlMotCurrDaxMaxSca -> MotRefMdl.MotRefMdlMotCurrDaxMaxSca
    connect CalRegn01Cmn.MotRefMdlMotVelLpFilFrq -> MotRefMdl.MotRefMdlMotVelLpFilFrq
    connect CalRegn01Cmn.MotRefMdlMotVltgDerivtvTiCon -> MotRefMdl.MotRefMdlMotVltgDerivtvTiCon
    connect CalRegn01Cmn.MotRefMdlQuad13VltgSdlX -> MotRefMdl.MotRefMdlQuad13VltgSdlX
    connect CalRegn01Cmn.MotRefMdlQuad13VltgSdlY -> MotRefMdl.MotRefMdlQuad13VltgSdlY
    connect CalRegn01Cmn.MotRefMdlQuad24VltgSdlX -> MotRefMdl.MotRefMdlQuad24VltgSdlX
    connect CalRegn01Cmn.MotRefMdlQuad24VltgSdlY -> MotRefMdl.MotRefMdlQuad24VltgSdlY
    connect CalRegn01Cmn.MotRefMdlRefLocnItrnLim -> MotRefMdl.MotRefMdlRefLocnItrnLim
    connect CalRegn01Cmn.MotRefMdlTqItrnLim -> MotRefMdl.MotRefMdlTqItrnLim
    connect CalRegn01Cmn.MotRefMdlTqItrnTolr -> MotRefMdl.MotRefMdlTqItrnTolr
    connect CalRegn01Cmn.MotRefMdlVltgModDynCmpEna -> MotRefMdl.MotRefMdlVltgModDynCmpEna
    connect CalRegn01Cmn.MotRefMdlVltgOverRThdSca -> MotRefMdl.MotRefMdlVltgOverRThdSca
    connect CalRegn01Cmn.MotCtrlPrmEstimnMotBackEmfConNom -> MotRplCoggCfg.MotCtrlPrmEstimnMotBackEmfConNom
    connect CalRegn01Cmn.MotTqTranlDampgVehSpdBlndY -> MotTqTranlDampg.MotTqTranlDampgVehSpdBlndY
    connect CalRegn01Cmn.NxtrCalIdsCal0DevlpAuthor -> NxtrCalIds.NxtrCalIdsCal0DevlpAuthor
    connect CalRegn01Cmn.NxtrCalIdsCal0DevlpDesc -> NxtrCalIds.NxtrCalIdsCal0DevlpDescr
    connect CalRegn01Cmn.NxtrCalIdsCal0DevlpRelNr -> NxtrCalIds.NxtrCalIdsCal0DevlpRelNr
    connect CalRegn01Cmn.NxtrCalIdsCal0DevlpRelSt -> NxtrCalIds.NxtrCalIdsCal0DevlpRelSt
    connect CalRegn01Cmn.NxtrCalIdsCal0DevlpTiStamp -> NxtrCalIds.NxtrCalIdsCal0DevlpTiStamp
    connect CalRegn01Cmn.NxtrCalIdsCal0DevlpVers -> NxtrCalIds.NxtrCalIdsCal0DevlpVers
    connect CalRegn01Cmn.NxtrCalIdsCal2DevlpAuthor -> NxtrCalIds.NxtrCalIdsCal2DevlpAuthor
    connect CalRegn01Cmn.NxtrCalIdsCal2DevlpDesc -> NxtrCalIds.NxtrCalIdsCal2DevlpDescr
    connect CalRegn01Cmn.NxtrCalIdsCal2DevlpRelNr -> NxtrCalIds.NxtrCalIdsCal2DevlpRelNr
    connect CalRegn01Cmn.NxtrCalIdsCal2DevlpRelSt -> NxtrCalIds.NxtrCalIdsCal2DevlpRelSt
    connect CalRegn01Cmn.NxtrCalIdsCal2DevlpTiStamp -> NxtrCalIds.NxtrCalIdsCal2DevlpTiStamp
    connect CalRegn01Cmn.NxtrCalIdsCal2DevlpVers -> NxtrCalIds.NxtrCalIdsCal2DevlpVers
    connect CalRegn01Cmn.BattVltgSwdMax -> PwrDiscnct.BattVltgSwdMax
    connect CalRegn01Cmn.PwrLimrAssiRednLpFilFrq -> PwrLimr.PwrLimrAssiRednLpFilFrq
    connect CalRegn01Cmn.PwrLimrBackEmfConStdT -> PwrLimr.PwrLimrBackEmfConStdT
    connect CalRegn01Cmn.PwrLimrBrdgVltgAdjSlew -> PwrLimr.PwrLimrBrdgVltgAdjSlew
    connect CalRegn01Cmn.PwrLimrBrdgVltgAltFltAdj -> PwrLimr.PwrLimrBrdgVltgAltFltAdj
    connect CalRegn01Cmn.PwrLimrFilAssiRednThd -> PwrLimr.PwrLimrFilAssiRednThd
    connect CalRegn01Cmn.PwrLimrLoVoltAssiRcvrThd -> PwrLimr.PwrLimrLoVoltAssiRcvrThd
    connect CalRegn01Cmn.PwrLimrLoVoltAssiRcvrTi -> PwrLimr.PwrLimrLoVoltAssiRcvrTi
    connect CalRegn01Cmn.PwrLimrMotEnvlpX -> PwrLimr.PwrLimrMotEnvlpX
    connect CalRegn01Cmn.PwrLimrMotEnvlpY -> PwrLimr.PwrLimrMotEnvlpY
    connect CalRegn01Cmn.PwrLimrMotVelLpFilFrq -> PwrLimr.PwrLimrMotVelLpFilFrq
    connect CalRegn01Cmn.PwrLimrSpdAdjSlewDec -> PwrLimr.PwrLimrSpdAdjSlewDec
    connect CalRegn01Cmn.PwrLimrSpdAdjSlewEna -> PwrLimr.PwrLimrSpdAdjSlewEna
    connect CalRegn01Cmn.PwrLimrSpdAdjSlewInc -> PwrLimr.PwrLimrSpdAdjSlewInc
    connect CalRegn01Cmn.PwrLimrStdOperMotEnvlpX -> PwrLimr.PwrLimrStdOperMotEnvlpX
    connect CalRegn01Cmn.PwrLimrStdOperMotEnvlpY -> PwrLimr.PwrLimrStdOperMotEnvlpY
    connect CalRegn01Cmn.PwrLimrVltgDptMotVelOffsX -> PwrLimr.PwrLimrVltgDptMotVelOffsX
    connect CalRegn01Cmn.PwrLimrVltgDptMotVelOffsY -> PwrLimr.PwrLimrVltgDptMotVelOffsY
    connect CalRegn01Cmn.PwrSplyNtc0x07BFailStep -> PwrSply.PwrSplyNtc0x07BFailStep
    connect CalRegn01Cmn.PwrSplyNtc0x07BPassStep -> PwrSply.PwrSplyNtc0x07BPassStep
    connect CalRegn01Cmn.PwrSplyNtc0x07CFailStep -> PwrSply.PwrSplyNtc0x07CFailStep
    connect CalRegn01Cmn.PwrSplyNtc0x07CPassStep -> PwrSply.PwrSplyNtc0x07CPassStep
    connect CalRegn01Cmn.PwrSplyNtc0x07DFailStep -> PwrSply.PwrSplyNtc0x07DFailStep
    connect CalRegn01Cmn.PwrSplyNtc0x07DPassStep -> PwrSply.PwrSplyNtc0x07DPassStep
    connect CalRegn01Cmn.SysPrfmncStsAbsltCtrlTFltThd -> SysPrfmncSts.SysPrfmncStsAbsltCtrlTFltThd
    connect CalRegn01Cmn.SysPrfmncStsAssiStallLimDecThd -> SysPrfmncSts.SysPrfmncStsAssiStallLimDecThd
    connect CalRegn01Cmn.SysPrfmncStsBattDiagcHiCrit -> SysPrfmncSts.SysPrfmncStsBattDiagcHiCrit
    connect CalRegn01Cmn.SysPrfmncStsBattDiagcHiWarn -> SysPrfmncSts.SysPrfmncStsBattDiagcHiWarn
    connect CalRegn01Cmn.SysPrfmncStsBattDiagcLoCrit -> SysPrfmncSts.SysPrfmncStsBattDiagcLoCrit
    connect CalRegn01Cmn.SysPrfmncStsBattDiagcLoWarn -> SysPrfmncSts.SysPrfmncStsBattDiagcLoWarn
    connect CalRegn01Cmn.SysPrfmncStsBattVltgFilFrq -> SysPrfmncSts.SysPrfmncStsBattVltgFilFrq
    connect CalRegn01Cmn.SysPrfmncStsDutyCycLvlFltThd -> SysPrfmncSts.SysPrfmncStsDutyCycLvlFltThd
    connect CalRegn01Cmn.SysPrfmncStsLoadDptLimDecThd -> SysPrfmncSts.SysPrfmncStsLoadDptLimDecThd
    connect CalRegn01Cmn.SysPrfmncStsTDptLimThd -> SysPrfmncSts.SysPrfmncStsTDptLimThd
    connect CalRegn01Cmn.TEstimnIgnOffCtrlEna -> TEstimn.TEstimnIgnOffCtrlEna
    connect CalRegn01Cmn.TEstimnIgnOffMsgWaitTi -> TEstimn.TEstimnIgnOffMsgWaitTi
    connect CalRegn01Cmn.TqLoaDrvrTqNom -> TqLoa.TqLoaDrvrTqNom
    connect CalRegn01Cmn.TqLoaMotTqCmdLim -> TqLoa.TqLoaMotTqCmdLim
    connect CalRegn01Cmn.TqLoaMotVelAndTqBasdScaFacFallRate -> TqLoa.TqLoaMotVelAndTqBasdScaFacFallRate
    connect CalRegn01Cmn.TqLoaMotVelAndTqBasdScaFacMax -> TqLoa.TqLoaMotVelAndTqBasdScaFacMax
    connect CalRegn01Cmn.TqLoaMotVelAndTqBasdScaFacMin -> TqLoa.TqLoaMotVelAndTqBasdScaFacMin
    connect CalRegn01Cmn.TqLoaMotVelAndTqBasdScaFacRiseRate -> TqLoa.TqLoaMotVelAndTqBasdScaFacRiseRate
    connect CalRegn01Cmn.TqLoaMotVelMgnThd -> TqLoa.TqLoaMotVelMgnThd
    connect CalRegn01Cmn.TqLoaTqCmdLimY -> TqLoa.TqLoaTqCmdLimY
    connect CalRegn01Cmn.TqLoaTqCmdMgnThd -> TqLoa.TqLoaTqCmdMgnThd
    connect CalRegn01Cmn.TqLoaVehLatADifScaFacFallRate -> TqLoa.TqLoaVehLatADifScaFacFallRate
    connect CalRegn01Cmn.TqLoaVehLatADifScaFacRiseRate -> TqLoa.TqLoaVehLatADifScaFacRiseRate
    connect CalRegn01Cmn.TqLoaVehLatADifScaFacX -> TqLoa.TqLoaVehLatADifScaFacX
    connect CalRegn01Cmn.TqLoaVehLatADifScaFacY -> TqLoa.TqLoaVehLatADifScaFacY
    connect CalRegn01Cmn.TqLoaVehLatAEstimnFilFrq -> TqLoa.TqLoaVehLatAEstimnFilFrq
    connect CalRegn01Cmn.TqLoaVehLatAGainY -> TqLoa.TqLoaVehLatAGainY
    connect CalRegn01Cmn.TqLoaVehSpdScaFacX -> TqLoa.TqLoaVehSpdScaFacX
    connect CalRegn01Cmn.TqLoaVehSpdScaFacY -> TqLoa.TqLoaVehSpdScaFacY
    connect CalRegn01Cmn.TqLoaVehSpdX -> TqLoa.TqLoaVehSpdX
    connect CalRegn01Cmn.TqLoaVehSteerRat -> TqLoa.TqLoaVehSteerRat
    connect CalRegn01Cmn.TqLoaVehUnderSteerGrdt -> TqLoa.TqLoaVehUnderSteerGrdt
    connect CalRegn01Cmn.TqLoaVehWhlBas -> TqLoa.TqLoaVehWhlBas
    connect CalRegn01Cmn.VehSigCdngDftLatA -> VehSigCdng.VehSigCdngDftLatA
    connect CalRegn01Cmn.VehSigCdngDftLgtA -> VehSigCdng.VehSigCdngDftLgtA
    connect CalRegn01Cmn.VehSigCdngDftVehSpd -> VehSigCdng.VehSigCdngDftVehSpd
    connect CalRegn01Cmn.VehSigCdngDftYawRate -> VehSigCdng.VehSigCdngDftYawRate
    connect CalRegn01Cmn.VehSigCdngLatADifThd -> VehSigCdng.VehSigCdngLatADifThd
    connect CalRegn01Cmn.VehSigCdngLatAFilFrq -> VehSigCdng.VehSigCdngLatAFilFrq
    connect CalRegn01Cmn.VehSigCdngLtgADifThd -> VehSigCdng.VehSigCdngLtgADifThd
    connect CalRegn01Cmn.VehSigCdngVehSpdDifThd -> VehSigCdng.VehSigCdngVehSpdDifThd
    connect CalRegn01Cmn.VehSigCdngVehYawSlewRate -> VehSigCdng.VehSigCdngVehYawSlewRate
    connect CalRegn01Cmn.VehSigCdngYawRateDifThd -> VehSigCdng.VehSigCdngYawRateDifThd
    connect CalRegn01Cmn.VehSpdLimrMaxAssiX -> VehSpdLimr.VehSpdLimrMaxAssiX
    connect CalRegn01Cmn.VehSpdLimrMaxAssiY -> VehSpdLimr.VehSpdLimrMaxAssiY
    connect CalRegn01Cmn.VehSpdLimrPosMaxOffs1 -> VehSpdLimr.VehSpdLimrPosMaxOffs1
    connect CalRegn01Cmn.VehSpdLimrPosMaxOffs2 -> VehSpdLimr.VehSpdLimrPosMaxOffs2
    connect CalRegn01CmnGroupA.DampgQuadHwTqBacklsh -> Dampg.DampgQuadHwTqBacklsh
    connect CalRegn01CmnGroupA.DampgQuadMotVelBacklsh -> Dampg.DampgQuadMotVelBacklsh
    connect CalRegn01CmnGroupA.ElecPwrCnsPrstcPwrLoss -> ElecPwrCns.ElecPwrCnsPrstcPwrLoss
    connect CalRegn01CmnGroupA.TunSelnAuthyHwTqY -> TunSelnAuthy.TunSelnAuthyHwTqY
    connect CalRegn01CmnGroupA.TunSelnAuthyHwVelY -> TunSelnAuthy.TunSelnAuthyHwVelY
    connect CalRegn01CmnGroupA.TunSelnAuthyTunSelnRtDiCmd -> TunSelnAuthy.TunSelnAuthyTunSelnRtDiCmd
    connect CalRegn01Inin00.SysGlbPrmVehSpdBilnrSeln -> Assi.SysGlbPrmVehSpdBilnrSeln
    connect CalRegn01Inin00.SysGlbPrmVehSpdBilnrSeln -> AssiHiFrq.SysGlbPrmVehSpdBilnrSeln
    connect CalRegn01Inin00.AssiSumLimBlndCmdSumFrqLimX -> AssiSumLim.AssiSumLimBlndCmdSumFrqLimX
    connect CalRegn01Inin00.AssiSumLimBlndCmdSumFrqLimY -> AssiSumLim.AssiSumLimBlndCmdSumFrqLimY
    connect CalRegn01Inin00.AssiSumLimHiSpdCmdSumFrqLimX -> AssiSumLim.AssiSumLimHiSpdCmdSumFrqLimX
    connect CalRegn01Inin00.AssiSumLimHiSpdCmdSumFrqLimY -> AssiSumLim.AssiSumLimHiSpdCmdSumFrqLimY
    connect CalRegn01Inin00.AssiSumLimLoSpdCmdSumFrqLimX -> AssiSumLim.AssiSumLimLoSpdCmdSumFrqLimX
    connect CalRegn01Inin00.AssiSumLimLoSpdCmdSumFrqLimY -> AssiSumLim.AssiSumLimLoSpdCmdSumFrqLimY
    connect CalRegn01Inin00.AssiSumLimMotVelLpFilFrq -> AssiSumLim.AssiSumLimMotVelLpFilFrq
    connect CalRegn01Inin00.SysGlbPrmMotPoleCnt -> CDD_CurrMeas.SysGlbPrmMotPoleCnt
    connect CalRegn01Inin00.SysGlbPrmVehSpdBilnrSeln -> CDD_FordBlaBoxIfCmp1.SysGlbPrmVehSpdBilnrSeln
    connect CalRegn01Inin00.HwTq1MeasHwTq1PrtclFltFailStep -> CDD_HwTq1Meas.HwTq1MeasHwTq1PrtclFltFailStep
    connect CalRegn01Inin00.HwTq1MeasHwTq1PrtclFltPassStep -> CDD_HwTq1Meas.HwTq1MeasHwTq1PrtclFltPassStep
    connect CalRegn01Inin00.HwTq8MeasHwTq8PrtclFltFailStep -> CDD_HwTq8Meas.HwTq8MeasHwTq8PrtclFltFailStep
    connect CalRegn01Inin00.HwTq8MeasHwTq8PrtclFltPassStep -> CDD_HwTq8Meas.HwTq8MeasHwTq8PrtclFltPassStep
    connect CalRegn01Inin00.McuDiagc2MilliSecCntrCompThd -> CDD_McuDiagc.McuDiagc2MilliSecCntrCompThd
    connect CalRegn01Inin00.McuDiagcFltFailStep -> CDD_McuDiagc.McuDiagcFltFailStep
    connect CalRegn01Inin00.McuDiagcFltPassStep -> CDD_McuDiagc.McuDiagcFltPassStep
    connect CalRegn01Inin00.SysGlbPrmMotPoleCnt -> CDD_MotAgCmp.SysGlbPrmMotPoleCnt
    connect CalRegn01Inin00.CmplncErrHwAgNonLinCmplncDepTblY -> CmplncErr.CmplncErrHwAgNonLinCmplncDepTblY
    connect CalRegn01Inin00.CmplncErrHwAgNonLinCmplncIndTblX -> CmplncErr.CmplncErrHwAgNonLinCmplncIndTblX
    connect CalRegn01Inin00.CmplncErrMotAgNonLinCmplncDepTblY -> CmplncErr.CmplncErrMotAgNonLinCmplncDepTblY
    connect CalRegn01Inin00.CmplncErrMotAgNonLinCmplncIndTblX -> CmplncErr.CmplncErrMotAgNonLinCmplncIndTblX
    connect CalRegn01Inin00.SysGlbPrmVehSpdBilnrSeln -> Dampg.SysGlbPrmVehSpdBilnrSeln
    connect CalRegn01Inin00.SysGlbPrmSysTqRat -> DrvrTqEstimn.SysGlbPrmSysTqRat
    connect CalRegn01Inin00.DualCtrlrOutpMgrConOutpSca -> DualCtrlrOutpMgr.DualCtrlrOutpMgrConOutpSca
    connect CalRegn01Inin00.DualCtrlrOutpMgrDiRateTblY -> DualCtrlrOutpMgr.DualCtrlrOutpMgrDiRateTblY
    connect CalRegn01Inin00.DualCtrlrOutpMgrEnaRate -> DualCtrlrOutpMgr.DualCtrlrOutpMgrEnaRate
    connect CalRegn01Inin00.DualCtrlrOutpMgrFltThdTmr -> DualCtrlrOutpMgr.DualCtrlrOutpMgrFltThdTmr
    connect CalRegn01Inin00.DualCtrlrOutpMgrLimdOutpSca -> DualCtrlrOutpMgr.DualCtrlrOutpMgrLimdOutpSca
    connect CalRegn01Inin00.DualCtrlrOutpMgrMaxOutpSca -> DualCtrlrOutpMgr.DualCtrlrOutpMgrMaxOutpSca
    connect CalRegn01Inin00.DualCtrlrOutpMgrMaxOutpTmr -> DualCtrlrOutpMgr.DualCtrlrOutpMgrMaxOutpTmr
    connect CalRegn01Inin00.DualCtrlrOutpMgrMinOutpTmr -> DualCtrlrOutpMgr.DualCtrlrOutpMgrMinOutpTmr
    connect CalRegn01Inin00.DualCtrlrOutpMgrNonRecFltThdTmr -> DualCtrlrOutpMgr.DualCtrlrOutpMgrNonRecFltThdTmr
    connect CalRegn01Inin00.DualCtrlrOutpMgrThdTmr -> DualCtrlrOutpMgr.DualCtrlrOutpMgrThdTmr
    connect CalRegn01Inin00.DualCtrlrOutpMgrVehSpdRefTblX -> DualCtrlrOutpMgr.DualCtrlrOutpMgrVehSpdRefTblX
    connect CalRegn01Inin00.DualCtrlrOutpMgrVltgModFltThdTmr -> DualCtrlrOutpMgr.DualCtrlrOutpMgrVltgModFltThdTmr
    connect CalRegn01Inin00.HwAg1MeasHwAg1IfFltFailStep -> HwAg1Meas.HwAg1MeasHwAg1IfFltFailStep
    connect CalRegn01Inin00.HwAg1MeasHwAg1IfFltPassStep -> HwAg1Meas.HwAg1MeasHwAg1IfFltPassStep
    connect CalRegn01Inin00.HwAg1MeasHwAg1Snsr0PrtclFltFailStep -> HwAg1Meas.HwAg1MeasHwAg1Snsr0PrtclFltFailStep
    connect CalRegn01Inin00.HwAg1MeasHwAg1Snsr0PrtclFltPassStep -> HwAg1Meas.HwAg1MeasHwAg1Snsr0PrtclFltPassStep
    connect CalRegn01Inin00.HwAg1MeasHwAg1Snsr1PrtclFltFailStep -> HwAg1Meas.HwAg1MeasHwAg1Snsr1PrtclFltFailStep
    connect CalRegn01Inin00.HwAg1MeasHwAg1Snsr1PrtclFltPassStep -> HwAg1Meas.HwAg1MeasHwAg1Snsr1PrtclFltPassStep
    connect CalRegn01Inin00.HwAg1MeasSnsr0Rev -> HwAg1Meas.HwAg1MeasSnsr0Rev
    connect CalRegn01Inin00.HwAg1MeasSnsr1Rev -> HwAg1Meas.HwAg1MeasSnsr1Rev
    connect CalRegn01Inin00.HwAg1MeasStep -> HwAg1Meas.HwAg1MeasStep
    connect CalRegn01Inin00.HwAg1MeasVrnrErrThd -> HwAg1Meas.HwAg1MeasVrnrErrThd
    connect CalRegn01Inin00.HwAgSnsrlsFeatEna -> HwAgSnsrls.HwAgSnsrlsFeatEna
    connect CalRegn01Inin00.HwAgSnsrlsVehDynVehSpdThd -> HwAgSnsrls.HwAgSnsrlsVehDynVehSpdThd
    connect CalRegn01Inin00.HwAgSnsrlsVehDynYawRateThd -> HwAgSnsrls.HwAgSnsrlsVehDynYawRateThd
    connect CalRegn01Inin00.HwAgSnsrlsYawRateFilFrq -> HwAgSnsrls.HwAgSnsrlsYawRateFilFrq
    connect CalRegn01Inin00.SysGlbPrmSysTqRat -> HwAgSnsrls.SysGlbPrmSysTqRat
    connect CalRegn01Inin00.HwAgSysArbn2PinionPosSnsrAvl -> HwAgSysArbn.HwAgSysArbn2PinionPosSnsrAvl
    connect CalRegn01Inin00.HwAgSysArbnTqSnsrVelFilFrq -> HwAgSysArbn.HwAgSysArbnTqSnsrVelFilFrq
    connect CalRegn01Inin00.SysGlbPrmTorsBarStfn -> HwAgSysArbn.SysGlbPrmTorsBarStfn
    connect CalRegn01Inin00.SysGlbPrmSysTqRat -> HysCmp.SysGlbPrmSysTqRat
    connect CalRegn01Inin00.SysGlbPrmVehSpdBilnrSeln -> HysCmp.SysGlbPrmVehSpdBilnrSeln
    connect CalRegn01Inin00.ImcSigArbnArbnFltTmr -> ImcSigArbn.ImcSigArbnArbnFltTmr
    connect CalRegn01Inin00.ImcSigArbnHwAgArbnEna -> ImcSigArbn.ImcSigArbnHwAgArbnEna
    connect CalRegn01Inin00.ImcSigArbnHwAgArbnLpFil -> ImcSigArbn.ImcSigArbnHwAgArbnLpFil
    connect CalRegn01Inin00.ImcSigArbnHwAgArbnOffsLim -> ImcSigArbn.ImcSigArbnHwAgArbnOffsLim
    connect CalRegn01Inin00.ImcSigArbnHwAgTarArbnEna -> ImcSigArbn.ImcSigArbnHwAgTarArbnEna
    connect CalRegn01Inin00.ImcSigArbnHwAgTarArbnLpFil -> ImcSigArbn.ImcSigArbnHwAgTarArbnLpFil
    connect CalRegn01Inin00.ImcSigArbnHwAgTarArbnOffsLim -> ImcSigArbn.ImcSigArbnHwAgTarArbnOffsLim
    connect CalRegn01Inin00.ImcSigArbnHwTqArbnEna -> ImcSigArbn.ImcSigArbnHwTqArbnEna
    connect CalRegn01Inin00.ImcSigArbnHwTqArbnLpFil -> ImcSigArbn.ImcSigArbnHwTqArbnLpFil
    connect CalRegn01Inin00.ImcSigArbnHwTqArbnOffsLim -> ImcSigArbn.ImcSigArbnHwTqArbnOffsLim
    connect CalRegn01Inin00.ImcSigArbnMotVelArbnEna -> ImcSigArbn.ImcSigArbnMotVelArbnEna
    connect CalRegn01Inin00.ImcSigArbnMotVelArbnLpFil -> ImcSigArbn.ImcSigArbnMotVelArbnLpFil
    connect CalRegn01Inin00.ImcSigArbnMotVelArbnOffsLim -> ImcSigArbn.ImcSigArbnMotVelArbnOffsLim
    connect CalRegn01Inin00.ImcSigArbnPosnServoArbnOffsLim -> ImcSigArbn.ImcSigArbnPosnServoArbnOffsLim
    connect CalRegn01Inin00.ImcSigArbnPosnServoIntgtrStArbnEna -> ImcSigArbn.ImcSigArbnPosnServoIntgtrStArbnEna
    connect CalRegn01Inin00.ImcSigArbnPosnServoIntgtrStArbnLpFil -> ImcSigArbn.ImcSigArbnPosnServoIntgtrStArbnLpFil
    connect CalRegn01Inin00.ImcSigArbnPosnTrakg1ArbnOffsLim -> ImcSigArbn.ImcSigArbnPosnTrakg1ArbnOffsLim
    connect CalRegn01Inin00.ImcSigArbnPosnTrakg2ArbnOffsLim -> ImcSigArbn.ImcSigArbnPosnTrakg2ArbnOffsLim
    connect CalRegn01Inin00.ImcSigArbnPullCmpLongTermIntgtrStArbnEna -> ImcSigArbn.ImcSigArbnPullCmpLongTermIntgtrStArbnEna
    connect CalRegn01Inin00.ImcSigArbnPullCmpLongTermIntgtrStArbnLpFil -> ImcSigArbn.ImcSigArbnPullCmpLongTermIntgtrStArbnLpFil
    connect CalRegn01Inin00.ImcSigArbnPullCmpShoTermIntgtrStArbnEna -> ImcSigArbn.ImcSigArbnPullCmpShoTermIntgtrStArbnEna
    connect CalRegn01Inin00.ImcSigArbnPullCmpShoTermIntgtrStArbnLpFil -> ImcSigArbn.ImcSigArbnPullCmpShoTermIntgtrStArbnLpFil
    connect CalRegn01Inin00.ImcSigArbnSysStTmr -> ImcSigArbn.ImcSigArbnSysStTmr
    connect CalRegn01Inin00.ImcSigArbnTrakgIntgtrSt1ArbnEna -> ImcSigArbn.ImcSigArbnTrakgIntgtrSt1ArbnEna
    connect CalRegn01Inin00.ImcSigArbnTrakgIntgtrSt1ArbnLpFil -> ImcSigArbn.ImcSigArbnTrakgIntgtrSt1ArbnLpFil
    connect CalRegn01Inin00.ImcSigArbnTrakgIntgtrSt2ArbnEna -> ImcSigArbn.ImcSigArbnTrakgIntgtrSt2ArbnEna
    connect CalRegn01Inin00.ImcSigArbnTrakgIntgtrSt2ArbnLpFil -> ImcSigArbn.ImcSigArbnTrakgIntgtrSt2ArbnLpFil
    connect CalRegn01Inin00.ImcSigArbnVehSpdArbnEna -> ImcSigArbn.ImcSigArbnVehSpdArbnEna
    connect CalRegn01Inin00.ImcSigArbnVehSpdArbnLpFil -> ImcSigArbn.ImcSigArbnVehSpdArbnLpFil
    connect CalRegn01Inin00.ImcSigArbnVehSpdArbnOffsLim -> ImcSigArbn.ImcSigArbnVehSpdArbnOffsLim
    connect CalRegn01Inin00.SysGlbPrmTorsBarStfn -> InertiaCmpVel.SysGlbPrmTorsBarStfn
    connect CalRegn01Inin00.SysGlbPrmVehSpdBilnrSeln -> InertiaCmpVel.SysGlbPrmVehSpdBilnrSeln
    connect CalRegn01Inin00.LimrCdngGainDecSlew -> LimrCdng.LimrCdngGainDecSlew
    connect CalRegn01Inin00.LimrCdngGainIncSlewX -> LimrCdng.LimrCdngGainIncSlewX
    connect CalRegn01Inin00.LimrCdngGainIncSlewY -> LimrCdng.LimrCdngGainIncSlewY
    connect CalRegn01Inin00.LimrCdngTqDecSlew -> LimrCdng.LimrCdngTqDecSlew
    connect CalRegn01Inin00.LimrCdngTqIncSlewX -> LimrCdng.LimrCdngTqIncSlewX
    connect CalRegn01Inin00.LimrCdngTqIncSlewY -> LimrCdng.LimrCdngTqIncSlewY
    connect CalRegn01Inin00.SysGlbPrmMotPoleCnt -> MotAgCorrln.SysGlbPrmMotPoleCnt
    connect CalRegn01Inin00.SysGlbPrmMotPoleCnt -> MotCurrRegCfg.SysGlbPrmMotPoleCnt
    connect CalRegn01Inin00.SysGlbPrmMotPoleCnt -> MotRefMdl.SysGlbPrmMotPoleCnt
    connect CalRegn01Inin00.SysGlbPrmMotPoleCnt -> MotRplCoggCfg.SysGlbPrmMotPoleCnt
    connect CalRegn01Inin00.MotTqCmdScaMax -> MotTqCmdSca.MotTqCmdScaMax
    connect CalRegn01Inin00.MotTqCmdScaMin -> MotTqCmdSca.MotTqCmdScaMin
    connect CalRegn01Inin00.MotTqTranlDampgCmdLim -> MotTqTranlDampg.MotTqTranlDampgCmdLim
    connect CalRegn01Inin00.MotTqTranlDampgDampgCoeff -> MotTqTranlDampg.MotTqTranlDampgDampgCoeff
    connect CalRegn01Inin00.MotTqTranlDampgRampEnd -> MotTqTranlDampg.MotTqTranlDampgRampEnd
    connect CalRegn01Inin00.MotTqTranlDampgTmrPt1 -> MotTqTranlDampg.MotTqTranlDampgTmrPt1
    connect CalRegn01Inin00.MotTqTranlDampgTmrPt2 -> MotTqTranlDampg.MotTqTranlDampgTmrPt2
    connect CalRegn01Inin00.MotTqTranlDampgVehSpdBlndX -> MotTqTranlDampg.MotTqTranlDampgVehSpdBlndX
    connect CalRegn01Inin00.MotTqTranlDampgVelThd -> MotTqTranlDampg.MotTqTranlDampgVelThd
    connect CalRegn01Inin00.SysGlbPrmSysTqRat -> PosnTrakgServo.SysGlbPrmSysTqRat
    connect CalRegn01Inin00.PwrDiscnctBattVltgExtdNormThd -> PwrDiscnct.PwrDiscnctBattVltgExtdNormThd
    connect CalRegn01Inin00.PwrDiscnctBattVltgNonExtdThd -> PwrDiscnct.PwrDiscnctBattVltgNonExtdThd
    connect CalRegn01Inin00.PwrDiscnctChrgMinDeltaExtOper -> PwrDiscnct.PwrDiscnctChrgMinDeltaExtOper
    connect CalRegn01Inin00.PwrDiscnctChrgMinDeltaNonOper -> PwrDiscnct.PwrDiscnctChrgMinDeltaNonOper
    connect CalRegn01Inin00.PwrDiscnctChrgMinDeltaNormOper -> PwrDiscnct.PwrDiscnctChrgMinDeltaNormOper
    connect CalRegn01Inin00.PwrDiscnctChrgPmpDiagOpenThd -> PwrDiscnct.PwrDiscnctChrgPmpDiagOpenThd
    connect CalRegn01Inin00.PwrDiscnctDeltaSwtClsThd -> PwrDiscnct.PwrDiscnctDeltaSwtClsThd
    connect CalRegn01Inin00.PwrDiscnctDeltaVltgClsThd -> PwrDiscnct.PwrDiscnctDeltaVltgClsThd
    connect CalRegn01Inin00.PwrDiscnctDeltaVltgOpenThd -> PwrDiscnct.PwrDiscnctDeltaVltgOpenThd
    connect CalRegn01Inin00.PwrDiscnctFltFailStep -> PwrDiscnct.PwrDiscnctFltFailStep
    connect CalRegn01Inin00.PwrDiscnctFltPassStep -> PwrDiscnct.PwrDiscnctFltPassStep
    connect CalRegn01Inin00.PwrDiscnctFltThd -> PwrDiscnct.PwrDiscnctFltThd
    connect CalRegn01Inin00.PwrDiscnctMtrMtnThd -> PwrDiscnct.PwrDiscnctMtrMtnThd
    connect CalRegn01Inin00.PwrDiscnctPwrDiscnctRtFltFailStep -> PwrDiscnct.PwrDiscnctPwrDiscnctRtFltFailStep
    connect CalRegn01Inin00.PwrDiscnctPwrDiscnctRtFltPassStep -> PwrDiscnct.PwrDiscnctPwrDiscnctRtFltPassStep
    connect CalRegn01Inin00.PwrDiscnctSwtDiagOpenThd -> PwrDiscnct.PwrDiscnctSwtDiagOpenThd
    connect CalRegn01Inin00.SysFricLrngAvrgFricFrq -> SysFricLrng.SysFricLrngAvrgFricFrq
    connect CalRegn01Inin00.SysFricLrngBasLineEolFric -> SysFricLrng.SysFricLrngBasLineEolFric
    connect CalRegn01Inin00.SysFricLrngBasLineFric -> SysFricLrng.SysFricLrngBasLineFric
    connect CalRegn01Inin00.SysFricLrngBasLineHys -> SysFricLrng.SysFricLrngBasLineHys
    connect CalRegn01Inin00.SysFricLrngBasLineRngCntr -> SysFricLrng.SysFricLrngBasLineRngCntr
    connect CalRegn01Inin00.SysFricLrngDataPrepLpFilFrq -> SysFricLrng.SysFricLrngDataPrepLpFilFrq
    connect CalRegn01Inin00.SysFricLrngDebStep -> SysFricLrng.SysFricLrngDebStep
    connect CalRegn01Inin00.SysFricLrngEolFricDifHiLim -> SysFricLrng.SysFricLrngEolFricDifHiLim
    connect CalRegn01Inin00.SysFricLrngEolFricDifLoLim -> SysFricLrng.SysFricLrngEolFricDifLoLim
    connect CalRegn01Inin00.SysFricLrngEolFricDifScagFac -> SysFricLrng.SysFricLrngEolFricDifScagFac
    connect CalRegn01Inin00.SysFricLrngFricChgWght -> SysFricLrng.SysFricLrngFricChgWght
    connect CalRegn01Inin00.SysFricLrngFricDiagcThd -> SysFricLrng.SysFricLrngFricDiagcThd
    connect CalRegn01Inin00.SysFricLrngFricHysHwAgPt -> SysFricLrng.SysFricLrngFricHysHwAgPt
    connect CalRegn01Inin00.SysFricLrngFricOffs -> SysFricLrng.SysFricLrngFricOffs
    connect CalRegn01Inin00.SysFricLrngFricOffsHiLim -> SysFricLrng.SysFricLrngFricOffsHiLim
    connect CalRegn01Inin00.SysFricLrngFricOffsLoLim -> SysFricLrng.SysFricLrngFricOffsLoLim
    connect CalRegn01Inin00.SysFricLrngFricOffsLpFilFrq -> SysFricLrng.SysFricLrngFricOffsLpFilFrq
    connect CalRegn01Inin00.SysFricLrngGain -> SysFricLrng.SysFricLrngGain
    connect CalRegn01Inin00.SysFricLrngHiFricDebStep -> SysFricLrng.SysFricLrngHiFricDebStep
    connect CalRegn01Inin00.SysFricLrngHiFricDiagcThd -> SysFricLrng.SysFricLrngHiFricDiagcThd
    connect CalRegn01Inin00.SysFricLrngHwPosnAuthyThd -> SysFricLrng.SysFricLrngHwPosnAuthyThd
    connect CalRegn01Inin00.SysFricLrngHwVelConstrLim -> SysFricLrng.SysFricLrngHwVelConstrLim
    connect CalRegn01Inin00.SysFricLrngHwVelHiLim -> SysFricLrng.SysFricLrngHwVelHiLim
    connect CalRegn01Inin00.SysFricLrngHwVelLoLim -> SysFricLrng.SysFricLrngHwVelLoLim
    connect CalRegn01Inin00.SysFricLrngIgnCycFricChgLim -> SysFricLrng.SysFricLrngIgnCycFricChgLim
    connect CalRegn01Inin00.SysFricLrngIgnCycFricOffs -> SysFricLrng.SysFricLrngIgnCycFricOffs
    connect CalRegn01Inin00.SysFricLrngIvsTrsmRatX -> SysFricLrng.SysFricLrngIvsTrsmRatX
    connect CalRegn01Inin00.SysFricLrngIvsTrsmRatY -> SysFricLrng.SysFricLrngIvsTrsmRatY
    connect CalRegn01Inin00.SysFricLrngLatAHiLim -> SysFricLrng.SysFricLrngLatAHiLim
    connect CalRegn01Inin00.SysFricLrngLatALoLim -> SysFricLrng.SysFricLrngLatALoLim
    connect CalRegn01Inin00.SysFricLrngMaskVehSpd -> SysFricLrng.SysFricLrngMaskVehSpd
    connect CalRegn01Inin00.SysFricLrngRngCntrThd -> SysFricLrng.SysFricLrngRngCntrThd
    connect CalRegn01Inin00.SysFricLrngThd -> SysFricLrng.SysFricLrngThd
    connect CalRegn01Inin00.SysFricLrngTHiLim -> SysFricLrng.SysFricLrngTHiLim
    connect CalRegn01Inin00.SysFricLrngTLoLim -> SysFricLrng.SysFricLrngTLoLim
    connect CalRegn01Inin00.SysFricLrngVehSpd -> SysFricLrng.SysFricLrngVehSpd
    connect CalRegn01Inin00.TEstimnAmbPwrMplr -> TEstimn.TEstimnAmbPwrMplr
    connect CalRegn01Inin00.TEstimnAmbTSca -> TEstimn.TEstimnAmbTSca
    connect CalRegn01Inin00.TEstimnAssiMechAmbLpFilFrq -> TEstimn.TEstimnAssiMechAmbLpFilFrq
    connect CalRegn01Inin00.TEstimnAssiMechAmbLpFilFrqDualEcuFltMtgtn -> TEstimn.TEstimnAssiMechAmbLpFilFrqDualEcuFltMtgtn
    connect CalRegn01Inin00.TEstimnAssiMechAmbLpFilFrqFetMtgtnEna -> TEstimn.TEstimnAssiMechAmbLpFilFrqFetMtgtnEna
    connect CalRegn01Inin00.TEstimnAssiMechAmbMplr -> TEstimn.TEstimnAssiMechAmbMplr
    connect CalRegn01Inin00.TEstimnAssiMechCorrLim -> TEstimn.TEstimnAssiMechCorrLim
    connect CalRegn01Inin00.TEstimnAssiMechDampgSca -> TEstimn.TEstimnAssiMechDampgSca
    connect CalRegn01Inin00.TEstimnAssiMechDftT -> TEstimn.TEstimnAssiMechDftT
    connect CalRegn01Inin00.TEstimnAssiMechLLFilCoeffA1 -> TEstimn.TEstimnAssiMechLLFilCoeffA1
    connect CalRegn01Inin00.TEstimnAssiMechLLFilCoeffB0 -> TEstimn.TEstimnAssiMechLLFilCoeffB0
    connect CalRegn01Inin00.TEstimnAssiMechLLFilCoeffB1 -> TEstimn.TEstimnAssiMechLLFilCoeffB1
    connect CalRegn01Inin00.TEstimnAssiMechSlew -> TEstimn.TEstimnAssiMechSlew
    connect CalRegn01Inin00.TEstimnCorrnTAssiMech -> TEstimn.TEstimnCorrnTAssiMech
    connect CalRegn01Inin00.TEstimnCorrnTCu -> TEstimn.TEstimnCorrnTCu
    connect CalRegn01Inin00.TEstimnCorrnTMag -> TEstimn.TEstimnCorrnTMag
    connect CalRegn01Inin00.TEstimnCorrnTSi -> TEstimn.TEstimnCorrnTSi
    connect CalRegn01Inin00.TEstimnCuAmbLpFilFrq -> TEstimn.TEstimnCuAmbLpFilFrq
    connect CalRegn01Inin00.TEstimnCuAmbLpFilFrqDualEcuFltMtgtn -> TEstimn.TEstimnCuAmbLpFilFrqDualEcuFltMtgtn
    connect CalRegn01Inin00.TEstimnCuAmbLpFilFrqFetMtgtnEna -> TEstimn.TEstimnCuAmbLpFilFrqFetMtgtnEna
    connect CalRegn01Inin00.TEstimnCuAmbMplr -> TEstimn.TEstimnCuAmbMplr
    connect CalRegn01Inin00.TEstimnCuCorrnLim -> TEstimn.TEstimnCuCorrnLim
    connect CalRegn01Inin00.TEstimnCuLLFilCoeffA1 -> TEstimn.TEstimnCuLLFilCoeffA1
    connect CalRegn01Inin00.TEstimnCuLLFilCoeffB0 -> TEstimn.TEstimnCuLLFilCoeffB0
    connect CalRegn01Inin00.TEstimnCuLLFilCoeffB1 -> TEstimn.TEstimnCuLLFilCoeffB1
    connect CalRegn01Inin00.TEstimnEngTSca -> TEstimn.TEstimnEngTSca
    connect CalRegn01Inin00.TEstimnMagAmbLpFilFrq -> TEstimn.TEstimnMagAmbLpFilFrq
    connect CalRegn01Inin00.TEstimnMagAmbLpFilFrqDualEcuFltMtgtn -> TEstimn.TEstimnMagAmbLpFilFrqDualEcuFltMtgtn
    connect CalRegn01Inin00.TEstimnMagAmbLpFilFrqFetMtgtnEna -> TEstimn.TEstimnMagAmbLpFilFrqFetMtgtnEna
    connect CalRegn01Inin00.TEstimnMagCorrnLim -> TEstimn.TEstimnMagCorrnLim
    connect CalRegn01Inin00.TEstimnMagLLFilCoeffA1 -> TEstimn.TEstimnMagLLFilCoeffA1
    connect CalRegn01Inin00.TEstimnMagLLFilCoeffB0 -> TEstimn.TEstimnMagLLFilCoeffB0
    connect CalRegn01Inin00.TEstimnMagLLFilCoeffB1 -> TEstimn.TEstimnMagLLFilCoeffB1
    connect CalRegn01Inin00.TEstimnSiAmbLpFilFrq -> TEstimn.TEstimnSiAmbLpFilFrq
    connect CalRegn01Inin00.TEstimnSiAmbLpFilFrqDualEcuFltMtgtn -> TEstimn.TEstimnSiAmbLpFilFrqDualEcuFltMtgtn
    connect CalRegn01Inin00.TEstimnSiAmbLpFilFrqFetMtgtnEna -> TEstimn.TEstimnSiAmbLpFilFrqFetMtgtnEna
    connect CalRegn01Inin00.TEstimnSiAmbMplr -> TEstimn.TEstimnSiAmbMplr
    connect CalRegn01Inin00.TEstimnSiCorrnLim -> TEstimn.TEstimnSiCorrnLim
    connect CalRegn01Inin00.TEstimnSiLLFilCoeffA1 -> TEstimn.TEstimnSiLLFilCoeffA1
    connect CalRegn01Inin00.TEstimnSiLLFilCoeffB0 -> TEstimn.TEstimnSiLLFilCoeffB0
    connect CalRegn01Inin00.TEstimnSiLLFilCoeffB1 -> TEstimn.TEstimnSiLLFilCoeffB1
    connect CalRegn01Inin00.TEstimnTauAssiMech -> TEstimn.TEstimnTauAssiMech
    connect CalRegn01Inin00.TEstimnTauCu -> TEstimn.TEstimnTauCu
    connect CalRegn01Inin00.TEstimnTauMag -> TEstimn.TEstimnTauMag
    connect CalRegn01Inin00.TEstimnTauSi -> TEstimn.TEstimnTauSi
    connect CalRegn01Inin00.TEstimnWghtAvrgTDi -> TEstimn.TEstimnWghtAvrgTDi
    connect CalRegn01Inin00.VehSigCdngLatASlewRate -> VehSigCdng.VehSigCdngLatASlewRate
    connect CalRegn01Inin00.VehSigCdngLtgASlewRate -> VehSigCdng.VehSigCdngLtgASlewRate
    connect CalRegn01Inin00GroupA.AssiPahSumHysCmpLim -> AssiPahSum.AssiPahSumHysCmpLim
    connect CalRegn01Inin00GroupA.DampgHydBasCoeff{1..4} -> Dampg.DampgHydBasCoeff{1..4}
    connect CalRegn01Inin00GroupA.DampgHydOutpLim -> Dampg.DampgHydOutpLim
    connect CalRegn01Inin00GroupA.DampgMotVelLpFilFrq -> Dampg.DampgMotVelLpFilFrq
    connect CalRegn01Inin00GroupA.DampgQuad13Mplr -> Dampg.DampgQuad13Mplr
    connect CalRegn01Inin00GroupA.DampgQuad24Mplr -> Dampg.DampgQuad24Mplr
    connect CalRegn01Inin00GroupA.DampgQuadHwTqLpFilFrq -> Dampg.DampgQuadHwTqLpFilFrq
    connect CalRegn01Inin00GroupA.DampgQuadMotVelLpFilFrq -> Dampg.DampgQuadMotVelLpFilFrq
    connect CalRegn01Inin00GroupA.DampgQuadScaLpFilFrq -> Dampg.DampgQuadScaLpFilFrq
    connect CalRegn01Inin00GroupA.DampgTScaX -> Dampg.DampgTScaX
    connect CalRegn01Inin00GroupA.DampgTScaY -> Dampg.DampgTScaY
    connect CalRegn01Inin00GroupA.ImcSigArbnPullCmpLongTermArbnOffsLim -> ImcSigArbn.ImcSigArbnPullCmpLongTermArbnOffsLim
    connect CalRegn01Inin00GroupA.ImcSigArbnPullCmpShoTermArbnOffsLim -> ImcSigArbn.ImcSigArbnPullCmpShoTermArbnOffsLim
    connect CalRegn01Inin00GroupA.TunSelnAuthyVehSpdX -> TunSelnAuthy.TunSelnAuthyVehSpdX
    connect CalRegn01Inin00GroupB.PosnTrakgServoArbnFltMtgtnLpFilCutOffFrq -> PosnTrakgServo.PosnTrakgServoArbnFltMtgtnLpFilCutOffFrq
    connect CalRegn01Inin00GroupB.PosnTrakgServoEnaBlndFacTblX -> PosnTrakgServo.PosnTrakgServoEnaBlndFacTblX
    connect CalRegn01Inin00GroupB.PosnTrakgServoEnaBlndFacTblY -> PosnTrakgServo.PosnTrakgServoEnaBlndFacTblY
    connect CalRegn01Inin00GroupB.PosnTrakgServoFfGain -> PosnTrakgServo.PosnTrakgServoFfGain
    connect CalRegn01Inin00GroupB.PosnTrakgServoFfVelGain -> PosnTrakgServo.PosnTrakgServoFfVelGain
    connect CalRegn01Inin00GroupB.PosnTrakgServoGain{1..4} -> PosnTrakgServo.PosnTrakgServoGain{1..4}
    connect CalRegn01Inin00GroupB.PosnTrakgServoGainArbnFltMtgtn -> PosnTrakgServo.PosnTrakgServoGainArbnFltMtgtn
    connect CalRegn01Inin00GroupB.PosnTrakgServoHwAgTarMgnLimTblY -> PosnTrakgServo.PosnTrakgServoHwAgTarMgnLimTblY
    connect CalRegn01Inin00GroupB.PosnTrakgServoHwAgTarRateLimTblY -> PosnTrakgServo.PosnTrakgServoHwAgTarRateLimTblY
    connect CalRegn01Inin00GroupB.PosnTrakgServoHwVelTarRateLimTblY -> PosnTrakgServo.PosnTrakgServoHwVelTarRateLimTblY
    connect CalRegn01Inin00GroupB.PosnTrakgServoIntglGain -> PosnTrakgServo.PosnTrakgServoIntglGain
    connect CalRegn01Inin00GroupB.PosnTrakgServoIntglLim -> PosnTrakgServo.PosnTrakgServoIntglLim
    connect CalRegn01Inin00GroupB.PosnTrakgServoIntgtrAntiWdupGain -> PosnTrakgServo.PosnTrakgServoIntgtrAntiWdupGain
    connect CalRegn01Inin00GroupB.PosnTrakgServoIntgtrStCorrnGain -> PosnTrakgServo.PosnTrakgServoIntgtrStCorrnGain
    connect CalRegn01Inin00GroupB.PosnTrakgServoLpFilCutOffFrq -> PosnTrakgServo.PosnTrakgServoLpFilCutOffFrq
    connect CalRegn01Inin00GroupB.PosnTrakgServoOutpAntiWdupGain -> PosnTrakgServo.PosnTrakgServoOutpAntiWdupGain
    connect CalRegn01Inin00GroupB.PosnTrakgServoOutpLim -> PosnTrakgServo.PosnTrakgServoOutpLim
    connect CalRegn01Inin00GroupB.PosnTrakgServoVehSpdTbl -> PosnTrakgServo.PosnTrakgServoVehSpdTbl
    connect CalRegn01Inin00GroupD.StabyCmpAssiScaBlndX -> StabyCmp.StabyCmpAssiScaBlndX
    connect CalRegn01Inin00GroupD.StabyCmpAssiScaBlndY -> StabyCmp.StabyCmpAssiScaBlndY
    connect CalRegn01Inin00GroupD.StabyCmpHwTqLpFilFrq -> StabyCmp.StabyCmpHwTqLpFilFrq
    connect CalRegn01Inin00GroupD.StabyCmpNotchFil{1..4}Struct -> StabyCmp.StabyCmpNotchFil{1..4}Struct
    connect CalRegn01Inin00GroupD.StabyCmpNotchFilBilnrBlndVehSpd -> StabyCmp.StabyCmpNotchFilBilnrBlndVehSpd
    connect CalRegn01Inin00GroupD.StabyCmpNotchFilBlnd02Y -> StabyCmp.StabyCmpNotchFilBlnd02Y
    connect CalRegn01Inin00GroupD.StabyCmpNotchFilBlnd04Y -> StabyCmp.StabyCmpNotchFilBlnd04Y
    connect CalRegn01Inin00GroupD.StabyCmpNotchFilBlnd12TqX -> StabyCmp.StabyCmpNotchFilBlnd12TqX
    connect CalRegn01Inin00GroupD.StabyCmpNotchFilBlnd12Y -> StabyCmp.StabyCmpNotchFilBlnd12Y
    connect CalRegn01Inin00GroupD.StabyCmpNotchFilBlnd34TqX -> StabyCmp.StabyCmpNotchFilBlnd34TqX
    connect CalRegn01Inin00GroupD.StabyCmpNotchFilBlnd34Y -> StabyCmp.StabyCmpNotchFilBlnd34Y
    connect CalRegn01Rt00.TEstimnMagAmbMplr -> AAACalRegn01Rt00_Dummy.TEstimnMagAmbMplr
    connect CalRegn01Rt00.TEstimnMagAmbMplr -> TEstimn.TEstimnMagAmbMplr
    connect CalRegn01Rt{01..05}.TEstimnMagAmbMplr -> AAACalRegn01Rt{01..05}_Dummy.TEstimnMagAmbMplr
    connect CalRegn02Cmn.FordBlaBoxIfCmnVehSteerRat -> CDD_FordBlaBoxIfCmn.FordBlaBoxIfCmnVehSteerRat
    connect CalRegn02Cmn.FordBlaBoxIfCmnVehWhlBas -> CDD_FordBlaBoxIfCmn.FordBlaBoxIfCmnVehWhlBas
    connect CalRegn02Cmn.MotRplCoggCmdHrmncOrder{1..3}Elec -> CDD_MotRplCoggCmd.MotRplCoggCmdHrmncOrder{1..3}Elec
    connect CalRegn02Cmn.NxtrCalIdsCal1DevlpDesc -> CustDiag.NxtrCalIdsCal1DevlpDesc
    connect CalRegn02Cmn.FordCanDtcInhbFactryModThd -> FordCanDtcInhb.FordCanDtcInhbFactryModThd
    connect CalRegn02Cmn.FordCanDtcInhbTransptModThd -> FordCanDtcInhb.FordCanDtcInhbTransptModThd
    connect CalRegn02Cmn.FordCmdArbnActvNiblCtrlDeactvn -> FordCmdArbn.FordCmdArbnActvNiblCtrlDeactvn
    connect CalRegn02Cmn.FordCmdArbnActvNiblCtrlDeniedActvnReq -> FordCmdArbn.FordCmdArbnActvNiblCtrlDeniedActvnReq
    connect CalRegn02Cmn.FordCmdArbnDrvrSteerDeniedActvnReq -> FordCmdArbn.FordCmdArbnDrvrSteerDeniedActvnReq
    connect CalRegn02Cmn.FordCmdArbnDrvrSteerRcmdnDeactvn -> FordCmdArbn.FordCmdArbnDrvrSteerRcmdnDeactvn
    connect CalRegn02Cmn.FordCmdArbnEvasSteerAssiDeactvn -> FordCmdArbn.FordCmdArbnEvasSteerAssiDeactvn
    connect CalRegn02Cmn.FordCmdArbnEvasSteerDeniedActvnReq -> FordCmdArbn.FordCmdArbnEvasSteerDeniedActvnReq
    connect CalRegn02Cmn.FordCmdArbnExtAgCtrlDeactvn -> FordCmdArbn.FordCmdArbnExtAgCtrlDeactvn
    connect CalRegn02Cmn.FordCmdArbnExtAgDeniedActvnReq -> FordCmdArbn.FordCmdArbnExtAgDeniedActvnReq
    connect CalRegn02Cmn.FordCmdArbnLaneDprtrWarnDeactvn -> FordCmdArbn.FordCmdArbnLaneDprtrWarnDeactvn
    connect CalRegn02Cmn.FordCmdArbnLaneDprtrWarnDeniedActvnReq -> FordCmdArbn.FordCmdArbnLaneDprtrWarnDeniedActvnReq
    connect CalRegn02Cmn.FordCmdArbnLaneKeepAssiDeactvn -> FordCmdArbn.FordCmdArbnLaneKeepAssiDeactvn
    connect CalRegn02Cmn.FordCmdArbnLaneKeepAssiDeniedActvnReq -> FordCmdArbn.FordCmdArbnLaneKeepAssiDeniedActvnReq
    connect CalRegn02Cmn.FordCmdArbnLatCtrlDeactvn -> FordCmdArbn.FordCmdArbnLatCtrlDeactvn
    connect CalRegn02Cmn.FordCmdArbnLatCtrlDeniedActvnReq -> FordCmdArbn.FordCmdArbnLatCtrlDeniedActvnReq
    connect CalRegn02Cmn.FordCmdArbnNonStMask -> FordCmdArbn.FordCmdArbnNonStMask
    connect CalRegn02Cmn.FordCmdArbnNormAssiTqThd -> FordCmdArbn.FordCmdArbnNormAssiTqThd
    connect CalRegn02Cmn.FordCmdArbnPullDriftCmpDeactvn -> FordCmdArbn.FordCmdArbnPullDriftCmpDeactvn
    connect CalRegn02Cmn.FordCmdArbnPullDriftCmpDeniedActvnReq -> FordCmdArbn.FordCmdArbnPullDriftCmpDeniedActvnReq
    connect CalRegn02Cmn.FordCmdArbnPullDriftCmpLrngDeactvn -> FordCmdArbn.FordCmdArbnPullDriftCmpLrngDeactvn
    connect CalRegn02Cmn.FordCmdArbnPullDriftCmpLrngDeniedActvnReq -> FordCmdArbn.FordCmdArbnPullDriftCmpLrngDeniedActvnReq
    connect CalRegn02Cmn.FordCmdArbnSpare1Deactvn -> FordCmdArbn.FordCmdArbnSpare1Deactvn
    connect CalRegn02Cmn.FordCmdArbnSpare1DeniedActvnReq -> FordCmdArbn.FordCmdArbnSpare1DeniedActvnReq
    connect CalRegn02Cmn.FordCmdArbnSpare2Deactvn -> FordCmdArbn.FordCmdArbnSpare2Deactvn
    connect CalRegn02Cmn.FordCmdArbnSpare2DeniedActvnReq -> FordCmdArbn.FordCmdArbnSpare2DeniedActvnReq
    connect CalRegn02Cmn.FordCmdArbnSpare3Deactvn -> FordCmdArbn.FordCmdArbnSpare3Deactvn
    connect CalRegn02Cmn.FordCmdArbnSpare3DeniedActvnReq -> FordCmdArbn.FordCmdArbnSpare3DeniedActvnReq
    connect CalRegn02Cmn.FordCmdArbnSteerDstbcDeactvn -> FordCmdArbn.FordCmdArbnSteerDstbcDeactvn
    connect CalRegn02Cmn.FordCmdArbnSteerDstbcDeniedActvnReq -> FordCmdArbn.FordCmdArbnSteerDstbcDeniedActvnReq
    connect CalRegn02Cmn.FordHwAgArbnMotVelVldFlgRcvrTiThd -> FordHwAgArbn.FordHwAgArbnMotVelVldFlgRcvrTiThd
    connect CalRegn02Cmn.FordHwAgArbnNonAbsCentrNotDetdTiThd -> FordHwAgArbn.FordHwAgArbnNonAbsCentrNotDetdTiThd
    connect CalRegn02Cmn.FordHwAgArbnPhyRackTrvlThd -> FordHwAgArbn.FordHwAgArbnPhyRackTrvlThd
    connect CalRegn02Cmn.FordHwAgArbnRelPosnVldFlgRcvryTiThd -> FordHwAgArbn.FordHwAgArbnRelPosnVldFlgRcvryTiThd
    connect CalRegn02Cmn.FordHwTqCdngAppldFinalMotTqVldTiThd -> FordHwTqCdng.FordHwTqCdngAppldFinalMotTqVldTiThd
    connect CalRegn02Cmn.FordHwTqCdngInpTqRawVldTiThd -> FordHwTqCdng.FordHwTqCdngInpTqRawVldTiThd
    connect CalRegn02Cmn.FordHwTqCmdOvrlLimrCombdBwY -> FordHwTqCmdOvrlLimr.FordHwTqCmdOvrlLimrCombdBwY
    connect CalRegn02Cmn.FordHwTqCmdOvrlLimrCombdTqRateY -> FordHwTqCmdOvrlLimr.FordHwTqCmdOvrlLimrCombdTqRateY
    connect CalRegn02Cmn.FordHwTqCmdOvrlLimrCombdTqSatnY -> FordHwTqCmdOvrlLimr.FordHwTqCmdOvrlLimrCombdTqSatnY
    connect CalRegn02Cmn.FordHwTqCmdOvrlLimrCombdVehSpdBreakPtX -> FordHwTqCmdOvrlLimr.FordHwTqCmdOvrlLimrCombdVehSpdBreakPtX
    connect CalRegn02Cmn.FordHwTqCmdOvrlLimrDftSpdRate -> FordHwTqCmdOvrlLimr.FordHwTqCmdOvrlLimrDftSpdRate
    connect CalRegn02Cmn.FordHwTqCmdOvrlLimrDftSpdRcvrRate -> FordHwTqCmdOvrlLimr.FordHwTqCmdOvrlLimrDftSpdRcvrRate
    connect CalRegn02Cmn.FordHwTqCmdOvrlLimrLkaBwY -> FordHwTqCmdOvrlLimr.FordHwTqCmdOvrlLimrLkaBwY
    connect CalRegn02Cmn.FordHwTqCmdOvrlLimrLkaTqRateY -> FordHwTqCmdOvrlLimr.FordHwTqCmdOvrlLimrLkaTqRateY
    connect CalRegn02Cmn.FordHwTqCmdOvrlLimrLkaTqSatnY -> FordHwTqCmdOvrlLimr.FordHwTqCmdOvrlLimrLkaTqSatnY
    connect CalRegn02Cmn.FordHwTqCmdOvrlLimrVehSpdBreakPtX -> FordHwTqCmdOvrlLimr.FordHwTqCmdOvrlLimrVehSpdBreakPtX
    connect CalRegn02Cmn.FordMotTqCmdOvrlLimrDftSpdRate -> FordMotTqCmdOvrlLimr.FordMotTqCmdOvrlLimrDftSpdRate
    connect CalRegn02Cmn.FordMotTqCmdOvrlLimrDftSpdRcvrRate -> FordMotTqCmdOvrlLimr.FordMotTqCmdOvrlLimrDftSpdRcvrRate
    connect CalRegn02Cmn.FordMotTqCmdOvrlLimrHiFrqMonrActvNiblCtrlDcTqTrendThd -> FordMotTqCmdOvrlLimr.FordMotTqCmdOvrlLimrHiFrqMonrActvNiblCtrlDcTqTrendThd
    connect CalRegn02Cmn.FordMotTqCmdOvrlLimrHiFrqMonrActvNiblCtrlLoFrqTiThd -> FordMotTqCmdOvrlLimr.FordMotTqCmdOvrlLimrHiFrqMonrActvNiblCtrlLoFrqTiThd
    connect CalRegn02Cmn.FordMotTqCmdOvrlLimrHiFrqMonrActvNiblCtrlMaxMotTq -> FordMotTqCmdOvrlLimr.FordMotTqCmdOvrlLimrHiFrqMonrActvNiblCtrlMaxMotTq
    connect CalRegn02Cmn.FordMotTqCmdOvrlLimrHiFrqMonrLaneDprtrWarnDcTqTrendThd -> FordMotTqCmdOvrlLimr.FordMotTqCmdOvrlLimrHiFrqMonrLaneDprtrWarnDcTqTrendThd
    connect CalRegn02Cmn.FordMotTqCmdOvrlLimrHiFrqMonrLaneDprtrWarnLoFrqTiThd -> FordMotTqCmdOvrlLimr.FordMotTqCmdOvrlLimrHiFrqMonrLaneDprtrWarnLoFrqTiThd
    connect CalRegn02Cmn.FordMotTqCmdOvrlLimrHiFrqMonrLaneDprtrWarnMaxMotTq -> FordMotTqCmdOvrlLimr.FordMotTqCmdOvrlLimrHiFrqMonrLaneDprtrWarnMaxMotTq
    connect CalRegn02Cmn.FordMotTqCmdOvrlLimrHiFrqMonrTqTrendAlpha -> FordMotTqCmdOvrlLimr.FordMotTqCmdOvrlLimrHiFrqMonrTqTrendAlpha
    connect CalRegn02Cmn.FordMotTqCmdOvrlLimrHiFrqMonrZeroBandTq -> FordMotTqCmdOvrlLimr.FordMotTqCmdOvrlLimrHiFrqMonrZeroBandTq
    connect CalRegn02Cmn.FordMotTqCmdOvrlLimrHwVelLoPassFrq -> FordMotTqCmdOvrlLimr.FordMotTqCmdOvrlLimrHwVelLoPassFrq
    connect CalRegn02Cmn.FordMotTqCmdOvrlLimrLatCtrlBwY -> FordMotTqCmdOvrlLimr.FordMotTqCmdOvrlLimrLatCtrlBwY
    connect CalRegn02Cmn.FordMotTqCmdOvrlLimrLatCtrlTqRateY -> FordMotTqCmdOvrlLimr.FordMotTqCmdOvrlLimrLatCtrlTqRateY
    connect CalRegn02Cmn.FordMotTqCmdOvrlLimrLatCtrlTqSatnY -> FordMotTqCmdOvrlLimr.FordMotTqCmdOvrlLimrLatCtrlTqSatnY
    connect CalRegn02Cmn.FordMotTqCmdOvrlLimrLatCtrlVehSpdBreakPtX -> FordMotTqCmdOvrlLimr.FordMotTqCmdOvrlLimrLatCtrlVehSpdBreakPtX
    connect CalRegn02Cmn.FordMotTqCmdOvrlLimrPullDriftCmpTqRateY -> FordMotTqCmdOvrlLimr.FordMotTqCmdOvrlLimrPullDriftCmpTqRateY
    connect CalRegn02Cmn.FordMotTqCmdOvrlLimrPullDriftCmpTqSatnY -> FordMotTqCmdOvrlLimr.FordMotTqCmdOvrlLimrPullDriftCmpTqSatnY
    connect CalRegn02Cmn.FordMotTqCmdOvrlLimrPullDriftCmpVehSpdBreakPtX -> FordMotTqCmdOvrlLimr.FordMotTqCmdOvrlLimrPullDriftCmpVehSpdBreakPtX
    connect CalRegn02Cmn.FordMotTqCmdOvrlLimrSteerReactnLimrCombAmpVehSpdLimX -> FordMotTqCmdOvrlLimr.FordMotTqCmdOvrlLimrSteerReactnLimrCombAmpVehSpdLimX
    connect CalRegn02Cmn.FordMotTqCmdOvrlLimrSteerReactnLimrCombAmpVehSpdLimY -> FordMotTqCmdOvrlLimr.FordMotTqCmdOvrlLimrSteerReactnLimrCombAmpVehSpdLimY
    connect CalRegn02Cmn.FordMotTqCmdOvrlLimrSteerReactnLimrCombdAmpOvrrun -> FordMotTqCmdOvrlLimr.FordMotTqCmdOvrlLimrSteerReactnLimrCombdAmpOvrrun
    connect CalRegn02Cmn.FordMotTqCmdOvrlLimrSteerReactnLimrCombdAmpRcvry -> FordMotTqCmdOvrlLimr.FordMotTqCmdOvrlLimrSteerReactnLimrCombdAmpRcvry
    connect CalRegn02Cmn.FordMotTqCmdOvrlLimrSteerReactnLimrCombdFixdOvrrunRampRate -> FordMotTqCmdOvrlLimr.FordMotTqCmdOvrlLimrSteerReactnLimrCombdFixdOvrrunRampRate
    connect CalRegn02Cmn.FordMotTqCmdOvrlLimrSteerReactnLimrCombdLimHys -> FordMotTqCmdOvrlLimr.FordMotTqCmdOvrlLimrSteerReactnLimrCombdLimHys
    connect CalRegn02Cmn.FordMotTqCmdOvrlLimrSteerReactnLimrCombdLimrHwVelY -> FordMotTqCmdOvrlLimr.FordMotTqCmdOvrlLimrSteerReactnLimrCombdLimrHwVelY
    connect CalRegn02Cmn.FordMotTqCmdOvrlLimrSteerReactnLimrCombdLimrVehSpd -> FordMotTqCmdOvrlLimr.FordMotTqCmdOvrlLimrSteerReactnLimrCombdLimrVehSpd
    connect CalRegn02Cmn.FordMotTqCmdOvrlLimrSteerReactnLimrCombdLimTqX -> FordMotTqCmdOvrlLimr.FordMotTqCmdOvrlLimrSteerReactnLimrCombdLimTqX
    connect CalRegn02Cmn.FordMotTqCmdOvrlLimrSteerReactnLimrCombdRcvryIdealRampRate -> FordMotTqCmdOvrlLimr.FordMotTqCmdOvrlLimrSteerReactnLimrCombdRcvryIdealRampRate
    connect CalRegn02Cmn.FordMotTqCmdOvrlLimrSteerReactnLimrCombdRcvryRampRateStg1 -> FordMotTqCmdOvrlLimr.FordMotTqCmdOvrlLimrSteerReactnLimrCombdRcvryRampRateStg1
    connect CalRegn02Cmn.FordMotTqCmdOvrlLimrSteerReactnLimrCombdRcvryRampRateStg2 -> FordMotTqCmdOvrlLimr.FordMotTqCmdOvrlLimrSteerReactnLimrCombdRcvryRampRateStg2
    connect CalRegn02Cmn.FordMotTqCmdOvrlLimrSteerReactnLimrCombOvrrunRampRateHwVelErrX -> FordMotTqCmdOvrlLimr.FordMotTqCmdOvrlLimrSteerReactnLimrCombOvrrunRampRateHwVelErrX
    connect CalRegn02Cmn.FordMotTqCmdOvrlLimrSteerReactnLimrCombOvrrunRampRateOutY -> FordMotTqCmdOvrlLimr.FordMotTqCmdOvrlLimrSteerReactnLimrCombOvrrunRampRateOutY
    connect CalRegn02Cmn.FullAssiRampUpRate -> FordSysSt.FullAssiRampUpRate
    connect CalRegn02Cmn.InitLimpHomeRamp -> FordSysSt.InitLimpHomeRamp
    connect CalRegn02Cmn.InitLimpHomeScar -> FordSysSt.InitLimpHomeScar
    connect CalRegn02Cmn.LimdAssiRamp -> FordSysSt.LimdAssiRamp
    connect CalRegn02Cmn.LimdAssiRampUpRate -> FordSysSt.LimdAssiRampUpRate
    connect CalRegn02Cmn.LimdAssiRampUpRateFaild -> FordSysSt.LimdAssiRampUpRateFaild
    connect CalRegn02Cmn.LimdAssiScar -> FordSysSt.LimdAssiScar
    connect CalRegn02Cmn.NormLimpHomeRamp -> FordSysSt.NormLimpHomeRamp
    connect CalRegn02Cmn.NormLimpHomeScar -> FordSysSt.NormLimpHomeScar
    connect CalRegn02Cmn.ShtdwnRamp -> FordSysSt.ShtdwnRamp
    connect CalRegn02Cmn.FordVehSpdArbnDrvnWhl -> FordVehSpdArbn.FordVehSpdArbnDrvnWhl
    connect CalRegn02Cmn.FordVehSpdArbnTireCircumMax -> FordVehSpdArbn.FordVehSpdArbnTireCircumMax
    connect CalRegn02Cmn.FordVehSpdArbnTireCircumMin -> FordVehSpdArbn.FordVehSpdArbnTireCircumMin
    connect CalRegn02Cmn.FordVltgIfActvParkAssiAsscTqMin -> FordVltgIf.FordVltgIfActvParkAssiAsscTqMin
    connect CalRegn02Cmn.FordVltgIfEpsBattCurrLim -> FordVltgIf.FordVltgIfEpsBattCurrLim
    connect CalRegn02Cmn.FordVltgIfEPSBattVltgDifThd -> FordVltgIf.FordVltgIfEPSBattVltgDifThd
    connect CalRegn02Cmn.FordVltgIfEpsCurrLim -> FordVltgIf.FordVltgIfEpsCurrLim
    connect CalRegn02Cmn.FordVltgIfEvasSteerAssiTqMin -> FordVltgIf.FordVltgIfEvasSteerAssiTqMin
    connect CalRegn02Cmn.FordVltgIfFeatThdStsTiThd -> FordVltgIf.FordVltgIfFeatThdStsTiThd
    connect CalRegn02Cmn.FordVltgIfHiVltgAssiRampDwnRate -> FordVltgIf.FordVltgIfHiVltgAssiRampDwnRate
    connect CalRegn02Cmn.FordVltgIfHiVltgAssiRampUpRate -> FordVltgIf.FordVltgIfHiVltgAssiRampUpRate
    connect CalRegn02Cmn.FordVltgIfHiVltgInhbTiMax -> FordVltgIf.FordVltgIfHiVltgInhbTiMax
    connect CalRegn02Cmn.FordVltgIfHiVltgNoAssiRampDwnRate -> FordVltgIf.FordVltgIfHiVltgNoAssiRampDwnRate
    connect CalRegn02Cmn.FordVltgIfHiVltgNoAssiRcvrTiMax -> FordVltgIf.FordVltgIfHiVltgNoAssiRcvrTiMax
    connect CalRegn02Cmn.FordVltgIfHiVltgRcvrTiMax -> FordVltgIf.FordVltgIfHiVltgRcvrTiMax
    connect CalRegn02Cmn.FordVltgIfHiVltgThdHi -> FordVltgIf.FordVltgIfHiVltgThdHi
    connect CalRegn02Cmn.FordVltgIfHiVltgThdLo -> FordVltgIf.FordVltgIfHiVltgThdLo
    connect CalRegn02Cmn.FordVltgIfInhbBattVltgDiagcTiThd -> FordVltgIf.FordVltgIfInhbBattVltgDiagcTiThd
    connect CalRegn02Cmn.FordVltgIfLaneCentrAssiTqMin -> FordVltgIf.FordVltgIfLaneCentrAssiTqMin
    connect CalRegn02Cmn.FordVltgIfLaneDprtrWarnAsscTqMin -> FordVltgIf.FordVltgIfLaneDprtrWarnAsscTqMin
    connect CalRegn02Cmn.FordVltgIfLkaAsscTqMin -> FordVltgIf.FordVltgIfLkaAsscTqMin
    connect CalRegn02Cmn.FordVltgIfLoVltgAssiRampDwnRate -> FordVltgIf.FordVltgIfLoVltgAssiRampDwnRate
    connect CalRegn02Cmn.FordVltgIfLoVltgAssiRampUpRate -> FordVltgIf.FordVltgIfLoVltgAssiRampUpRate
    connect CalRegn02Cmn.FordVltgIfLoVltgAssiScar -> FordVltgIf.FordVltgIfLoVltgAssiScar
    connect CalRegn02Cmn.FordVltgIfLoVltgInhbTiMax -> FordVltgIf.FordVltgIfLoVltgInhbTiMax
    connect CalRegn02Cmn.FordVltgIfLoVltgNoAssiRampDwnRate -> FordVltgIf.FordVltgIfLoVltgNoAssiRampDwnRate
    connect CalRegn02Cmn.FordVltgIfLoVltgNoAssiRcvrTiMax -> FordVltgIf.FordVltgIfLoVltgNoAssiRcvrTiMax
    connect CalRegn02Cmn.FordVltgIfLoVltgRcvrTiMax -> FordVltgIf.FordVltgIfLoVltgRcvrTiMax
    connect CalRegn02Cmn.FordVltgIfLoVltgThdHi -> FordVltgIf.FordVltgIfLoVltgThdHi
    connect CalRegn02Cmn.FordVltgIfLoVltgThdLo -> FordVltgIf.FordVltgIfLoVltgThdLo
    connect CalRegn02Cmn.FordVltgIfLoVltgThdMid -> FordVltgIf.FordVltgIfLoVltgThdMid
    connect CalRegn02Cmn.FordVltgIfLoVltgThdMidToLoTiMax -> FordVltgIf.FordVltgIfLoVltgThdMidToLoTiMax
    connect CalRegn02Cmn.FordVltgIfLoVltgTqScaDwnRate -> FordVltgIf.FordVltgIfLoVltgTqScaDwnRate
    connect CalRegn02Cmn.FordVltgIfLoVltgTqScagFac -> FordVltgIf.FordVltgIfLoVltgTqScagFac
    connect CalRegn02Cmn.FordVltgIfLoVltgTqScaUpRate -> FordVltgIf.FordVltgIfLoVltgTqScaUpRate
    connect CalRegn02Cmn.FordVltgIfTrfcJamAsscTqMin -> FordVltgIf.FordVltgIfTrfcJamAsscTqMin
    connect CalRegn02Cmn.FordVltgIfTrlrBackupAssiTqMin -> FordVltgIf.FordVltgIfTrlrBackupAssiTqMin
    connect CalRegn02Cmn.FordVltgIfVehBattCircR -> FordVltgIf.FordVltgIfVehBattCircR
    connect CalRegn02Cmn.LoaMgrCurrIvtrMtgtnRate -> LoaMgr.LoaMgrCurrIvtrMtgtnRate
    connect CalRegn02Cmn.LoaMgrCurrIvtrMtgtnSca -> LoaMgr.LoaMgrCurrIvtrMtgtnSca
    connect CalRegn02Cmn.LoaMgrCurrMeasMtgtnRate -> LoaMgr.LoaMgrCurrMeasMtgtnRate
    connect CalRegn02Cmn.LoaMgrCurrMeasMtgtnSca -> LoaMgr.LoaMgrCurrMeasMtgtnSca
    connect CalRegn02Cmn.LoaMgrIvtrMtgtnRate -> LoaMgr.LoaMgrIvtrMtgtnRate
    connect CalRegn02Cmn.LoaMgrIvtrMtgtnSca -> LoaMgr.LoaMgrIvtrMtgtnSca
    connect CalRegn02Cmn.LoaMgrLimdStRate -> LoaMgr.LoaMgrLimdStRate
    connect CalRegn02Cmn.LoaMgrLimdStSca -> LoaMgr.LoaMgrLimdStSca
    connect CalRegn02Cmn.LoaMgrMotAgMtgtnRate -> LoaMgr.LoaMgrMotAgMtgtnRate
    connect CalRegn02Cmn.LoaMgrMotAgMtgtnSca -> LoaMgr.LoaMgrMotAgMtgtnSca
    connect CalRegn02Cmn.MotRplCoggCfgMotAgTiDly -> MotRplCoggCfg.MotRplCoggCfgMotAgTiDly
    connect CalRegn02Cmn.MotRplCoggCfgMotCurrDaxRplBilnrSeln -> MotRplCoggCfg.MotRplCoggCfgMotCurrDaxRplBilnrSeln
    connect CalRegn02Cmn.MotRplCoggCfgMotCurrQaxRpl -> MotRplCoggCfg.MotRplCoggCfgMotCurrQaxRpl
    connect CalRegn02Cmn.MotRplCoggCfgMotTqCmdCurrRgltrBwCmpMgnY -> MotRplCoggCfg.MotRplCoggCfgMotTqCmdCurrRgltrBwCmpMgnY
    connect CalRegn02Cmn.MotRplCoggCfgMotTqCmdCurrRgltrBwCmpPhaY -> MotRplCoggCfg.MotRplCoggCfgMotTqCmdCurrRgltrBwCmpPhaY
    connect CalRegn02Cmn.MotRplCoggCfgMotTqCmdCurrRgltrBwCmpX -> MotRplCoggCfg.MotRplCoggCfgMotTqCmdCurrRgltrBwCmpX
    connect CalRegn02Cmn.MotRplCoggCfgMotTqRplOrder1X -> MotRplCoggCfg.MotRplCoggCfgMotTqRplOrder1X
    connect CalRegn02Cmn.MotRplCoggCfgMotTqRplOrder1Y -> MotRplCoggCfg.MotRplCoggCfgMotTqRplOrder1Y
    connect CalRegn02Cmn.MotRplCoggCfgMotTqRplOrder2X -> MotRplCoggCfg.MotRplCoggCfgMotTqRplOrder2X
    connect CalRegn02Cmn.MotRplCoggCfgMotTqRplOrder2Y -> MotRplCoggCfg.MotRplCoggCfgMotTqRplOrder2Y
    connect CalRegn02Cmn.MotRplCoggCfgMotTqRplOrder3X -> MotRplCoggCfg.MotRplCoggCfgMotTqRplOrder3X
    connect CalRegn02Cmn.MotRplCoggCfgMotTqRplOrder3Y -> MotRplCoggCfg.MotRplCoggCfgMotTqRplOrder3Y
    connect CalRegn02Cmn.MotRplCoggCfgMotVelBilnrSeln -> MotRplCoggCfg.MotRplCoggCfgMotVelBilnrSeln
    connect CalRegn02Cmn.MotRplCoggCmdHrmncOrder{1..3}Elec -> MotRplCoggCfg.MotRplCoggCmdHrmncOrder{1..3}Elec
    connect CalRegn02Cmn.NxtrCalIdsCal1DevlpAuthor -> NxtrCalIds.NxtrCalIdsCal1DevlpAuthor
    connect CalRegn02Cmn.NxtrCalIdsCal1DevlpRelNr -> NxtrCalIds.NxtrCalIdsCal1DevlpRelNr
    connect CalRegn02Cmn.NxtrCalIdsCal1DevlpRelSt -> NxtrCalIds.NxtrCalIdsCal1DevlpRelSt
    connect CalRegn02Cmn.NxtrCalIdsCal1DevlpTiStamp -> NxtrCalIds.NxtrCalIdsCal1DevlpTiStamp
    connect CalRegn02Cmn.NxtrCalIdsCal1DevlpVers -> NxtrCalIds.NxtrCalIdsCal1DevlpVers
    connect CalRegn02CmnGroupA.AssiThermScaX -> Assi.AssiThermScaX
    connect CalRegn02CmnGroupA.AssiThermScaY -> Assi.AssiThermScaY
    connect CalRegn02CmnGroupB.EotLrngHwAgOverTrvlCntThd -> EotLrng.EotLrngHwAgOverTrvlCntThd
    connect CalRegn02CmnGroupB.EotProtnActvRegnBypMaxThd -> EotProtn.EotProtnActvRegnBypMaxThd
    connect CalRegn02CmnGroupB.EotProtnFwlEotDampgActvBndX -> EotProtnFwl.EotProtnFwlEotDampgActvBndX
    connect CalRegn02CmnGroupB.EotProtnFwlInactvLim -> EotProtnFwl.EotProtnFwlInactvLim
    connect CalRegn02CmnGroupB.EotProtnFwlVehSpd -> EotProtnFwl.EotProtnFwlVehSpd
    connect CalRegn02Inin00.SysGlbPrmSysKineRat -> CDD_FordBlaBoxIfCmp1.SysGlbPrmSysKineRat
    connect CalRegn02Inin00.SysGlbPrmSysKineRat -> CDD_MotAgCmp.SysGlbPrmSysKineRat
    connect CalRegn02Inin00.SysGlbPrmSysKineRat -> DrvrTqEstimn.SysGlbPrmSysKineRat
    connect CalRegn02Inin00.SysGlbPrmSysKineRat -> FordHwAgArbn.SysGlbPrmSysKineRat
    connect CalRegn02Inin00.SysGlbPrmSysKineRat -> FordHwTqCdng.SysGlbPrmSysKineRat
    connect CalRegn02Inin00.HiLoadStallLimrMotTqCmdFetMtgtnEnaFilFrq -> HiLoadStallLimr.HiLoadStallLimrMotTqCmdFetMtgtnEnaFilFrq
    connect CalRegn02Inin00.HiLoadStallLimrMotTqCmdFilFrq -> HiLoadStallLimr.HiLoadStallLimrMotTqCmdFilFrq
    connect CalRegn02Inin00.HiLoadStallLimrMotVelMgnThd -> HiLoadStallLimr.HiLoadStallLimrMotVelMgnThd
    connect CalRegn02Inin00.HiLoadStallLimrStallMotTqCmdFetMtgtnLimX -> HiLoadStallLimr.HiLoadStallLimrStallMotTqCmdFetMtgtnLimX
    connect CalRegn02Inin00.HiLoadStallLimrStallMotTqCmdFetMtgtnLimY -> HiLoadStallLimr.HiLoadStallLimrStallMotTqCmdFetMtgtnLimY
    connect CalRegn02Inin00.HiLoadStallLimrStallMotTqCmdLimX -> HiLoadStallLimr.HiLoadStallLimrStallMotTqCmdLimX
    connect CalRegn02Inin00.HiLoadStallLimrStallMotTqCmdLimY -> HiLoadStallLimr.HiLoadStallLimrStallMotTqCmdLimY
    connect CalRegn02Inin00.HiLoadStallLimrStallMotTqLimSlewRate -> HiLoadStallLimr.HiLoadStallLimrStallMotTqLimSlewRate
    connect CalRegn02Inin00.HiLoadStallLimrStallThermLimSca -> HiLoadStallLimr.HiLoadStallLimrStallThermLimSca
    connect CalRegn02Inin00.SysGlbPrmSysKineRat -> HwAgSnsrls.SysGlbPrmSysKineRat
    connect CalRegn02Inin00.SysGlbPrmSysKineRat -> HwAgSysArbn.SysGlbPrmSysKineRat
    connect CalRegn02Inin00.SysGlbPrmSysKineRat -> InertiaCmpVel.SysGlbPrmSysKineRat
    connect CalRegn02Inin00.SysGlbPrmSysKineRat -> PosnTrakgServo.SysGlbPrmSysKineRat
    connect CalRegn02Inin00.VehSigCdngVehSpdSlewRate -> VehSigCdng.VehSigCdngVehSpdSlewRate
    connect CalRegn02Inin00GroupA.AssiHiFrqHpFilFrq -> AssiHiFrq.AssiHiFrqHpFilFrq
    connect CalRegn02Inin00GroupA.DampgHydAssiLim -> Dampg.DampgHydAssiLim
    connect CalRegn02Inin00GroupA.HysCmpAssiCmdLpFilFrq -> HysCmp.HysCmpAssiCmdLpFilFrq
    connect CalRegn02Inin00GroupA.HysCmpAssiInpLim -> HysCmp.HysCmpAssiInpLim
    connect CalRegn02Inin00GroupA.HysCmpFinalOutpLpFilFrq -> HysCmp.HysCmpFinalOutpLpFilFrq
    connect CalRegn02Inin00GroupA.HysCmpFricTScaX -> HysCmp.HysCmpFricTScaX
    connect CalRegn02Inin00GroupA.HysCmpFricTScaY -> HysCmp.HysCmpFricTScaY
    connect CalRegn02Inin00GroupA.HysCmpHwTqLpFilFrq -> HysCmp.HysCmpHwTqLpFilFrq
    connect CalRegn02Inin00GroupA.InertiaCmpVelAssiBasdDampgCoeffX -> InertiaCmpVel.InertiaCmpVelAssiBasdDampgCoeffX
    connect CalRegn02Inin00GroupA.InertiaCmpVelAssiBasdDampgRollgWhlImbRejctnOnY -> InertiaCmpVel.InertiaCmpVelAssiBasdDampgRollgWhlImbRejctnOnY
    connect CalRegn02Inin00GroupA.InertiaCmpVelAssiBasdDampgRollgY -> InertiaCmpVel.InertiaCmpVelAssiBasdDampgRollgY
    connect CalRegn02Inin00GroupA.InertiaCmpVelAssiBasdDampgStatWhlImbRejctnOnY -> InertiaCmpVel.InertiaCmpVelAssiBasdDampgStatWhlImbRejctnOnY
    connect CalRegn02Inin00GroupA.InertiaCmpVelCmdScaY -> InertiaCmpVel.InertiaCmpVelCmdScaY
    connect CalRegn02Inin00GroupA.InertiaCmpVelDampgDecelGain -> InertiaCmpVel.InertiaCmpVelDampgDecelGain
    connect CalRegn02Inin00GroupA.InertiaCmpVelDampgDecelGainFallSlew -> InertiaCmpVel.InertiaCmpVelDampgDecelGainFallSlew
    connect CalRegn02Inin00GroupA.InertiaCmpVelDampgDecelGainRisngSlewX -> InertiaCmpVel.InertiaCmpVelDampgDecelGainRisngSlewX
    connect CalRegn02Inin00GroupA.InertiaCmpVelDampgDecelGainRisngSlewY -> InertiaCmpVel.InertiaCmpVelDampgDecelGainRisngSlewY
    connect CalRegn02Inin00GroupA.InertiaCmpVelDampgGainOffThd -> InertiaCmpVel.InertiaCmpVelDampgGainOffThd
    connect CalRegn02Inin00GroupA.InertiaCmpVelDampgGainOnThd -> InertiaCmpVel.InertiaCmpVelDampgGainOnThd
    connect CalRegn02Inin00GroupA.InertiaCmpVelDecelGainEnaCal -> InertiaCmpVel.InertiaCmpVelDecelGainEnaCal
    connect CalRegn02Inin00GroupA.InertiaCmpVelModWhlImbRejctnBlndX -> InertiaCmpVel.InertiaCmpVelModWhlImbRejctnBlndX
    connect CalRegn02Inin00GroupA.InertiaCmpVelModWhlImbRejctnBlndY -> InertiaCmpVel.InertiaCmpVelModWhlImbRejctnBlndY
    connect CalRegn02Inin00GroupA.InertiaCmpVelMotInertia -> InertiaCmpVel.InertiaCmpVelMotInertia
    connect CalRegn02Inin00GroupA.InertiaCmpVelMotVelBasdOutpScagX -> InertiaCmpVel.InertiaCmpVelMotVelBasdOutpScagX
    connect CalRegn02Inin00GroupA.InertiaCmpVelMotVelBasdOutpScagY -> InertiaCmpVel.InertiaCmpVelMotVelBasdOutpScagY
    connect CalRegn02Inin00GroupA.InertiaCmpVelNotchBlndY -> InertiaCmpVel.InertiaCmpVelNotchBlndY
    connect CalRegn02Inin00GroupA.InertiaCmpVelNotchFilStruct -> InertiaCmpVel.InertiaCmpVelNotchFilStruct
    connect CalRegn02Inin00GroupA.InertiaCmpVelTqSnsrVelFilFrq -> InertiaCmpVel.InertiaCmpVelTqSnsrVelFilFrq
    connect CalRegn02Inin00GroupA.InertiaCmpVelTqSnsrVelSca -> InertiaCmpVel.InertiaCmpVelTqSnsrVelSca
    connect CalRegn02Inin00GroupB.EotLrngAuthyStrtLrn -> EotLrng.EotLrngAuthyStrtLrn
    connect CalRegn02Inin00GroupB.EotLrngEntrAndExitHysRngLimr -> EotLrng.EotLrngEntrAndExitHysRngLimr
    connect CalRegn02Inin00GroupB.EotLrngEotLrnTmr -> EotLrng.EotLrngEotLrnTmr
    connect CalRegn02Inin00GroupB.EotLrngHwTqEotLrn -> EotLrng.EotLrngHwTqEotLrn
    connect CalRegn02Inin00GroupB.EotLrngMotVelEotLrn -> EotLrng.EotLrngMotVelEotLrn
    connect CalRegn02Inin00GroupB.EotLrngRackTrvlMax -> EotLrng.EotLrngRackTrvlMax
    connect CalRegn02Inin00GroupB.EotLrngRackTrvlMin -> EotLrng.EotLrngRackTrvlMin
    connect CalRegn02Inin00GroupB.EotLrngRstAuthyMin -> EotLrng.EotLrngRstAuthyMin
    connect CalRegn02Inin00GroupB.EotProtnRackTrvlLimrEna -> EotLrng.EotProtnRackTrvlLimrEna
    connect CalRegn02Inin00GroupB.EotProtnRackTrvlLimrRngLimd -> EotLrng.EotProtnRackTrvlLimrRngLimd
    connect CalRegn02Inin00GroupB.EotProtnDampgSlew -> EotProtn.EotProtnDampgSlew
    connect CalRegn02Inin00GroupB.EotProtnDftPosn -> EotProtn.EotProtnDftPosn
    connect CalRegn02Inin00GroupB.EotProtnEntrGainAuthyThd -> EotProtn.EotProtnEntrGainAuthyThd
    connect CalRegn02Inin00GroupB.EotProtnEntrGainX -> EotProtn.EotProtnEntrGainX
    connect CalRegn02Inin00GroupB.EotProtnEntrStLpFilFrq -> EotProtn.EotProtnEntrStLpFilFrq
    connect CalRegn02Inin00GroupB.EotProtnExitDampgY -> EotProtn.EotProtnExitDampgY
    connect CalRegn02Inin00GroupB.EotProtnExitStLpFilFrq -> EotProtn.EotProtnExitStLpFilFrq
    connect CalRegn02Inin00GroupB.EotProtnHwAgGain -> EotProtn.EotProtnHwAgGain
    connect CalRegn02Inin00GroupB.EotProtnHwAgMax -> EotProtn.EotProtnHwAgMax
    connect CalRegn02Inin00GroupB.EotProtnHwAgMin -> EotProtn.EotProtnHwAgMin
    connect CalRegn02Inin00GroupB.EotProtnHwDegDampgX -> EotProtn.EotProtnHwDegDampgX
    connect CalRegn02Inin00GroupB.EotProtnHwTqLpFilFrq -> EotProtn.EotProtnHwTqLpFilFrq
    connect CalRegn02Inin00GroupB.EotProtnHwTqScaX -> EotProtn.EotProtnHwTqScaX
    connect CalRegn02Inin00GroupB.EotProtnMotSpdIncptSca -> EotProtn.EotProtnMotSpdIncptSca
    connect CalRegn02Inin00GroupB.EotProtnMotSpdIncptX -> EotProtn.EotProtnMotSpdIncptX
    connect CalRegn02Inin00GroupB.EotProtnMotVelGain -> EotProtn.EotProtnMotVelGain
    connect CalRegn02Inin00GroupB.EotProtnPosnRampStep -> EotProtn.EotProtnPosnRampStep
    connect CalRegn02Inin00GroupB.EotProtnRackTrvlLimrAuthyThd -> EotProtn.EotProtnRackTrvlLimrAuthyThd
    connect CalRegn02Inin00GroupB.EotProtnRackTrvlLimrAuthyThdLimd -> EotProtn.EotProtnRackTrvlLimrAuthyThdLimd
    connect CalRegn02Inin00GroupB.EotProtnRackTrvlLimrEna -> EotProtn.EotProtnRackTrvlLimrEna
    connect CalRegn02Inin00GroupB.EotProtnRackTrvlLimrRng -> EotProtn.EotProtnRackTrvlLimrRng
    connect CalRegn02Inin00GroupB.EotProtnRackTrvlLimrRngLimd -> EotProtn.EotProtnRackTrvlLimrRngLimd
    connect CalRegn02Inin00GroupB.EotProtnRackTrvlLimrVehSpdThd -> EotProtn.EotProtnRackTrvlLimrVehSpdThd
    connect CalRegn02Inin00GroupB.EotProtnRunEotVelImpctAndSoftEndStop -> EotProtn.EotProtnRunEotVelImpctAndSoftEndStop
    connect CalRegn02Inin00GroupB.EotProtnSoftEndStopEna -> EotProtn.EotProtnSoftEndStopEna
    connect CalRegn02Inin00GroupB.EotProtnSoftEndStopVehSpdThd -> EotProtn.EotProtnSoftEndStopVehSpdThd
    connect CalRegn02Inin00GroupB.EotProtnFwlActvCmdLowrBnd -> EotProtnFwl.EotProtnFwlActvCmdLowrBnd
    connect CalRegn02Inin00GroupB.EotProtnFwlActvCmdUpprBnd -> EotProtnFwl.EotProtnFwlActvCmdUpprBnd
    connect CalRegn02Inin00GroupB.EotProtnFwlEotDampgActvBndY -> EotProtnFwl.EotProtnFwlEotDampgActvBndY
    connect CalRegn02Inin00GroupB.EotProtnHwAgMin -> EotProtnFwl.EotProtnHwAgMin
    connect CalRegn02Inin00GroupB.EotProtnHwDegDampgX -> EotProtnFwl.EotProtnHwDegDampgX
    connect CalRegn02Inin00GroupB.EotProtnRackTrvlLimrRng -> EotProtnFwl.EotProtnRackTrvlLimrRng
    connect CalRegn02Inin00GroupB.RtnHwAuthyScaX -> Rtn.RtnHwAuthyScaX
    connect CalRegn02Inin00GroupB.RtnHwAuthyScaY -> Rtn.RtnHwAuthyScaY
    connect CalRegn02Inin00GroupB.RtnHwAuthySlew -> Rtn.RtnHwAuthySlew
    connect CalRegn02Inin00GroupB.RtnOffsRng -> Rtn.RtnOffsRng
    connect CalRegn02Inin00GroupB.RtnOffsSlew -> Rtn.RtnOffsSlew
    connect CalRegn02Inin00GroupB.RtnTScaX -> Rtn.RtnTScaX
    connect CalRegn02Inin00GroupB.RtnTScaY -> Rtn.RtnTScaY
    connect CalRegn02Inin00GroupB.RtnPahFwlUpprBndTblX -> RtnPahFwl.RtnPahFwlUpprBndTblX
    connect CalRegn02Inin00GroupB.RtnPahFwlUpprBndTblY -> RtnPahFwl.RtnPahFwlUpprBndTblY
    connect CalRegn02Inin00GroupB.RtnPahFwlVehSpd -> RtnPahFwl.RtnPahFwlVehSpd
    connect CalRegn02Rt00GroupA.AssiHiFrqGainY -> AAACalRegn02Rt00GroupA_Dummy.AssiHiFrqGainY
    connect CalRegn02Rt00GroupA.AssiHiFrqHpFilFrqY -> AAACalRegn02Rt00GroupA_Dummy.AssiHiFrqHpFilFrqY
    connect CalRegn02Rt00GroupA.AssiHiFrqTqWhlImbRejctnTqX -> AAACalRegn02Rt00GroupA_Dummy.AssiHiFrqTqWhlImbRejctnTqX
    connect CalRegn02Rt00GroupA.AssiHiFrqTqX -> AAACalRegn02Rt00GroupA_Dummy.AssiHiFrqTqX
    connect CalRegn02Rt00GroupA.AssiHiFrqWhlImbRejctnBlndX -> AAACalRegn02Rt00GroupA_Dummy.AssiHiFrqWhlImbRejctnBlndX
    connect CalRegn02Rt00GroupA.AssiHiFrqWhlImbRejctnBlndY -> AAACalRegn02Rt00GroupA_Dummy.AssiHiFrqWhlImbRejctnBlndY
    connect CalRegn02Rt00GroupA.AssiHiFrqWhlImbRejctnGainY -> AAACalRegn02Rt00GroupA_Dummy.AssiHiFrqWhlImbRejctnGainY
    connect CalRegn02Rt00GroupA.AssiMotTqWhlImbRejctnMaxX -> AAACalRegn02Rt00GroupA_Dummy.AssiMotTqWhlImbRejctnMaxX
    connect CalRegn02Rt00GroupA.AssiMotTqWhlImbRejctnMaxY -> AAACalRegn02Rt00GroupA_Dummy.AssiMotTqWhlImbRejctnMaxY
    connect CalRegn02Rt00GroupA.AssiMotTqWhlImbRejctnMinX -> AAACalRegn02Rt00GroupA_Dummy.AssiMotTqWhlImbRejctnMinX
    connect CalRegn02Rt00GroupA.AssiMotTqWhlImbRejctnMinY -> AAACalRegn02Rt00GroupA_Dummy.AssiMotTqWhlImbRejctnMinY
    connect CalRegn02Rt00GroupA.AssiWhlImbRejctnBlndScaX -> AAACalRegn02Rt00GroupA_Dummy.AssiWhlImbRejctnBlndScaX
    connect CalRegn02Rt00GroupA.AssiWhlImbRejctnBlndScaY -> AAACalRegn02Rt00GroupA_Dummy.AssiWhlImbRejctnBlndScaY
    connect CalRegn02Rt00GroupA.DampgHwTqX -> AAACalRegn02Rt00GroupA_Dummy.DampgHwTqX
    connect CalRegn02Rt00GroupA.DampgHwTqY -> AAACalRegn02Rt00GroupA_Dummy.DampgHwTqY
    connect CalRegn02Rt00GroupA.DampgHydCoeff{1..4}ScaY -> AAACalRegn02Rt00GroupA_Dummy.DampgHydCoeff{1..4}ScaY
    connect CalRegn02Rt00GroupA.DampgMotVelX -> AAACalRegn02Rt00GroupA_Dummy.DampgMotVelX
    connect CalRegn02Rt00GroupA.DampgMotVelY -> AAACalRegn02Rt00GroupA_Dummy.DampgMotVelY
    connect CalRegn02Rt00GroupA.HysCmpEffLossY -> AAACalRegn02Rt00GroupA_Dummy.HysCmpEffLossY
    connect CalRegn02Rt00GroupA.HysCmpEffOffsY -> AAACalRegn02Rt00GroupA_Dummy.HysCmpEffOffsY
    connect CalRegn02Rt00GroupA.HysCmpFricWhlImbRejctnBlndX -> AAACalRegn02Rt00GroupA_Dummy.HysCmpFricWhlImbRejctnBlndX
    connect CalRegn02Rt00GroupA.HysCmpFricWhlImbRejctnBlndY -> AAACalRegn02Rt00GroupA_Dummy.HysCmpFricWhlImbRejctnBlndY
    connect CalRegn02Rt00GroupA.HysCmpFricWhlImbRejctnOffY -> AAACalRegn02Rt00GroupA_Dummy.HysCmpFricWhlImbRejctnOffY
    connect CalRegn02Rt00GroupA.HysCmpFricWhlImbRejctnOnY -> AAACalRegn02Rt00GroupA_Dummy.HysCmpFricWhlImbRejctnOnY
    connect CalRegn02Rt00GroupA.HysCmpHwTqScaX -> AAACalRegn02Rt00GroupA_Dummy.HysCmpHwTqScaX
    connect CalRegn02Rt00GroupA.HysCmpHwTqScaY -> AAACalRegn02Rt00GroupA_Dummy.HysCmpHwTqScaY
    connect CalRegn02Rt00GroupA.HysCmpHysSatnY -> AAACalRegn02Rt00GroupA_Dummy.HysCmpHysSatnY
    connect CalRegn02Rt00GroupA.HysCmpNegHysCmpScaX -> AAACalRegn02Rt00GroupA_Dummy.HysCmpNegHysCmpScaX
    connect CalRegn02Rt00GroupA.HysCmpNegHysCmpScaY -> AAACalRegn02Rt00GroupA_Dummy.HysCmpNegHysCmpScaY
    connect CalRegn02Rt00GroupA.HysCmpNegHysCmpX -> AAACalRegn02Rt00GroupA_Dummy.HysCmpNegHysCmpX
    connect CalRegn02Rt00GroupA.HysCmpNegHysCmpY -> AAACalRegn02Rt00GroupA_Dummy.HysCmpNegHysCmpY
    connect CalRegn02Rt00GroupA.HysCmpOutpLim -> AAACalRegn02Rt00GroupA_Dummy.HysCmpOutpLim
    connect CalRegn02Rt00GroupA.HysCmpRevGain -> AAACalRegn02Rt00GroupA_Dummy.HysCmpRevGain
    connect CalRegn02Rt00GroupA.HysCmpRiseX -> AAACalRegn02Rt00GroupA_Dummy.HysCmpRiseX
    connect CalRegn02Rt00GroupA.HysCmpRiseY -> AAACalRegn02Rt00GroupA_Dummy.HysCmpRiseY
    connect CalRegn02Rt00GroupA.InertiaCmpVelAssiBasdDampgStatY -> AAACalRegn02Rt00GroupA_Dummy.InertiaCmpVelAssiBasdDampgStatY
    connect CalRegn02Rt00GroupA.InertiaCmpVelDampgFilFrq -> AAACalRegn02Rt00GroupA_Dummy.InertiaCmpVelDampgFilFrq
    connect CalRegn02Rt00GroupA.InertiaCmpVelDampgFilFrqWhlImbRejctnOn -> AAACalRegn02Rt00GroupA_Dummy.InertiaCmpVelDampgFilFrqWhlImbRejctnOn
    connect CalRegn02Rt00GroupA.InertiaCmpVelDampgSpdBlndY -> AAACalRegn02Rt00GroupA_Dummy.InertiaCmpVelDampgSpdBlndY
    connect CalRegn02Rt00GroupA.InertiaCmpVelDampgWhlImbRejctnBlndX -> AAACalRegn02Rt00GroupA_Dummy.InertiaCmpVelDampgWhlImbRejctnBlndX
    connect CalRegn02Rt00GroupA.InertiaCmpVelDampgWhlImbRejctnBlndY -> AAACalRegn02Rt00GroupA_Dummy.InertiaCmpVelDampgWhlImbRejctnBlndY
    connect CalRegn02Rt00GroupA.AssiMotTqWhlImbRejctnMaxX -> Assi.AssiMotTqWhlImbRejctnMaxX
    connect CalRegn02Rt00GroupA.AssiMotTqWhlImbRejctnMaxY -> Assi.AssiMotTqWhlImbRejctnMaxY
    connect CalRegn02Rt00GroupA.AssiMotTqWhlImbRejctnMinX -> Assi.AssiMotTqWhlImbRejctnMinX
    connect CalRegn02Rt00GroupA.AssiMotTqWhlImbRejctnMinY -> Assi.AssiMotTqWhlImbRejctnMinY
    connect CalRegn02Rt00GroupA.AssiWhlImbRejctnBlndScaX -> Assi.AssiWhlImbRejctnBlndScaX
    connect CalRegn02Rt00GroupA.AssiWhlImbRejctnBlndScaY -> Assi.AssiWhlImbRejctnBlndScaY
    connect CalRegn02Rt00GroupA.AssiHiFrqGainY -> AssiHiFrq.AssiHiFrqGainY
    connect CalRegn02Rt00GroupA.AssiHiFrqHpFilFrqY -> AssiHiFrq.AssiHiFrqHpFilFrqY
    connect CalRegn02Rt00GroupA.AssiHiFrqTqWhlImbRejctnTqX -> AssiHiFrq.AssiHiFrqTqWhlImbRejctnTqX
    connect CalRegn02Rt00GroupA.AssiHiFrqTqX -> AssiHiFrq.AssiHiFrqTqX
    connect CalRegn02Rt00GroupA.AssiHiFrqWhlImbRejctnBlndX -> AssiHiFrq.AssiHiFrqWhlImbRejctnBlndX
    connect CalRegn02Rt00GroupA.AssiHiFrqWhlImbRejctnBlndY -> AssiHiFrq.AssiHiFrqWhlImbRejctnBlndY
    connect CalRegn02Rt00GroupA.AssiHiFrqWhlImbRejctnGainY -> AssiHiFrq.AssiHiFrqWhlImbRejctnGainY
    connect CalRegn02Rt00GroupA.AssiMotTqWhlImbRejctnMinX -> CDD_FordBlaBoxIfCmp1.AssiMotTqWhlImbRejctnMinX
    connect CalRegn02Rt00GroupA.AssiMotTqWhlImbRejctnMinY -> CDD_FordBlaBoxIfCmp1.AssiMotTqWhlImbRejctnMinY
    connect CalRegn02Rt00GroupA.DampgHwTqX -> Dampg.DampgHwTqX
    connect CalRegn02Rt00GroupA.DampgHwTqY -> Dampg.DampgHwTqY
    connect CalRegn02Rt00GroupA.DampgHydCoeff{1..4}ScaY -> Dampg.DampgHydCoeff{1..4}ScaY
    connect CalRegn02Rt00GroupA.DampgMotVelX -> Dampg.DampgMotVelX
    connect CalRegn02Rt00GroupA.DampgMotVelY -> Dampg.DampgMotVelY
    connect CalRegn02Rt00GroupA.HysCmpEffLossY -> HysCmp.HysCmpEffLossY
    connect CalRegn02Rt00GroupA.HysCmpEffOffsY -> HysCmp.HysCmpEffOffsY
    connect CalRegn02Rt00GroupA.HysCmpFricWhlImbRejctnBlndX -> HysCmp.HysCmpFricWhlImbRejctnBlndX
    connect CalRegn02Rt00GroupA.HysCmpFricWhlImbRejctnBlndY -> HysCmp.HysCmpFricWhlImbRejctnBlndY
    connect CalRegn02Rt00GroupA.HysCmpFricWhlImbRejctnOffY -> HysCmp.HysCmpFricWhlImbRejctnOffY
    connect CalRegn02Rt00GroupA.HysCmpFricWhlImbRejctnOnY -> HysCmp.HysCmpFricWhlImbRejctnOnY
    connect CalRegn02Rt00GroupA.HysCmpHwTqScaX -> HysCmp.HysCmpHwTqScaX
    connect CalRegn02Rt00GroupA.HysCmpHwTqScaY -> HysCmp.HysCmpHwTqScaY
    connect CalRegn02Rt00GroupA.HysCmpHysSatnY -> HysCmp.HysCmpHysSatnY
    connect CalRegn02Rt00GroupA.HysCmpNegHysCmpScaX -> HysCmp.HysCmpNegHysCmpScaX
    connect CalRegn02Rt00GroupA.HysCmpNegHysCmpScaY -> HysCmp.HysCmpNegHysCmpScaY
    connect CalRegn02Rt00GroupA.HysCmpNegHysCmpX -> HysCmp.HysCmpNegHysCmpX
    connect CalRegn02Rt00GroupA.HysCmpNegHysCmpY -> HysCmp.HysCmpNegHysCmpY
    connect CalRegn02Rt00GroupA.HysCmpOutpLim -> HysCmp.HysCmpOutpLim
    connect CalRegn02Rt00GroupA.HysCmpRevGain -> HysCmp.HysCmpRevGain
    connect CalRegn02Rt00GroupA.HysCmpRiseX -> HysCmp.HysCmpRiseX
    connect CalRegn02Rt00GroupA.HysCmpRiseY -> HysCmp.HysCmpRiseY
    connect CalRegn02Rt00GroupA.InertiaCmpVelAssiBasdDampgStatY -> InertiaCmpVel.InertiaCmpVelAssiBasdDampgStatY
